VERSION "HNNBNNNYNNNNNNNNNNNNNNNNNNNNNNNNNNNNNNNNNN/4/%%%/4/'%**4NNN///"

NS_ :

BS_:

BU_: AFS Airbag Allrad BAP_Tester BMS_Hybrid Bremse_MK60EC Bremse_MK70MABS Bremse_TRW_EBC450M Bremse_TRW_ESP Daempfer EPB_TRW EPB_TRW_VW411CS FLA Gateway_PQ35 Gateway_Zusatz_EGolf Getriebe_AG6 Getriebe_DQ Getriebe_DQ_Hyb Getriebe_Sele Gurtmikro_PQ35 HCA Ladegeraet_EGolf LEH_Hybrid LH_EPS_APA LH_EPS_ZF_2G LH_EPS_ZF_3G LPG_Interface_Box LWR LWS Magne_Ride Motor_Diesel Motor_EGolf Motor_Hybrid Motor_Otto PDC_PLA Quersperre_VAQ RKA_Plus SAK Waehlhebel Waehlhebel_Sele

BO_ 1652 BAP_ACC: 8 Vector__XXX
 SG_ BAP_Data_ACC : 0|16@1+ (1,0) [0|65535] ""  Gateway_PQ35

BO_ 1654 BAP_Anzeige: 8 Gateway_PQ35
 SG_ BAP_Data_Anzeige : 0|16@1+ (1,0) [0|65535] ""  HCA,Motor_EGolf,Motor_Hybrid,PDC_PLA

BO_ 1658 BAP_Anzeige_02: 8 Gateway_PQ35
 SG_ BAP_Data_Anzeige_02 : 0|16@1+ (1,0) [0|65535] ""  Motor_EGolf,Motor_Hybrid,PDC_PLA

BO_ 1750 BAP_Debug_Cmd: 8 BAP_Tester
 SG_ BAP_Data_Debug_Cmd : 0|16@1+ (1,0) [0|65535] ""  HCA,Motor_EGolf,Motor_Hybrid,PDC_PLA

BO_ 1751 BAP_Debug_Data: 8 HCA
 SG_ BAP_Debug_Data : 0|64@1+ (1,0) [0|1.84467440737096E+019] ""  BAP_Tester

BO_ 1657 BAP_HYB: 8 Motor_EGolf
 SG_ BAP_Data_HYB : 0|16@1+ (1,0) [0|65535] ""  Gateway_PQ35

BO_ 1651 BAP_LDW: 8 HCA
 SG_ BAP_Data_LDW : 0|16@1+ (1,0) [0|65535] ""  Gateway_PQ35

BO_ 1754 BAP_OPS: 8 PDC_PLA
 SG_ BAP_Data_OPS : 0|16@1+ (1,0) [0|65535] ""  Gateway_PQ35

BO_ 946 BEM_03: 8 Gateway_PQ35
 SG_ BEM_HYB_DC_uMinLV : 12|8@1+ (0.1,0) [0|25.3] "Unit_Volt"  LEH_Hybrid
 SG_ BEM_HYB_DC_uSollLV : 20|6@1+ (0.1,10.6) [10.6|16] "Unit_Volt"  LEH_Hybrid

BO_ 901 Charisma_01: 8 Ladegeraet_EGolf
 SG_ CHA_Ziel_FahrPr_MO : 16|3@1+ (1,0) [0|7] ""  Motor_EGolf
 SG_ CHA_Ziel_FahrPr_GE : 20|3@1+ (1,0) [0|7] ""  Motor_EGolf

BO_ 902 Charisma_03: 8 Ladegeraet_EGolf
 SG_ CHA_Ziel_FahrPr_KL : 16|3@1+ (1,0) [0|7] ""  Gateway_Zusatz_EGolf
 SG_ CHA_Kombi_Texte : 24|4@1+ (1,0) [0|15] ""  Gateway_Zusatz_EGolf

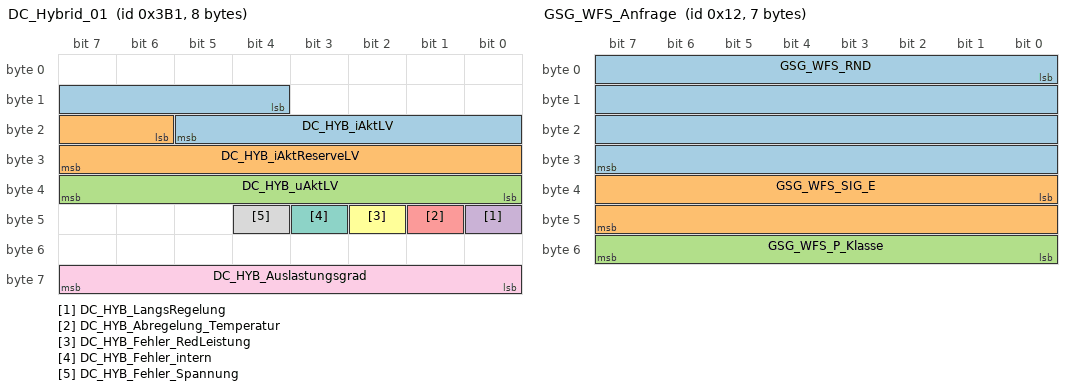
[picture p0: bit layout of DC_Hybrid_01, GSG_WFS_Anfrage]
BO_ 945 DC_Hybrid_01: 8 LEH_Hybrid
 SG_ DC_HYB_iAktLV : 12|10@1+ (1,-511) [-511|510] "Unit_Amper"  Gateway_PQ35
 SG_ DC_HYB_iAktReserveLV : 22|10@1+ (1,-511) [-511|510] "Unit_Amper"  Gateway_PQ35
 SG_ DC_HYB_uAktLV : 32|8@1+ (0.1,0) [0|25.3] "Unit_Volt"  Gateway_PQ35
 SG_ DC_HYB_LangsRegelung : 40|1@1+ (1,0) [0|1] ""  Gateway_PQ35
 SG_ DC_HYB_Abregelung_Temperatur : 41|1@1+ (1,0) [0|1] ""  Gateway_PQ35
 SG_ DC_HYB_Fehler_RedLeistung : 42|1@1+ (1,0) [0|1] ""  Gateway_PQ35
 SG_ DC_HYB_Fehler_intern : 43|1@1+ (1,0) [0|1] ""  Gateway_PQ35
 SG_ DC_HYB_Fehler_Spannung : 44|1@1+ (1,0) [0|1] ""  Gateway_PQ35
 SG_ DC_HYB_Auslastungsgrad : 56|8@1+ (0.4,0) [0|100] "Unit_PerCent"  Gateway_PQ35

BO_ 18 GSG_WFS_Anfrage: 7 Vector__XXX
 SG_ GSG_WFS_RND : 0|32@1+ (1,0) [0|4294967295] ""  Gateway_PQ35
 SG_ GSG_WFS_SIG_E : 32|16@1+ (1,0) [0|65535] ""  Gateway_PQ35
 SG_ GSG_WFS_P_Klasse : 48|8@1+ (1,0) [0|255] ""  Gateway_PQ35

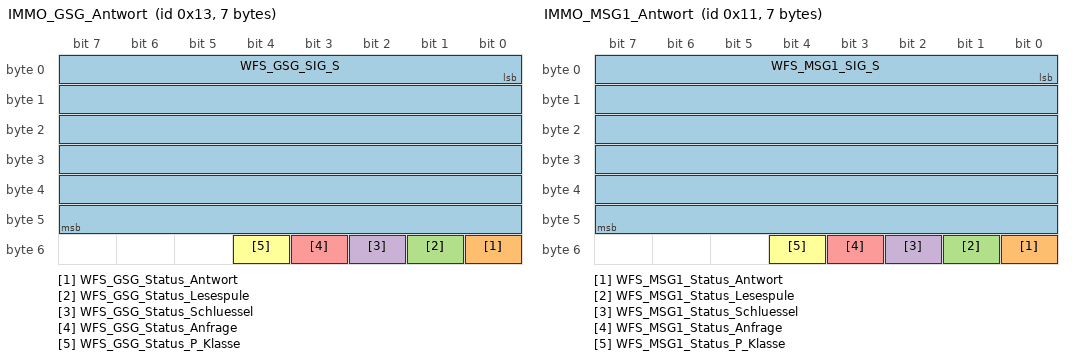
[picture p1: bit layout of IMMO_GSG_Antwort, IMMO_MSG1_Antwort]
BO_ 19 IMMO_GSG_Antwort: 7 Gateway_PQ35
 SG_ WFS_GSG_SIG_S : 0|48@1+ (1,0) [0|281474976710655] "" Vector__XXX
 SG_ WFS_GSG_Status_Antwort : 48|1@1+ (1,0) [0|1] "" Vector__XXX
 SG_ WFS_GSG_Status_Lesespule : 49|1@1+ (1,0) [0|1] "" Vector__XXX
 SG_ WFS_GSG_Status_Schluessel : 50|1@1+ (1,0) [0|1] "" Vector__XXX
 SG_ WFS_GSG_Status_Anfrage : 51|1@1+ (1,0) [0|1] "" Vector__XXX
 SG_ WFS_GSG_Status_P_Klasse : 52|1@1+ (1,0) [0|1] "" Vector__XXX

BO_ 17 IMMO_MSG1_Antwort: 7 Gateway_PQ35
 SG_ WFS_MSG1_SIG_S : 0|48@1+ (1,0) [0|281474976710655] "" Vector__XXX
 SG_ WFS_MSG1_Status_Antwort : 48|1@1+ (1,0) [0|1] "" Vector__XXX
 SG_ WFS_MSG1_Status_Lesespule : 49|1@1+ (1,0) [0|1] "" Vector__XXX
 SG_ WFS_MSG1_Status_Schluessel : 50|1@1+ (1,0) [0|1] "" Vector__XXX
 SG_ WFS_MSG1_Status_Anfrage : 51|1@1+ (1,0) [0|1] "" Vector__XXX
 SG_ WFS_MSG1_Status_P_Klasse : 52|1@1+ (1,0) [0|1] "" Vector__XXX

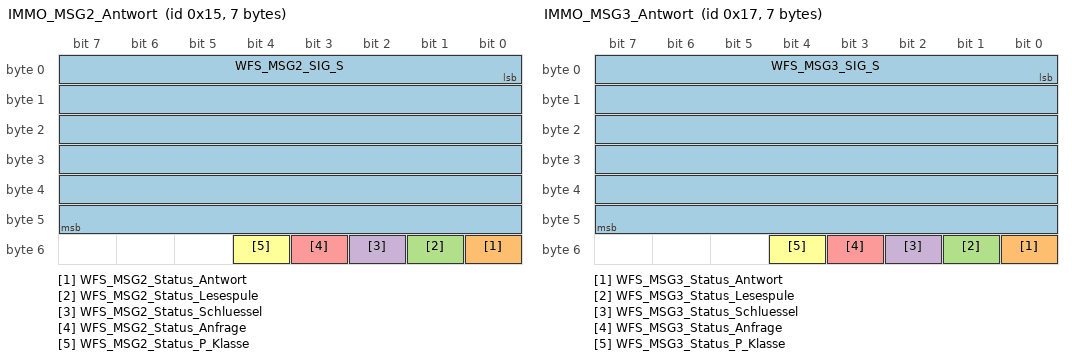
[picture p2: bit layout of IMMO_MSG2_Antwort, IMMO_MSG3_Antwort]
BO_ 21 IMMO_MSG2_Antwort: 7 Gateway_PQ35
 SG_ WFS_MSG2_SIG_S : 0|48@1+ (1,0) [0|281474976710655] "" Vector__XXX
 SG_ WFS_MSG2_Status_Antwort : 48|1@1+ (1,0) [0|1] "" Vector__XXX
 SG_ WFS_MSG2_Status_Lesespule : 49|1@1+ (1,0) [0|1] "" Vector__XXX
 SG_ WFS_MSG2_Status_Schluessel : 50|1@1+ (1,0) [0|1] "" Vector__XXX
 SG_ WFS_MSG2_Status_Anfrage : 51|1@1+ (1,0) [0|1] "" Vector__XXX
 SG_ WFS_MSG2_Status_P_Klasse : 52|1@1+ (1,0) [0|1] "" Vector__XXX

BO_ 23 IMMO_MSG3_Antwort: 7 Gateway_PQ35
 SG_ WFS_MSG3_SIG_S : 0|48@1+ (1,0) [0|281474976710655] "" Vector__XXX
 SG_ WFS_MSG3_Status_Antwort : 48|1@1+ (1,0) [0|1] "" Vector__XXX
 SG_ WFS_MSG3_Status_Lesespule : 49|1@1+ (1,0) [0|1] "" Vector__XXX
 SG_ WFS_MSG3_Status_Schluessel : 50|1@1+ (1,0) [0|1] "" Vector__XXX
 SG_ WFS_MSG3_Status_Anfrage : 51|1@1+ (1,0) [0|1] "" Vector__XXX
 SG_ WFS_MSG3_Status_P_Klasse : 52|1@1+ (1,0) [0|1] "" Vector__XXX

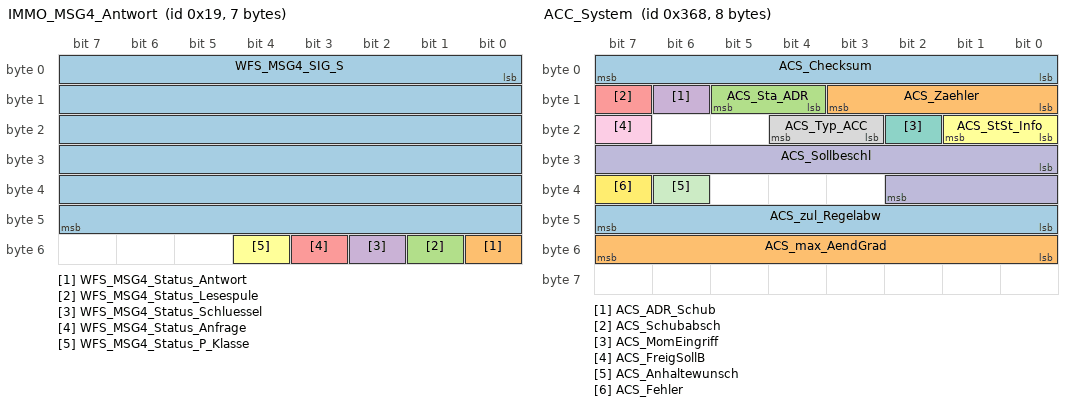
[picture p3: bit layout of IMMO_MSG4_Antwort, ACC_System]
BO_ 25 IMMO_MSG4_Antwort: 7 Gateway_PQ35
 SG_ WFS_MSG4_SIG_S : 0|48@1+ (1,0) [0|281474976710655] "" Vector__XXX
 SG_ WFS_MSG4_Status_Antwort : 48|1@1+ (1,0) [0|1] "" Vector__XXX
 SG_ WFS_MSG4_Status_Lesespule : 49|1@1+ (1,0) [0|1] "" Vector__XXX
 SG_ WFS_MSG4_Status_Schluessel : 50|1@1+ (1,0) [0|1] "" Vector__XXX
 SG_ WFS_MSG4_Status_Anfrage : 51|1@1+ (1,0) [0|1] "" Vector__XXX
 SG_ WFS_MSG4_Status_P_Klasse : 52|1@1+ (1,0) [0|1] "" Vector__XXX

BO_ 1811 ISO_ABS_Req: 8 Gateway_PQ35
 SG_ ISO_ABS_Req_Data : 0|64@1+ (1,0) [0|1.84467440737096E+019] "" Vector__XXX

BO_ 1917 ISO_ABS_Resp: 8 Vector__XXX
 SG_ ISO_ABS_Resp_Data : 0|64@1+ (1,0) [0|1.84467440737096E+019] ""  Gateway_PQ35

BO_ 1879 ISO_ACC_Req: 8 Gateway_PQ35
 SG_ ISO_ACC_Req_Data : 0|64@1+ (1,0) [0|1.84467440737096E+019] "" Vector__XXX

BO_ 1985 ISO_ACC_Resp: 8 Vector__XXX
 SG_ ISO_ACC_Resp_Data : 0|64@1+ (1,0) [0|1.84467440737096E+019] ""  Gateway_PQ35

BO_ 1813 ISO_Airbag_01_Req: 8 Gateway_PQ35
 SG_ ISO_Airbag_01_Req_Data : 0|64@1+ (1,0) [0|1.84467440737096E+019] ""  Airbag

BO_ 1919 ISO_Airbag_01_Resp: 8 Airbag
 SG_ ISO_Airbag_01_Resp_Data : 0|64@1+ (1,0) [0|1.84467440737096E+019] ""  Gateway_PQ35

BO_ 1874 ISO_EPB_Req: 8 Gateway_PQ35
 SG_ ISO_EPB_Req_Data : 0|64@1+ (1,0) [0|1.84467440737096E+019] ""  EPB_TRW_VW411CS,RKA_Plus

BO_ 1980 ISO_EPB_Resp: 8 EPB_TRW_VW411CS
 SG_ ISO_EPB_Resp_Data : 0|64@1+ (1,0) [0|1.84467440737096E+019] ""  Gateway_PQ35

BO_ 1802 ISO_EPH_Req: 8 Gateway_PQ35
 SG_ ISO_EPH_Req_Data : 0|64@1+ (1,0) [0|1.84467440737096E+019] ""  PDC_PLA

BO_ 1908 ISO_EPH_Resp: 8 PDC_PLA
 SG_ ISO_EPH_Resp_Data : 0|64@1+ (1,0) [0|1.84467440737096E+019] ""  Gateway_PQ35

BO_ 1792 ISO_Funktionaler_Req_All: 8 Gateway_PQ35
 SG_ ISO_ALL_01_Req_Data : 0|64@1+ (1,0) [0|1.84467440737096E+019] ""  AFS,Airbag,BMS_Hybrid,EPB_TRW_VW411CS,Getriebe_AG6,Getriebe_DQ,Getriebe_DQ_Hyb,Getriebe_Sele,Gurtmikro_PQ35,Ladegeraet_EGolf,LEH_Hybrid,LH_EPS_ZF_3G,Motor_Diesel,Motor_EGolf,Motor_Hybrid,Motor_Otto,PDC_PLA

BO_ 2015 ISO_Funktionaler_Req_OBD: 8 Gateway_PQ35
 SG_ ISO_OBD_01_Req_Data : 0|64@1+ (1,0) [0|1.84467440737096E+019] ""  BMS_Hybrid,Getriebe_AG6,Getriebe_DQ,Getriebe_DQ_Hyb,Getriebe_Sele,LEH_Hybrid,Motor_Diesel,Motor_EGolf,Motor_Hybrid,Motor_Otto

BO_ 2017 ISO_Getriebe_01_Req: 8 Gateway_PQ35
 SG_ ISO_Getriebe_01_Req_Data : 0|64@1+ (1,0) [0|1.84467440737096E+019] ""  Getriebe_AG6,Getriebe_DQ,Getriebe_DQ_Hyb,Getriebe_Sele

BO_ 2025 ISO_Getriebe_01_Resp: 8 Getriebe_AG6
 SG_ ISO_Getriebe_01_Resp_Data : 0|64@1+ (1,0) [0|1.84467440737096E+019] ""  Gateway_PQ35

BO_ 1891 ISO_Gurtmikro_Req: 8 Gateway_PQ35
 SG_ ISO_Gurtmikro_Req_Data : 0|64@1+ (1,0) [0|1.84467440737096E+019] ""  Gurtmikro_PQ35

BO_ 1997 ISO_Gurtmikro_Resp: 8 Gurtmikro_PQ35
 SG_ ISO_Gurtmikro_Resp_Data : 0|64@1+ (1,0) [0|1.84467440737096E+019] ""  Gateway_PQ35

BO_ 1893 ISO_Ladegeraet_Req: 8 Gateway_Zusatz_EGolf
 SG_ ISO_Ladegeraet_Req_Data : 0|64@1+ (1,0) [0|1.84467440737096E+019] ""  Ladegeraet_EGolf

BO_ 1999 ISO_Ladegeraet_Resp: 8 Ladegeraet_EGolf
 SG_ ISO_Ladegeraet_Resp_Data : 0|64@1+ (1,0) [0|1.84467440737096E+019] ""  Gateway_Zusatz_EGolf

BO_ 1810 ISO_Lenkhilfe_Req: 8 Gateway_PQ35
 SG_ ISO_Lenkhilfe_Req_Data : 0|64@1+ (1,0) [0|1.84467440737096E+019] ""  LH_EPS_ZF_3G

BO_ 1916 ISO_Lenkhilfe_Resp: 8 LH_EPS_ZF_3G
 SG_ ISO_Lenkhilfe_Resp_Data : 0|64@1+ (1,0) [0|1.84467440737096E+019] ""  Gateway_PQ35

BO_ 1876 ISO_LWRAFS_Req: 8 Gateway_PQ35
 SG_ ISO_LWRAFS_Req_Data : 0|64@1+ (1,0) [0|1.84467440737096E+019] ""  AFS

BO_ 1982 ISO_LWRAFS_Resp: 8 AFS
 SG_ ISO_LWRAFS_Resp_Data : 0|64@1+ (1,0) [0|1.84467440737096E+019] ""  Gateway_PQ35

BO_ 2016 ISO_MO_01_Req: 8 Gateway_PQ35
 SG_ ISO_MO_01_Req_Data : 0|64@1+ (1,0) [0|1.84467440737096E+019] ""  Motor_Diesel,Motor_EGolf,Motor_Hybrid,Motor_Otto

BO_ 2024 ISO_MO_01_Resp: 8 Motor_Diesel
 SG_ ISO_MO_01_Resp_Data : 0|64@1+ (1,0) [0|1.84467440737096E+019] ""  Gateway_PQ35

BO_ 2018 ISO_MOS_01_Req: 8 Gateway_PQ35
 SG_ ISO_MOS_01_Req_Data : 0|64@1+ (1,0) [0|1.84467440737096E+019] "" Vector__XXX

BO_ 2026 ISO_MOS_01_Resp: 8 Vector__XXX
 SG_ ISO_MOS_01_Resp_Data : 0|64@1+ (1,0) [0|1.84467440737096E+019] ""  Gateway_PQ35

BO_ 2021 ISO_OBD_BECM_Req: 8 Gateway_PQ35
 SG_ ISO_OBD_BECM_Req_Data : 0|64@1+ (1,0) [0|1.84467440737096E+019] ""  BMS_Hybrid

BO_ 2029 ISO_OBD_BECM_Resp: 8 BMS_Hybrid
 SG_ ISO_OBD_BECM_Resp_Data : 0|64@1+ (1,0) [0|1.84467440737096E+019] ""  Gateway_PQ35

BO_ 2022 ISO_OBD_DMCM_Req: 8 Gateway_PQ35
 SG_ ISO_OBD_DMCM_Req_Data : 0|64@1+ (1,0) [0|1.84467440737096E+019] ""  LEH_Hybrid

BO_ 2030 ISO_OBD_DMCM_Resp: 8 LEH_Hybrid
 SG_ ISO_OBD_DMCM_Resp_Data : 0|64@1+ (1,0) [0|1.84467440737096E+019] ""  Gateway_PQ35

BO_ 2019 ISO_OBD_reserv1_Req: 8 Gateway_PQ35
 SG_ ISO_OBD_reserv1_Req_Data : 0|64@1+ (1,0) [0|1.84467440737096E+019] "" Vector__XXX

BO_ 2027 ISO_OBD_reserv1_Resp: 8 Vector__XXX
 SG_ ISO_OBD_reserv1_Resp_Data : 0|64@1+ (1,0) [0|1.84467440737096E+019] ""  Gateway_PQ35

BO_ 2020 ISO_OBD_reserv2_Req: 8 Gateway_PQ35
 SG_ ISO_OBD_reserv2_Req_Data : 0|64@1+ (1,0) [0|1.84467440737096E+019] "" Vector__XXX

BO_ 2028 ISO_OBD_reserv2_Resp: 8 Vector__XXX
 SG_ ISO_OBD_reserv2_Resp_Data : 0|64@1+ (1,0) [0|1.84467440737096E+019] ""  Gateway_PQ35

BO_ 2023 ISO_OBD_reserv5_Req: 8 Gateway_PQ35
 SG_ ISO_OBD_reserv5_Req_Data : 0|64@1+ (1,0) [0|1.84467440737096E+019] "" Vector__XXX

BO_ 2031 ISO_OBD_reserv5_Resp: 8 Vector__XXX
 SG_ ISO_OBD_reserv5_Resp_Data : 0|64@1+ (1,0) [0|1.84467440737096E+019] ""  Gateway_PQ35

BO_ 1386 ACC_GRA_Anzeige: 8 Gateway_PQ35
 SG_ ACA_Checksum : 0|8@1+ (1,0) [0|255] ""  Gateway_PQ35
 SG_ ACA_StaACC : 8|3@1+ (1,0) [0|7] ""  Gateway_PQ35
 SG_ ACA_ID_StaACC : 11|5@1+ (1,0) [0|31] ""  Gateway_PQ35
 SG_ ACA_Fahrerhinw : 16|1@1+ (1,0) [0|1] ""  Gateway_PQ35
 SG_ ACA_AnzDisplay : 17|1@1+ (1,0) [0|1] ""  Gateway_PQ35
 SG_ ACA_Zeitluecke : 18|4@1+ (1,0) [0|15] ""  Gateway_PQ35
 SG_ ACA_V_Wunsch : 24|8@1+ (1,0) [0|254] "Unit_KiloMeterPerHour"  Gateway_PQ35,Getriebe_AG6,Getriebe_DQ,Getriebe_DQ_Hyb
 SG_ ACA_kmh_mph : 32|1@1+ (1,0) [0|1] ""  Gateway_PQ35
 SG_ ACA_Akustik1 : 33|1@1+ (1,0) [0|1] ""  Gateway_PQ35
 SG_ ACA_Akustik2 : 34|1@1+ (1,0) [0|1] ""  Gateway_PQ35
 SG_ ACA_PrioDisp : 35|2@1+ (1,0) [0|3] ""  Gateway_PQ35
 SG_ ACA_gemZeitl : 40|4@1+ (1,0) [0|15] ""  Gateway_PQ35
 SG_ ACA_ACC_Verz : 44|1@1+ (1,0) [0|1] ""  Gateway_PQ35
 SG_ ACA_StaGRA : 48|3@1+ (1,0) [0|7] ""  Gateway_PQ35
 SG_ ACA_ID_StaGRA : 51|5@1+ (1,0) [0|31] ""  Gateway_PQ35
 SG_ ACA_Codierung : 56|1@1+ (1,0) [0|1] ""  Gateway_PQ35,Getriebe_DQ
 SG_ ACA_Tachokranz : 57|1@1+ (1,0) [0|1] ""  Gateway_PQ35
 SG_ ACA_Aend_Zeitluecke : 58|1@1+ (1,0) [0|1] ""  Gateway_PQ35
 SG_ ACA_Zaehler : 60|4@1+ (1,0) [0|15] ""  Gateway_PQ35

BO_ 872 ACC_System: 8 Gateway_PQ35
 SG_ ACS_Checksum : 0|8@1+ (1,0) [0|255] ""  Daempfer,Getriebe_DQ,Motor_Diesel,Motor_Otto
 SG_ ACS_Zaehler : 8|4@1+ (1,0) [0|15] ""  Daempfer,Getriebe_DQ,Motor_Diesel,Motor_Otto
 SG_ ACS_Sta_ADR : 12|2@1+ (1,0) [0|3] ""  Getriebe_AG6,Getriebe_DQ,Motor_Diesel,Motor_Otto
 SG_ ACS_ADR_Schub : 14|1@1+ (1,0) [0|1] ""  Getriebe_AG6,Getriebe_DQ,Motor_Diesel,Motor_Otto
 SG_ ACS_Schubabsch : 15|1@1+ (1,0) [0|1] ""  Getriebe_AG6,Getriebe_DQ,Motor_Diesel,Motor_Otto
 SG_ ACS_StSt_Info : 16|2@1+ (1,0) [0|3] ""  Motor_Diesel,Motor_Otto
 SG_ ACS_MomEingriff : 18|1@1+ (1,0) [0|1] ""  Getriebe_AG6,Getriebe_DQ,Motor_Diesel,Motor_Otto
 SG_ ACS_Typ_ACC : 19|2@1+ (1,0) [0|3] ""  Getriebe_AG6,Getriebe_DQ,Motor_Diesel,Motor_Otto
 SG_ ACS_FreigSollB : 23|1@1+ (1,0) [0|1] ""  Daempfer,Getriebe_AG6,Getriebe_DQ,Motor_Diesel,Motor_Otto
 SG_ ACS_Sollbeschl : 24|11@1+ (0.005,-7.22) [-7.22|3.005] "Unit_MeterPerSeconSquar"  Daempfer,Getriebe_AG6,Getriebe_DQ,Motor_Diesel,Motor_Otto
 SG_ ACS_Anhaltewunsch : 38|1@1+ (1,0) [0|1] ""  Motor_Diesel,Motor_Otto
 SG_ ACS_Fehler : 39|1@1+ (1,0) [0|1] ""  Gateway_PQ35
 SG_ ACS_zul_Regelabw : 40|8@1+ (0.005,0) [0|1.265] "Unit_MeterPerSeconSquar"  Motor_Diesel,Motor_Otto
 SG_ ACS_max_AendGrad : 48|8@1+ (0.02,0) [0.02|5.06] "Unit_MeterPerSeconSquar"  Motor_Diesel,Motor_Otto

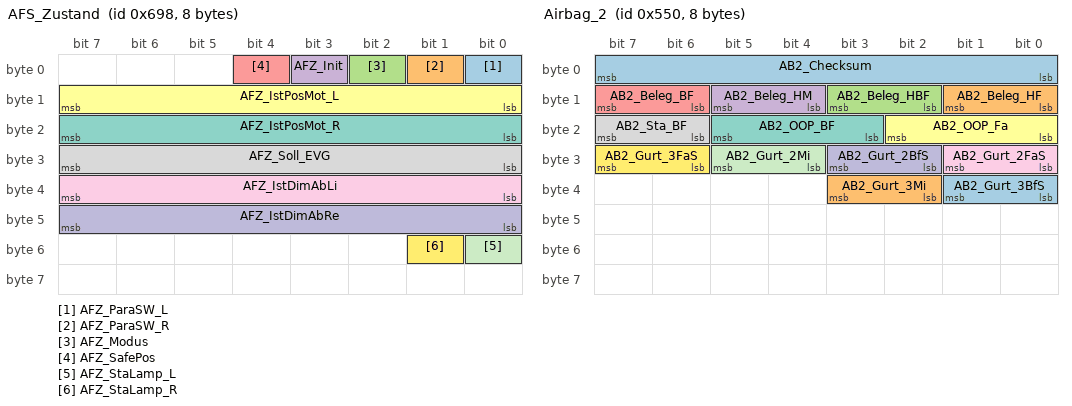
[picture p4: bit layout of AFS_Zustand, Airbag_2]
BO_ 1688 AFS_Zustand: 8 AFS
 SG_ AFZ_ParaSW_L : 0|1@1+ (1,0) [0|1] "" Vector__XXX
 SG_ AFZ_ParaSW_R : 1|1@1+ (1,0) [0|1] "" Vector__XXX
 SG_ AFZ_Modus : 2|1@1+ (1,0) [0|1] "" Vector__XXX
 SG_ AFZ_Init : 3|1@1+ (1,0) [0|1] "" Vector__XXX
 SG_ AFZ_SafePos : 4|1@1+ (1,0) [0|1] "" Vector__XXX
 SG_ AFZ_IstPosMot_L : 8|8@1+ (0.4,0) [0|100] "Unit_PerCent" Vector__XXX
 SG_ AFZ_IstPosMot_R : 16|8@1+ (0.4,0) [0|100] "Unit_PerCent" Vector__XXX
 SG_ AFZ_Soll_EVG : 24|8@1+ (0.4,0) [0|100] "Unit_PerCent" Vector__XXX
 SG_ AFZ_IstDimAbLi : 32|8@1+ (0.4,0) [0|100] "Unit_PerCent" Vector__XXX
 SG_ AFZ_IstDimAbRe : 40|8@1+ (0.4,0) [0|100] "Unit_PerCent" Vector__XXX
 SG_ AFZ_StaLamp_L : 48|1@1+ (1,0) [0|1] "" Vector__XXX
 SG_ AFZ_StaLamp_R : 49|1@1+ (1,0) [0|1] "" Vector__XXX

BO_ 80 Airbag_1: 4 Airbag
 SG_ AB1_Front : 0|1@1+ (1,0) [0|1] ""  BMS_Hybrid,Bremse_TRW_EBC450M,Bremse_TRW_ESP,EPB_TRW,Gateway_PQ35,HCA,LEH_Hybrid
 SG_ AB1_Heck : 1|1@1+ (1,0) [0|1] ""  BMS_Hybrid,Bremse_TRW_EBC450M,Bremse_TRW_ESP,EPB_TRW,Gateway_PQ35,HCA,LEH_Hybrid
 SG_ AB1_Fa_Seite : 2|1@1+ (1,0) [0|1] ""  BMS_Hybrid,Bremse_TRW_EBC450M,Bremse_TRW_ESP,EPB_TRW,Gateway_PQ35,HCA,LEH_Hybrid
 SG_ AB1_Bf_Seite : 3|1@1+ (1,0) [0|1] ""  BMS_Hybrid,Bremse_TRW_EBC450M,Bremse_TRW_ESP,EPB_TRW,Gateway_PQ35,HCA,LEH_Hybrid
 SG_ AB1_Rollover : 4|1@1+ (1,0) [0|1] ""  Bremse_MK60EC,Bremse_MK70MABS,Bremse_TRW_EBC450M,Bremse_TRW_ESP,EPB_TRW,Gateway_PQ35
 SG_ AB1_Intens : 5|3@1+ (1,0) [0|7] ""  Bremse_MK60EC,Bremse_MK70MABS,Gateway_PQ35,Gurtmikro_PQ35,LEH_Hybrid,Motor_Diesel,Motor_EGolf,Motor_Hybrid,Motor_Otto
 SG_ AB1_Lampe : 8|1@1+ (1,0) [0|1] ""  Gateway_PQ35
 SG_ AB1_Status : 9|1@1+ (1,0) [0|1] ""  Gateway_PQ35
 SG_ AB1_Beifahrer : 10|1@1+ (1,0) [0|1] ""  Gateway_PQ35
 SG_ AB1_System : 11|1@1+ (1,0) [0|1] ""  BMS_Hybrid,Gateway_PQ35,HCA,LEH_Hybrid
 SG_ AB1_Gurt_Fa : 12|2@1+ (1,0) [0|3] ""  Bremse_MK60EC,Bremse_TRW_EBC450M,Bremse_TRW_ESP,EPB_TRW,EPB_TRW_VW411CS,Gateway_PQ35,Gurtmikro_PQ35,Motor_Diesel,Motor_EGolf,Motor_Hybrid,Motor_Otto
 SG_ AB1_Gurt_Bf : 14|2@1+ (1,0) [0|3] ""  Gateway_PQ35,Gurtmikro_PQ35
 SG_ AB1_Diagnose : 16|1@1+ (1,0) [0|1] ""  EPB_TRW,Gateway_PQ35
 SG_ AB1_Stellglied : 17|1@1+ (1,0) [0|1] ""  BMS_Hybrid,Gateway_PQ35,LEH_Hybrid,Motor_Diesel,Motor_Otto
 SG_ AB1_BF_Warnung : 18|1@1+ (1,0) [0|1] ""  Gateway_PQ35
 SG_ AB1_Fehlereintr : 19|1@1+ (1,0) [0|1] ""  Gateway_PQ35
 SG_ AB1_Zaehler : 20|4@1+ (1,0) [0|15] ""  BMS_Hybrid,Bremse_MK60EC,Bremse_TRW_EBC450M,Bremse_TRW_ESP,EPB_TRW,EPB_TRW_VW411CS,Gateway_PQ35,HCA,LEH_Hybrid,Motor_Diesel,Motor_EGolf,Motor_Hybrid,Motor_Otto
 SG_ AB1_Checksumme : 24|8@1+ (1,0) [0|255] ""  BMS_Hybrid,Bremse_MK60EC,Bremse_TRW_EBC450M,Bremse_TRW_ESP,EPB_TRW,EPB_TRW_VW411CS,Gateway_PQ35,HCA,LEH_Hybrid,Motor_Diesel,Motor_EGolf,Motor_Hybrid,Motor_Otto

BO_ 1360 Airbag_2: 8 Airbag
 SG_ AB2_Checksum : 0|8@1+ (1,0) [0|255] ""  Gateway_PQ35
 SG_ AB2_Beleg_HF : 8|2@1+ (1,0) [0|3] ""  Gateway_PQ35
 SG_ AB2_Beleg_HBF : 10|2@1+ (1,0) [0|3] ""  Gateway_PQ35
 SG_ AB2_Beleg_HM : 12|2@1+ (1,0) [0|3] ""  Gateway_PQ35
 SG_ AB2_Beleg_BF : 14|2@1+ (1,0) [0|3] ""  Gateway_PQ35,Gurtmikro_PQ35
 SG_ AB2_OOP_Fa : 16|3@1+ (1,0) [0|7] ""  Gateway_PQ35
 SG_ AB2_OOP_BF : 19|3@1+ (1,0) [0|7] ""  Gateway_PQ35
 SG_ AB2_Sta_BF : 22|2@1+ (1,0) [0|3] ""  Gateway_PQ35
 SG_ AB2_Gurt_2FaS : 24|2@1+ (1,0) [0|3] ""  Gateway_PQ35
 SG_ AB2_Gurt_2BfS : 26|2@1+ (1,0) [0|3] ""  Gateway_PQ35
 SG_ AB2_Gurt_2Mi : 28|2@1+ (1,0) [0|3] ""  Gateway_PQ35
 SG_ AB2_Gurt_3FaS : 30|2@1+ (1,0) [0|3] ""  Gateway_PQ35
 SG_ AB2_Gurt_3BfS : 32|2@1+ (1,0) [0|3] ""  Gateway_PQ35
 SG_ AB2_Gurt_3Mi : 34|2@1+ (1,0) [0|3] ""  Gateway_PQ35

BO_ 704 Allrad_1: 8 Allrad
 SG_ AL1_Fehler : 0|1@1+ (1,0) [0|1] ""  Bremse_MK60EC,Bremse_TRW_EBC450M,Bremse_TRW_ESP,Gateway_PQ35,RKA_Plus
 SG_ AL1_Uebertemp : 1|1@1+ (1,0) [0|1] ""  Bremse_TRW_EBC450M,Bremse_TRW_ESP,Gateway_PQ35
 SG_ AL1_Sta_Kup : 2|1@1+ (1,0) [0|1] ""  Bremse_MK60EC,Bremse_TRW_EBC450M,Bremse_TRW_ESP,Gateway_PQ35
 SG_ AL1_Kup_offen : 3|1@1+ (1,0) [0|1] ""  Bremse_TRW_EBC450M,Bremse_TRW_ESP,Gateway_PQ35,RKA_Plus
 SG_ AL1_Notlauf : 4|1@1+ (1,0) [0|1] ""  Bremse_TRW_EBC450M,Bremse_TRW_ESP,Gateway_PQ35
 SG_ AL1_Warnlampe : 5|1@1+ (1,0) [0|1] ""  Bremse_TRW_EBC450M,Bremse_TRW_ESP,Gateway_PQ35
 SG_ AL1_Limiter : 6|1@1+ (1,0) [0|1] ""  Gateway_PQ35
 SG_ AL1_Einheit M : 7|1@1+ (1,0) [0|1] ""  Bremse_MK60EC,Bremse_TRW_EBC450M,Bremse_TRW_ESP,Gateway_PQ35,RKA_Plus
 SG_ AL1_Ist_Nm m0 : 8|8@1+ (7,-896) [-896|882] "Unit_NewtoMeter"  Bremse_MK60EC,Bremse_TRW_EBC450M,Bremse_TRW_ESP,Gateway_PQ35,RKA_Plus
 SG_ AL1_Ist_Proz m1 : 8|8@1+ (0.794,-101.632) [0|100.044] "Unit_PerCent"  Bremse_MK60EC,Bremse_TRW_EBC450M,Bremse_TRW_ESP,Gateway_PQ35,RKA_Plus
 SG_ AL1_Sta_PNG : 16|3@1+ (1,0) [0|7] ""  Bremse_MK60EC,Gateway_PQ35,Getriebe_DQ,Getriebe_DQ_Hyb
 SG_ AL1_Anz_blinken : 19|1@1+ (1,0) [0|1] ""  Gateway_PQ35
 SG_ AL1_Sta_Laengssp : 20|2@1+ (1,0) [0|3] ""  Gateway_PQ35
 SG_ AL1_Sta_Quersp : 22|2@1+ (1,0) [0|3] ""  Gateway_PQ35
 SG_ AL1_Schalten : 24|1@1+ (1,0) [0|1] ""  Gateway_PQ35
 SG_ AL1_Vorwarnung : 25|1@1+ (1,0) [0|1] ""  Gateway_PQ35,Getriebe_DQ,Getriebe_DQ_Hyb
 SG_ AL1_Stellung_Getr : 26|1@1+ (1,0) [0|1] ""  Bremse_MK60EC,Gateway_PQ35
 SG_ AL1_AnfVerteiler : 27|1@1+ (1,0) [0|1] ""  Gateway_PQ35
 SG_ AL1_Sta_VA : 28|2@1+ (1,0) [0|3] ""  Gateway_PQ35
 SG_ AL1_KupSteifig_F : 30|1@1+ (1,0) [0|1] ""  Gateway_PQ35
 SG_ AL1_Fehlereintr : 31|1@1+ (1,0) [0|1] ""  Gateway_PQ35
 SG_ AL1_KupplTemp : 32|8@1+ (1,-60) [-60|193] "Unit_DegreCelsi"  Gateway_PQ35
 SG_ AL1_FaWu_Laengs : 40|2@1+ (1,0) [0|3] ""  Gateway_PQ35
 SG_ AL1_FaWu_HA : 42|2@1+ (1,0) [0|3] ""  Gateway_PQ35
 SG_ AL1_FaWu_VA : 44|2@1+ (1,0) [0|3] ""  Gateway_PQ35
 SG_ AL1_Quersp_Sta : 46|2@1+ (1,0) [0|3] ""  Gateway_PQ35
 SG_ AL1_Limit_maxkmh : 48|8@1+ (1,0) [0|254] ""  Gateway_PQ35
 SG_ AL1_Diff_Verbau : 56|1@1+ (1,0) [0|1] ""  Gateway_PQ35
 SG_ AL1_Diff_Lampe : 57|1@1+ (1,0) [0|1] ""  Gateway_PQ35
 SG_ AL1_Diff_Gong : 58|1@1+ (1,0) [0|1] ""  Gateway_PQ35
 SG_ AL1_Warnton : 59|1@1+ (1,0) [0|1] ""  Gateway_PQ35
 SG_ AL1_Zaehler : 60|4@1+ (1,0) [0|15] ""  Bremse_TRW_EBC450M,Bremse_TRW_ESP,Gateway_PQ35

BO_ 870 AWV: 8 Gateway_PQ35
 SG_ AWV_Checksumme : 0|8@1+ (1,0) [0|255] ""  Bremse_TRW_EBC450M,Bremse_TRW_ESP,Daempfer,Gateway_PQ35,HCA
 SG_ AWV_Zaehler : 8|4@1+ (1,0) [0|15] ""  Bremse_TRW_EBC450M,Bremse_TRW_ESP,Daempfer,Gateway_PQ35,HCA
 SG_ AWV_Text : 12|4@1+ (1,0) [0|15] ""  Gateway_PQ35
 SG_ AWV_1_Freigabe : 16|1@1+ (1,0) [0|1] ""  Bremse_TRW_EBC450M,Bremse_TRW_ESP,Gateway_PQ35
 SG_ AWV_1_Prefill : 17|1@1+ (1,0) [0|1] ""  Bremse_TRW_EBC450M,Bremse_TRW_ESP,Gateway_PQ35
 SG_ AWV_1_Parameter : 18|2@1+ (1,0) [0|3] ""  Bremse_TRW_EBC450M,Bremse_TRW_ESP,Gateway_PQ35
 SG_ AWV_Halten : 22|1@1+ (1,0) [0|1] ""  Bremse_TRW_EBC450M,Gateway_PQ35
 SG_ ANB_Teilbremsung_Freigabe : 23|1@1+ (1,0) [0|1] ""  Bremse_TRW_EBC450M,Daempfer,Gateway_PQ35
 SG_ AWV_2_Status : 24|1@1+ (1,0) [0|1] ""  Gateway_PQ35
 SG_ AWV_2_Fehler : 25|1@1+ (1,0) [0|1] ""  Gateway_PQ35
 SG_ AWV_2_SU_Warnzeit : 26|2@1+ (1,0) [0|3] ""  Gateway_PQ35
 SG_ AWV_2_SU_Bremsruck : 28|1@1+ (1,0) [0|1] ""  Gateway_PQ35
 SG_ AWV_2_SU_Gong : 29|1@1+ (1,0) [0|1] ""  Gateway_PQ35
 SG_ AWV_2_SU_Lampe : 30|1@1+ (1,0) [0|1] ""  Gateway_PQ35
 SG_ AWV_2_Umfeldwarn : 31|1@1+ (1,0) [0|1] ""  Gateway_PQ35
 SG_ AWV_2_Freigabe : 32|1@1+ (1,0) [0|1] ""  Bremse_TRW_EBC450M,Bremse_TRW_ESP,Gateway_PQ35,HCA
 SG_ AWV_2_Ruckprofil : 33|3@1+ (1,0) [0|7] ""  Bremse_TRW_EBC450M,Bremse_TRW_ESP,Gateway_PQ35
 SG_ AWV_2_Warnton : 36|1@1+ (1,0) [0|1] ""  Gateway_PQ35
 SG_ AWV_2_Warnsymbol : 37|1@1+ (1,0) [0|1] ""  Gateway_PQ35
 SG_ AWV_Infoton : 38|1@1+ (1,0) [0|1] ""  Gateway_PQ35
 SG_ AWV_2_Gurtstraffer : 39|1@1+ (1,0) [0|1] ""  Gateway_PQ35
 SG_ ANB_Zielbremsung_Freigabe : 52|1@1+ (1,0) [0|1] ""  Bremse_TRW_EBC450M,Daempfer,Gateway_PQ35
 SG_ ANB_CM_Anforderung : 53|1@1+ (1,0) [0|1] ""  Bremse_TRW_EBC450M,Gateway_PQ35
 SG_ ANB_Ziel_Teilbrems_Verz_Anf : 54|10@1+ (0.024,-20.016) [-20.016|4.536] "Unit_MeterPerSeconSquar"  Bremse_TRW_EBC450M,Daempfer,Gateway_PQ35

BO_ 1404 BMS_Hybrid_1: 1 BMS_Hybrid
 SG_ BY1_KD_Fehler : 0|1@1+ (1,0) [0|1] ""  Gateway_PQ35

BO_ 416 Bremse_1: 8 Bremse_MK60EC
 SG_ BR1_ASR_Anf : 0|1@1+ (1,0) [0|1] ""  Gateway_PQ35,Getriebe_DQ,Getriebe_DQ_Hyb,LH_EPS_APA,Motor_Diesel,Motor_EGolf,Motor_Hybrid,Motor_Otto,PDC_PLA,RKA_Plus
 SG_ BR1_MSR_Anf M : 1|1@1+ (1,0) [0|1] ""  Gateway_PQ35,Getriebe_DQ,Getriebe_DQ_Hyb,LH_EPS_APA,Motor_Diesel,Motor_EGolf,Motor_Hybrid,Motor_Otto,PDC_PLA,RKA_Plus
 SG_ BR1_ABS_Brems : 2|1@1+ (1,0) [0|1] ""  Allrad,Daempfer,EPB_TRW,EPB_TRW_VW411CS,Gateway_PQ35,Getriebe_DQ,Getriebe_DQ_Hyb,HCA,LH_EPS_APA,Magne_Ride,Motor_Diesel,Motor_EGolf,Motor_Hybrid,Motor_Otto,PDC_PLA,RKA_Plus
 SG_ BR1_EDS_Eingr : 3|1@1+ (1,0) [0|1] ""  Daempfer,Gateway_PQ35,Getriebe_DQ,Getriebe_DQ_Hyb,LH_EPS_APA,Motor_Diesel,Motor_EGolf,Motor_Hybrid,Motor_Otto,PDC_PLA,RKA_Plus
 SG_ BR1_ESP_Eingr : 4|1@1+ (1,0) [0|1] ""  AFS,Allrad,Daempfer,Gateway_PQ35,Getriebe_AG6,Getriebe_DQ,Getriebe_DQ_Hyb,Getriebe_Sele,HCA,LH_EPS_APA,LH_EPS_ZF_2G,LH_EPS_ZF_3G,Motor_Diesel,Motor_EGolf,Motor_Hybrid,Motor_Otto,PDC_PLA,RKA_Plus
 SG_ BR1_ASR_Eingr : 5|2@1+ (1,0) [0|3] ""  Gateway_PQ35,Getriebe_AG6,Getriebe_DQ,Getriebe_DQ_Hyb,LH_EPS_APA
 SG_ BR1_EBV_Eingr : 7|1@1+ (1,0) [0|1] ""  Daempfer,Gateway_PQ35,LH_EPS_APA,RKA_Plus
 SG_ BR1_Lampe_ABS : 8|1@1+ (1,0) [0|1] ""  Gateway_PQ35
 SG_ BR1_Lampe_ASR : 9|1@1+ (1,0) [0|1] ""  Gateway_PQ35
 SG_ BR1_Lampe_BK : 10|1@1+ (1,0) [0|1] ""  Gateway_PQ35
 SG_ BR1_Lichtschalt : 11|1@1+ (1,0) [0|1] ""  AFS,Gateway_PQ35,Gateway_Zusatz_EGolf,LH_EPS_APA,LH_EPS_ZF_2G,LH_EPS_ZF_3G,LWR,Motor_Diesel,Motor_EGolf,Motor_Hybrid,Motor_Otto,RKA_Plus
 SG_ BR1_StaDruckschw : 12|1@1+ (1,0) [0|1] ""  Gateway_PQ35,Motor_Diesel,Motor_EGolf,Motor_Hybrid,Motor_Otto
 SG_ BR1_MAD : 13|1@1+ (1,0) [0|1] ""  Gateway_PQ35
 SG_ BR1_Sta_MAD : 14|1@1+ (1,0) [0|1] ""  Gateway_PQ35
 SG_ BR1_Diagnose : 15|1@1+ (1,0) [0|1] ""  Airbag,Gateway_PQ35
 SG_ BR1_BKV_aktiv : 16|1@1+ (1,0) [0|1] ""  Gateway_PQ35,Motor_Diesel,Motor_EGolf,Motor_Hybrid,Motor_Otto
 SG_ BR1_Rad_kmh : 17|15@1+ (0.01,0) [0|326.39] "Unit_KiloMeterPerHour"  Airbag,BMS_Hybrid,Daempfer,FLA,Gateway_PQ35,Getriebe_AG6,Getriebe_DQ,Getriebe_DQ_Hyb,Getriebe_Sele,HCA,LEH_Hybrid,LH_EPS_APA,LH_EPS_ZF_2G,LH_EPS_ZF_3G,Magne_Ride,Motor_Diesel,Motor_EGolf,Motor_Hybrid,Motor_Otto,PDC_PLA,SAK
 SG_ BR1_ASRMo_sl : 32|8@1+ (0.39,0) [0|99.06] "Unit_PerCent"  Gateway_PQ35,Motor_EGolf,Motor_Hybrid,Motor_Otto
 SG_ BR1_ASRMo_fa m0 : 40|8@1+ (0.39,0) [0|99.06] "Unit_PerCent"  Gateway_PQ35,Motor_Diesel,Motor_EGolf,Motor_Hybrid,Motor_Otto
 SG_ BR1_MSR_Mo_inv m1 : 40|8@1+ (-0.39,99.45) [0|99.06] "Unit_PerCent"  Gateway_PQ35,Motor_Diesel,Motor_EGolf,Motor_Hybrid,Motor_Otto
 SG_ BR1_MSR_Mo : 48|8@1+ (0.39,0) [0|99.06] "Unit_PerCent"  Gateway_PQ35,Motor_Diesel,Motor_EGolf,Motor_Hybrid,Motor_Otto
 SG_ BR1_Zaehler : 56|4@1+ (1,0) [0|15] ""  Airbag,Daempfer,EPB_TRW,EPB_TRW_VW411CS,Gateway_PQ35,Getriebe_AG6,HCA,LH_EPS_APA,LH_EPS_ZF_2G,LH_EPS_ZF_3G,Magne_Ride,Motor_Diesel,Motor_EGolf,Motor_Hybrid,Motor_Otto,PDC_PLA
 SG_ BR1_ASR_ESP : 60|1@1+ (1,0) [0|1] ""  Gateway_PQ35
 SG_ BR1_ESPASR_passiv : 61|1@1+ (1,0) [0|1] ""  Gateway_PQ35,Getriebe_DQ,Getriebe_DQ_Hyb,Getriebe_Sele,HCA,Magne_Ride,Motor_Diesel,Motor_Otto,PDC_PLA
 SG_ BR1_Sta_ESP : 62|1@1+ (1,0) [0|1] ""  Gateway_PQ35,Getriebe_AG6,Getriebe_DQ,Getriebe_DQ_Hyb,Magne_Ride,Motor_Diesel,Motor_Otto,PDC_PLA,RKA_Plus
 SG_ BR1_Ersatz_Kmh : 63|1@1+ (1,0) [0|1] ""  Airbag,Gateway_PQ35,HCA,LH_EPS_APA,LH_EPS_ZF_2G,LH_EPS_ZF_3G,PDC_PLA

BO_ 928 Bremse_10: 8 Bremse_MK60EC
 SG_ B10_Checksumme : 0|8@1+ (1,0) [0|255] ""  Gateway_PQ35,Motor_Diesel,Motor_Otto,PDC_PLA
 SG_ B10_Zaehler : 8|4@1+ (1,0) [0|15] ""  Gateway_PQ35,Motor_Diesel,Motor_Otto,PDC_PLA
 SG_ B10_QB_Wegimp_VL : 12|1@1+ (1,0) [0|1] ""  Gateway_PQ35,Motor_Diesel,Motor_Otto,PDC_PLA
 SG_ B10_QB_Wegimp_VR : 13|1@1+ (1,0) [0|1] ""  Gateway_PQ35,Motor_Diesel,Motor_Otto,PDC_PLA
 SG_ B10_QB_Wegimp_HL : 14|1@1+ (1,0) [0|1] ""  Gateway_PQ35,Motor_Diesel,Motor_Otto,PDC_PLA
 SG_ B10_QB_Wegimp_HR : 15|1@1+ (1,0) [0|1] ""  Gateway_PQ35,Motor_Diesel,Motor_Otto,PDC_PLA
 SG_ B10_Wegimp_VL : 16|10@1+ (1,0) [0|1000] ""  Gateway_PQ35,Motor_Diesel,Motor_Otto,PDC_PLA
 SG_ B10_Wegimp_VR : 26|10@1+ (1,0) [0|1000] ""  Gateway_PQ35,Motor_Diesel,Motor_Otto,PDC_PLA
 SG_ B10_Wegimp_HL : 36|10@1+ (1,0) [0|1000] ""  Gateway_PQ35,Motor_Diesel,Motor_Otto,PDC_PLA
 SG_ B10_Wegimp_HR : 46|10@1+ (1,0) [0|1000] ""  Gateway_PQ35,Motor_Diesel,Motor_Otto,PDC_PLA
 SG_ B10_QB_Fahrtr_VL : 56|1@1+ (1,0) [0|1] ""  Gateway_PQ35,PDC_PLA
 SG_ B10_QB_Fahrtr_VR : 57|1@1+ (1,0) [0|1] ""  Gateway_PQ35,PDC_PLA
 SG_ B10_QB_Fahrtr_HL : 58|1@1+ (1,0) [0|1] ""  Gateway_PQ35,PDC_PLA
 SG_ B10_QB_Fahrtr_HR : 59|1@1+ (1,0) [0|1] ""  Gateway_PQ35,PDC_PLA
 SG_ B10_Fahrtr_VL : 60|1@1+ (1,0) [0|1] ""  Gateway_PQ35,PDC_PLA
 SG_ B10_Fahrtr_VR : 61|1@1+ (1,0) [0|1] ""  Gateway_PQ35,PDC_PLA
 SG_ B10_Fahrtr_HL : 62|1@1+ (1,0) [0|1] ""  Gateway_PQ35,PDC_PLA
 SG_ B10_Fahrtr_HR : 63|1@1+ (1,0) [0|1] ""  Gateway_PQ35,PDC_PLA

BO_TX_BU_ 1751 : HCA,Motor_EGolf,Motor_Hybrid,PDC_PLA;
BO_TX_BU_ 1657 : Motor_EGolf,Motor_Hybrid;
BO_TX_BU_ 2025 : Getriebe_AG6,Getriebe_DQ,Getriebe_DQ_Hyb,Getriebe_Sele;
BO_TX_BU_ 2024 : Motor_Diesel,Motor_EGolf,Motor_Hybrid,Motor_Otto;
BO_TX_BU_ 1386 : Gateway_PQ35,Motor_Diesel,Motor_Otto;
BO_TX_BU_ 416 : Bremse_MK60EC,Bremse_MK70MABS,Bremse_TRW_EBC450M,Bremse_TRW_ESP;
BO_TX_BU_ 928 : Bremse_MK60EC,Bremse_MK70MABS,Bremse_TRW_EBC450M,Bremse_TRW_ESP;

CM_ "PQ35_46_CAN_Antrieb_5.7.6 Generated by BUSNETPQ 7.3.2  © 2009 Sulzer GmbH";
CM_ BU_ AFS "PQ35_46 (mit AFS-SubCAN)";
CM_ BU_ Airbag "PQ35_46";
CM_ BU_ Allrad "PQ35_46";
CM_ BU_ BMS_Hybrid "PQ35";
CM_ BU_ Bremse_MK60EC "PQ35_46";
CM_ BU_ Bremse_MK70MABS "PQ35_46";
CM_ BU_ Bremse_TRW_EBC450M "PQ35_46";
CM_ BU_ Bremse_TRW_ESP "PQ35_46";
CM_ BU_ Daempfer "PQ35_46";
CM_ BU_ EPB_TRW "PQ35_46 am ESP-Sub-CAN";
CM_ BU_ EPB_TRW_VW411CS "PQ35_46";
CM_ BU_ FLA "PQ35_46";
CM_ BU_ Gateway_PQ35 "PQ35 und VW47x";
CM_ BU_ Gateway_Zusatz_EGolf "Zusätzliches Routingmodul für EGolf";
CM_ BU_ Getriebe_AG6 "PQ35_46";
CM_ BU_ Getriebe_DQ "PQ35_46";
CM_ BU_ Getriebe_DQ_Hyb "PQ35";
CM_ BU_ Getriebe_Sele "Audi PQ35";
CM_ BU_ HCA "PQ46";
CM_ BU_ LEH_Hybrid "PQ35";
CM_ BU_ LH_EPS_APA "PQ35_46";
CM_ BU_ LH_EPS_ZF_2G "PQ35_46";
CM_ BU_ LH_EPS_ZF_3G "PQ35_46";
CM_ BU_ LWR "PQ35_46";
CM_ BU_ LWS "PQ35_46";
CM_ BU_ Magne_Ride "Audi_PQ35";
CM_ BU_ Motor_Diesel "PQ35_46";
CM_ BU_ Motor_Hybrid "PQ35";
CM_ BU_ Motor_Otto "PQ35_46";
CM_ BU_ PDC_PLA "PQ35_46";
CM_ BU_ Quersperre_VAQ "PQ35_46";
CM_ BU_ RKA_Plus "Audi_PQ35";
CM_ BU_ SAK "Audi_PQ35";
CM_ BU_ Waehlhebel "PQ35_46";
CM_ BU_ Waehlhebel_Sele "Audi_PQ35";
CM_ SG_ 1654 BAP_Data_Anzeige "ASG: KBI => FSG: ACC, VZA, HCA, SWA";
CM_ SG_ 1658 BAP_Data_Anzeige_02 "ASG: RNS, Radio => FSG: OPS, HYB";
CM_ SG_ 1750 BAP_Data_Debug_Cmd "BAP Debug Cmd";
CM_ SG_ 1751 BAP_Debug_Data "BAP Debug Data";
CM_ SG_ 1754 BAP_Data_OPS "FSG: OPS => ASG: RNS, Radio, KBI";
CM_ SG_ 946 BEM_HYB_DC_uMinLV "Abregelgrenze: minimal erlaubte Bordnetzspannung im Hochsetzbetrieb (Hybrid)";
CM_ SG_ 946 BEM_HYB_DC_uSollLV "Sollwert für die Bordnetzspannung im Tiefsetzbetrieb vom Traktionsnetz ins Bordnetz (Hybrid)";
CM_ SG_ 901 CHA_Ziel_FahrPr_MO "Anforderung Ziel-Fahrprogramm Motor";
CM_ SG_ 901 CHA_Ziel_FahrPr_GE "Anforderung Ziel-Fahrprogramm Getriebe";
CM_ SG_ 902 CHA_Ziel_FahrPr_KL "Anforderung Ziel-Fahrprogramm-Klima";
CM_ SG_ 902 CHA_Kombi_Texte "Anzeige des aktuellen Charisma-Fahrprofiles im Kombi.
Die Texte werden HUT-Spezifisch in einem Schnittstellen-LAH definiert.";
CM_ SG_ 945 DC_HYB_iAktLV "Momentanwert: Strom vom DC/DC-Wandler in das Bordnetz";
CM_ SG_ 945 DC_HYB_iAktReserveLV "Momentanwert: Stromreserve vom DC/DC-Wandler in Richtung 12V-Bordnetz";
CM_ SG_ 945 DC_HYB_uAktLV "Momentanwert: NV-Bordnetzspannung am DC/DC-Wandler";
CM_ SG_ 945 DC_HYB_LangsRegelung "aktueller Regelmode des DC/DC-Wandlers.
0: normale Regelung
1: langsame Regelung";
CM_ SG_ 945 DC_HYB_Abregelung_Temperatur "Abregelung aufgrund Übertemperatur im Leistungsteil (Hochtemperatur-Abregelung)";
CM_ SG_ 945 DC_HYB_Fehler_RedLeistung "Fehler: eingeschränkte Leistungsfähigkeit des DC/DC-Wandlers aufgrund eines internen Fehlers";
CM_ SG_ 945 DC_HYB_Fehler_intern "Fehler: DC/DC-Wandler ist aufgrund eines internen Hardware-Fehlers abgeschaltet";
CM_ SG_ 945 DC_HYB_Fehler_Spannung "Abschaltung aufgrund Unter-/Überspannung auf der Ein-/Ausgangsseite";
CM_ SG_ 945 DC_HYB_Auslastungsgrad "Momentanwert: Auslastung DC/DC (DFM Signal), entspricht I_akt / I_max";
CM_ SG_ 18 GSG_WFS_RND "Zufallszahl Anfrage";
CM_ SG_ 18 GSG_WFS_SIG_E "Signatur Anfrage";
CM_ SG_ 18 GSG_WFS_P_Klasse "Leistungsklasse";
CM_ SG_ 19 WFS_GSG_SIG_S "Signatur Antwort";
CM_ SG_ 19 WFS_GSG_Status_Antwort "0 bei Dummy-Antwort, wenn WFS n.i.O. ist";
CM_ SG_ 19 WFS_GSG_Status_Lesespule "nur Info; keine Auswirkung auf Freischaltung";
CM_ SG_ 19 WFS_GSG_Status_Schluessel "nur Info; keine Auswirkung auf Freischaltung";
CM_ SG_ 19 WFS_GSG_Status_Anfrage "Signatur der Anfrage i.O.?";
CM_ SG_ 19 WFS_GSG_Status_P_Klasse "Leistungsklasse i.O.?";
CM_ SG_ 17 WFS_MSG1_SIG_S "Signatur Antwort";
CM_ SG_ 17 WFS_MSG1_Status_Antwort "0 bei Dummy-Antwort, wenn WFS n.i.O. ist";
CM_ SG_ 17 WFS_MSG1_Status_Lesespule "nur Info; keine Auswirkung auf Freischaltung";
CM_ SG_ 17 WFS_MSG1_Status_Schluessel "nur Info; keine Auswirkung auf Freischaltung";
CM_ SG_ 17 WFS_MSG1_Status_Anfrage "Signatur der Anfrage i.O.?";
CM_ SG_ 17 WFS_MSG1_Status_P_Klasse "Leistungsklasse i.O.?";
CM_ SG_ 21 WFS_MSG2_SIG_S "Signatur Antwort";
CM_ SG_ 21 WFS_MSG2_Status_Antwort "0 bei Dummy-Antwort, wenn WFS n.i.O. ist";
CM_ SG_ 21 WFS_MSG2_Status_Lesespule "nur Info; keine Auswirkung auf Freischaltung";
CM_ SG_ 21 WFS_MSG2_Status_Schluessel "nur Info; keine Auswirkung auf Freischaltung";
CM_ SG_ 21 WFS_MSG2_Status_Anfrage "Signatur der Anfrage i.O.?";
CM_ SG_ 21 WFS_MSG2_Status_P_Klasse "Leistungsklasse i.O.?";
CM_ SG_ 23 WFS_MSG3_SIG_S "Signatur Antwort";
CM_ SG_ 23 WFS_MSG3_Status_Antwort "0 bei Dummy-Antwort, wenn WFS n.i.O. ist";
CM_ SG_ 23 WFS_MSG3_Status_Lesespule "nur Info; keine Auswirkung auf Freischaltung";
CM_ SG_ 23 WFS_MSG3_Status_Schluessel "nur Info; keine Auswirkung auf Freischaltung";
CM_ SG_ 23 WFS_MSG3_Status_Anfrage "Signatur der Anfrage i.O.?";
CM_ SG_ 23 WFS_MSG3_Status_P_Klasse "Leistungsklasse i.O.?";
CM_ SG_ 25 WFS_MSG4_SIG_S "Signatur Antwort";
CM_ SG_ 25 WFS_MSG4_Status_Antwort "0 bei Dummy-Antwort, wenn WFS n.i.O. ist";
CM_ SG_ 25 WFS_MSG4_Status_Lesespule "nur Info; keine Auswirkung auf Freischaltung";
CM_ SG_ 25 WFS_MSG4_Status_Schluessel "nur Info; keine Auswirkung auf Freischaltung";
CM_ SG_ 25 WFS_MSG4_Status_Anfrage "Signatur der Anfrage i.O.?";
CM_ SG_ 25 WFS_MSG4_Status_P_Klasse "Leistungsklasse i.O.?";
CM_ SG_ 1811 ISO_ABS_Req_Data "ISO Request Kanal";
CM_ SG_ 1917 ISO_ABS_Resp_Data "ISO Response Kanal";
CM_ SG_ 1879 ISO_ACC_Req_Data "ISO Request Kanal";
CM_ SG_ 1985 ISO_ACC_Resp_Data "ISO Response Kanal";
CM_ SG_ 1813 ISO_Airbag_01_Req_Data "ISO Request Kanal";
CM_ SG_ 1919 ISO_Airbag_01_Resp_Data "ISO Response Kanal";
CM_ BO_ 1874 "ACHTUNG: CAN-Identifier identisch zu mTP_Dyn_RKA_Plus_1
Im VW411CS als Request-ID ISO-TP für die Parkbremse verwendet!
Im Audi TTNF als dynamischer TP2.0-Kanal für RKA-Plus verwendet!";
CM_ SG_ 1874 ISO_EPB_Req_Data "ISO Request Kanal

ACHTUNG: CAN-Identifier identisch zu mTP_Dyn_RKA_Plus_1
Im SVW411 als Request-ID ISO-TP für die Parkbremse verwendet!
Im Audi TTNF als dynamischer TP2.0-Kanal für RKA-Plus verwendet!";
CM_ SG_ 1980 ISO_EPB_Resp_Data "ISO Response Kanal";
CM_ SG_ 1802 ISO_EPH_Req_Data "ISO Request Kanal";
CM_ SG_ 1908 ISO_EPH_Resp_Data "ISO Response Kanal";
CM_ SG_ 1792 ISO_ALL_01_Req_Data "ISO Request Kanal";
CM_ SG_ 2015 ISO_OBD_01_Req_Data "ISO Request Kanal";
CM_ SG_ 2017 ISO_Getriebe_01_Req_Data "ISO Request Kanal";
CM_ SG_ 2025 ISO_Getriebe_01_Resp_Data "ISO Response Kanal";
CM_ SG_ 1891 ISO_Gurtmikro_Req_Data "ISO Request Kanal";
CM_ SG_ 1997 ISO_Gurtmikro_Resp_Data "ISO Response Kanal";
CM_ SG_ 1893 ISO_Ladegeraet_Req_Data "ISO Request Kanal";
CM_ SG_ 1999 ISO_Ladegeraet_Resp_Data "ISO Response Kanal";
CM_ SG_ 1810 ISO_Lenkhilfe_Req_Data "ISO Request Kanal";
CM_ SG_ 1916 ISO_Lenkhilfe_Resp_Data "ISO Response Kanal";
CM_ SG_ 1876 ISO_LWRAFS_Req_Data "ISO Request Kanal";
CM_ SG_ 1982 ISO_LWRAFS_Resp_Data "ISO Response Kanal";
CM_ SG_ 2016 ISO_MO_01_Req_Data "ISO Request Kanal";
CM_ SG_ 2024 ISO_MO_01_Resp_Data "ISO Response Kanal";
CM_ SG_ 2018 ISO_MOS_01_Req_Data "ISO Request Kanal";
CM_ SG_ 2026 ISO_MOS_01_Resp_Data "ISO Response Kanal";
CM_ SG_ 2021 ISO_OBD_BECM_Req_Data "ISO Request Kanal";
CM_ SG_ 2029 ISO_OBD_BECM_Resp_Data "ISO Response Kanal";
CM_ SG_ 2022 ISO_OBD_DMCM_Req_Data "ISO Request Kanal";
CM_ SG_ 2030 ISO_OBD_DMCM_Resp_Data "ISO Response Kanal";
CM_ SG_ 2019 ISO_OBD_reserv1_Req_Data "ISO Request Kanal";
CM_ SG_ 2027 ISO_OBD_reserv1_Resp_Data "ISO Response Kanal";
CM_ SG_ 2020 ISO_OBD_reserv2_Req_Data "ISO Request Kanal";
CM_ SG_ 2028 ISO_OBD_reserv2_Resp_Data "ISO Response Kanal";
CM_ SG_ 2023 ISO_OBD_reserv5_Req_Data "ISO Request Kanal";
CM_ SG_ 2031 ISO_OBD_reserv5_Resp_Data "ISO Response Kanal";
CM_ SG_ 1386 ACA_Checksum "Prüfsumme mit Endwert 0x0, Definition im CAN Lastenheft (HS-CAN V4.2a, LS-CAN V1.42)";
CM_ SG_ 1386 ACA_StaACC "Status nur zur Anzeige im Kombi
Achtung: ACC aktiv nicht im Sinne Status ADR
siehe Schnittstellenbeschreibung ACC/Kombi";
CM_ SG_ 1386 ACA_ID_StaACC "siehe Schnittstellenbeschreibung ACC/Kombi
Index ACC System Status";
CM_ SG_ 1386 ACA_Fahrerhinw "Zur optischen Information des Fahrers, dass Systemgrenze erreicht ist
Ansteuerung optischer Fahrerhinweis";
CM_ SG_ 1386 ACA_AnzDisplay "siehe Schnittstellenbeschreibung ACC/Kombi
Anzeige Display";
CM_ SG_ 1386 ACA_Zeitluecke "Anzeige im Kombi, wenn ADR aktiv oder ADR passiv
Gesetzte Zeitlücke";
CM_ SG_ 1386 ACA_V_Wunsch "Anzeige im Kombi, wenn ADR aktiv oder ADR passiv
Wunschgeschwindigkeit";
CM_ SG_ 1386 ACA_kmh_mph "ADR zeigt damit an, dass es mit der Anzeige im Kombi synchronisiert arbeitet
Info Einheit der Geschwindigkeit";
CM_ SG_ 1386 ACA_Akustik1 "Löst niederprioren Gong ('leise') im Kombi aus und ist im Kombi bei aktuellem Bild mit Anzeigepriorität 2 gekoppelt. Mitteldisplay wird in jedem Fall angezeigt
Ansteuerung Akustik 1";
CM_ SG_ 1386 ACA_Akustik2 "Löst Summer ('laut') im Kombi aus und ist im Kombi bei aktuellem Bild mit Anzeigepriorität 1 gekoppelt. Mitteldisplay wird in jedem Fall angezeigt
Ansteuerung Akustik 2";
CM_ SG_ 1386 ACA_PrioDisp "siehe Schnittstellenbeschreibung ACC/Kombi
Anzeige Display Priorität";
CM_ SG_ 1386 ACA_gemZeitl "Aktuelle Distanz zum vorausfahrenden Fahrzeug, auf das geregelt wird; die Einheit ist Stufen der Zeitlücke (vgl. Gesetzte Zeitlücke)
Zeitlücke gemessen";
CM_ SG_ 1386 ACA_ACC_Verz "Bei gesetztem Bit befindet sich das ACC Fahrzeug in einer Verzögerung
ACC Verzögerung";
CM_ SG_ 1386 ACA_StaGRA "primäre GRA Zustandsanzeige
GRA System Status";
CM_ SG_ 1386 ACA_ID_StaGRA "GRA Zustandsanzeige Ergänzung
Index GRA Status Anzeige";
CM_ SG_ 1386 ACA_Codierung "Sendercodierung";
CM_ SG_ 1386 ACA_Tachokranz "Zusätzliche Status- und Einstellbereichsanzeige im Tachometer (z. Zt. nur Touareg GP)
Tachokranz";
CM_ SG_ 1386 ACA_Aend_Zeitluecke "Anzeige der Zeitlückenänderung im Kombiinstrument (z. Zt. nur Touareg GP)
Anzeige Änderung Zeitlücke";
CM_ SG_ 1386 ACA_Zaehler "Definition im CAN-Lastenheft
Botschaftszähler";
CM_ SG_ 872 ACS_Checksum "Prüfsumme mit Endwert 0x0, Definition im CAN Lastenheft (HS-CAN V4.2a, LS-CAN V1.42)";
CM_ SG_ 872 ACS_Zaehler "Definition im CAN Lastenheft
Botschaftszähler";
CM_ SG_ 872 ACS_Sta_ADR "Aktivierung ADR durchläuft Algorithmus, in den der GRA_Status (Motor 2) eingeht
Status ADR";
CM_ SG_ 872 ACS_ADR_Schub "ADR Schub";
CM_ SG_ 872 ACS_Schubabsch "Verhinderung Schubabschaltung";
CM_ SG_ 872 ACS_StSt_Info "Stopp-Freigabe/Start-Anforderung für den Start-Stopp-Koordinator;0 = Motorlauf langfristig nicht notwendig [Stoppfreigabe] ;1 = Motoranlauf nicht zwingend notwendig [Stoppverbot, keine Startanforderung];2 = Motoranlauf zwingend notwendig [Startanforderung";
CM_ SG_ 872 ACS_MomEingriff "Das Setzen dieses Bits bedeutet, dass kein Momenteneingriff erfolgen soll. Wird für Komfortfunktion verwendet
Verhinderung Momenteneingriff";
CM_ SG_ 872 ACS_Typ_ACC "Motor plausibilisiert seine eigene Kodierung (z. Zt. nur PQ46)
Typ ACC";
CM_ SG_ 872 ACS_FreigSollB "Beschleunigungsanforderung in Byte 4,5 wird mit diesem Bit aktiviert
Freigabe Sollbeschleunigung";
CM_ SG_ 872 ACS_Sollbeschl "Byte 4 LSB, Byte 5 (2...0) MSB Eingriff in Motorsteuergerät (aktiv, wenn Byte 3 Bit 7 gesetzt ist)
Sollbeschleunigung";
CM_ SG_ 872 ACS_Anhaltewunsch "Erweiterung für ACC Follow to Stop (im PQ46)
Anhaltewunsch";
CM_ SG_ 872 ACS_Fehler "Bei gesetztem Bit ist mindestens ein Kundendienstfehler eingetragen
Fehlerspeichereintrag ACC-SG";
CM_ SG_ 872 ACS_zul_Regelabw "Betrag der regulär zulässigen Regelabweichung zwischen angefordeter und umgesetzter Sollbeschleunigung;Wird für Komfortfunktion verwendet
Zulässige Regelabweichung";
CM_ SG_ 872 ACS_max_AendGrad "Betrag des max. zulässigen Gradienten zur Änderung der aktuell umgesetzten Sollbeschleunigung;Wird für Komfortfunktion verwendet
Maximaler Änderungsgradient";
CM_ BO_ 1688 "Entwicklungs-Botschaft";
CM_ SG_ 1688 AFZ_ParaSW_L "Erst wenn AFS Master und die beiden Scheinwerfer parametriesiert/codiert sind ist die Grundeinstellung möglich";
CM_ SG_ 1688 AFZ_ParaSW_R "Erst wenn AFS Master und die beiden Scheinwerfer parametriesiert/codiert sind ist die Grundeinstellung möglich";
CM_ SG_ 1688 AFZ_Modus "Touristenlösung über Anpassung anwählbar (Schwenken deaktiviert)";
CM_ SG_ 1688 AFZ_Init "Initialisierungslauf beider Kurvenlicht Schrittmotoren, erfolgt defaultmäßig beim Motorstart";
CM_ SG_ 1688 AFZ_SafePos "AFS Sicherheitsposition beider Scheinwerfer des dyn. Kurvenlichts";
CM_ SG_ 1688 AFZ_IstPosMot_L "(Gespiegelt vom AFS-Subbus)
Position des Aktuators in Prozent des maximalen Stellweges;
vor dem Initialisierungslauf (z. Zt. Motorstart) wird der Initwert ausgegeben
0% ist die Position (auf Block) des Schrittmotors
100% maximaler Verstellweg des Schr";
CM_ SG_ 1688 AFZ_IstPosMot_R "(Gespiegelt vom AFS-Subbus)
Position des Aktuators in Prozent des maximalen Stellweges;
vor dem Initialisierungslauf (z. Zt. Motorstart) wird der Initwert ausgegeben
0% ist die Position (auf Block) des Schrittmotors
100% maximaler Verstellweg des Schr";
CM_ SG_ 1688 AFZ_Soll_EVG "100% entsprechen 35 Watt
Die Last schaltet nur das ILM";
CM_ SG_ 1688 AFZ_IstDimAbLi "(Gespiegelt vom AFS-Subbus)
0% - 100% bezogen auf die Versorgungsspannung des linken Moduls";
CM_ SG_ 1688 AFZ_IstDimAbRe "(Gespiegelt vom AFS-Subbus)
0% - 100% bezogen auf die Versorgungsspannung des rechten Moduls";
CM_ SG_ 1688 AFZ_StaLamp_L "Statusmeldung des Lampenausfalls für das linke statische Kurvenlicht";
CM_ SG_ 1688 AFZ_StaLamp_R "Statusmeldung des Lampenausfalls für das rechte statische Kurvenlicht";
CM_ BO_ 80 "CAN-Antrieb CAN-Dashboard";
CM_ SG_ 80 AB1_Front "Bit wird bei Überschreitung der Gurtstraffer, US-Schwelle und RDW-Schwelle gesetzt
Front-Crash";
CM_ SG_ 80 AB1_Heck "wird für neu anlaufende Projekte umgesetzt: AB8.4, Audi8/VW8
Heck-Crash";
CM_ SG_ 80 AB1_Fa_Seite "z. Zt. Nur in Verbindung mit Crash-Intensität 100b (Kraftstoffpumpenabsch.) verwendet
Seiten-Crash Fahrer";
CM_ SG_ 80 AB1_Bf_Seite "z. Zt. Nur in Verbindung mit Crash-Intensität 100b (Kraftstoffpumpenabsch.) verwendet
Seiten-Crash Beifahrer";
CM_ SG_ 80 AB1_Rollover "wird im B6 Cabrio und New Beetle Cabrio, Touareg GP und VW465 bedient
Rollover";
CM_ SG_ 80 AB1_Intens "Die folgende Auswertung ist bei VW geplant: ; >= 001: ZV auf, Innenlicht u. Warnblinker ein ; >= 010: Notruf ausgelöst ; >= 100: Kraftstoffabschaltung (mit RDW-Schwelle aktiviert, d.h.Bit 7 = 1); ; Information bleibt bei jeder Schwellwert-überschreitung f";
CM_ SG_ 80 AB1_Lampe "Sicherheitswarnlampe im Kombi wird vom Airbag-SG angesteuert; Zustand der Lampe wird auf dem CAN-Bus ausgegeben (auch Blinkinformation)
Airbag-Lampe";
CM_ SG_ 80 AB1_Status "Airbag oder Gurtstraffer wurden per Anpassung deaktiviert: Aktualisierung erst nach Selbsttest
Airbag deaktiviert";
CM_ SG_ 80 AB1_Beifahrer "Als Option vorgehalten, Beifahrerairbag wurden per Schlüsselschalter oder Insassenerkennung deaktiviert
Beifahrerairbag deaktiviert";
CM_ SG_ 80 AB1_System "Warnlampe (Byte 2, Bit 0) wird dauernd angeschaltet
Airbag-Systemfehler";
CM_ SG_ 80 AB1_Gurt_Fa "über Schalter im Gurtschloss
Gurtschlossabfrage Fahrer";
CM_ SG_ 80 AB1_Gurt_Bf "über Schalter im Gurtschloss
Gurtschlossabfrage Beifahrer";
CM_ SG_ 80 AB1_Diagnose "Bei Diagnose über UDS nicht mehr bedient
Airbag in Diagnose";
CM_ SG_ 80 AB1_Stellglied "zur Unterdrückung einer Notrufauslösung
Airbag im Stellgliedtest";
CM_ SG_ 80 AB1_BF_Warnung "im Kombi wird eine Gurtwarnung für den Beifahrer ausgelöst (z. B. Beifahrersitz belegt, Gurt nicht angelegt)
Gurtwarnung Beifahrer";
CM_ SG_ 80 AB1_Fehlereintr "Bei gesetztem Bit ist mindestens ein Kundendienstfehler eingetragen";
CM_ SG_ 80 AB1_Zaehler "überlaufender Botschaftszähler zur Lebenderkennung";
CM_ SG_ 80 AB1_Checksumme "Prüfsumme mit Endwert 0x0, Definition im CAN Lastenheft (HS-CAN V4.2a, LS-CAN V1.42)";
CM_ SG_ 1360 AB2_Checksum "Prüfsumme mit Endwert 0x0, Definition im CAN Lastenheft (HS-CAN V4.2a, LS-CAN V1.42)";
CM_ SG_ 1360 AB2_Beleg_HF "über Gurt-Wickelband
Belegungserkennung hinten Fahrer";
CM_ SG_ 1360 AB2_Beleg_HBF "über Gurt-Wickelband
Belegungserkennung hinten Beifahrer";
CM_ SG_ 1360 AB2_Beleg_HM "über Gurt-Wickelband
Belegungserkennung hinten Mitte";
CM_ SG_ 1360 AB2_Beleg_BF "Wird in US-Steuergeräten Audi8R/VW8R/AB8.4E++ bedient, optional bei der RdW, falls SBE-EuroNCAP entschieden wird
Belegungserkennung Beifahrersitz";
CM_ SG_ 1360 AB2_OOP_Fa "000
001
01X (z.Zt. Vorhalt)
100 Ausl. mit 100 %
101 Ausl. mit 70 %
110 Ausl. mit 30 %
111 (z.Zt. Vorhalt)
OOP Fahrer (reserviert)";
CM_ SG_ 1360 AB2_OOP_BF "000
001
01X (z.Zt. Vorhalt)
100 Ausl. mit 100 %
101 Ausl. mit 70 %;110 Ausl. mit 30 %;111 (z.Zt. Vorhalt)
OOP Beifahrer (reserviert)";
CM_ SG_ 1360 AB2_Sta_BF "Der Fahrer soll bei einem Statuswechsel des Beifahrerairbags (ausgelöst durch die Beifahrerinsassenerkennung oder den Schlüsselschloßschalter) aufmerksam gemacht werden durch eine Anzeige im Kombi!;Nur Audi, gültig für: AB2 (4-Türer AU352), B7, C6, D3
Au";
CM_ SG_ 1360 AB2_Gurt_2FaS "Gurtwarnung 2. Reihe Fahrerseite für EuroNCAP 6. Stern";
CM_ SG_ 1360 AB2_Gurt_2BfS "Gurtwarnung 2. Reihe Beifahrerseite für EuroNCAP 6. Stern";
CM_ SG_ 1360 AB2_Gurt_2Mi "Gurtwarnung 2. Reihe Mitte für EuroNCAP 6. Stern";
CM_ SG_ 1360 AB2_Gurt_3FaS "Gurtwarnung 3. Reihe Fahrerseite für EuroNCAP 6. Stern";
CM_ SG_ 1360 AB2_Gurt_3BfS "Gurtwarnung 3. Reihe Beifahrerseite für EuroNCAP 6. Stern";
CM_ SG_ 1360 AB2_Gurt_3Mi "Gurtwarnung 3. Reihe Mitte für EuroNCAP 6. Stern";
CM_ SG_ 704 AL1_Fehler "Systemfehler (Sammelmeldung für alle statischen Fehlerzustände)
Fehler Allrad-Kupplung";
CM_ SG_ 704 AL1_Uebertemp "Kupplung wegen Übertemperatur geöffnet (Elektronikschutz)
Übertemperaturschutz (Allrad 1)";
CM_ SG_ 704 AL1_Sta_Kup "Vorgabe des ABS-Steuergerätes ist zur Zeit nicht ausführbar, weil ein Fehler vorliegt oder die aktuelle Vorgabe nicht möglich ist:;wird gesetzt, wenn Kupplung fehlerhaft nicht öffnet (nur dann) oder Bremse 4-Botschaft nicht empfangen wird
Fehlerstatus Ku";
CM_ SG_ 704 AL1_Kup_offen "Ventil ist vollständig geöffnet
Kupplung komplett offen";
CM_ SG_ 704 AL1_Notlauf "Bit wird gesetzt, wenn Irgendein Problem erkannt wurde (auch Time Out-Fehler)
Notlauf";
CM_ SG_ 704 AL1_Warnlampe "Vorhalt für zukünftige Projekte (auch für PNG);RPU: Als Kontroll-Symbol Längssperre genutzt
Allrad-Warnlampe";
CM_ SG_ 704 AL1_Limiter "Begrenzung der Fahrzeuggeschwindigkeit durch das Motor-SG (Wert muß im MSG appliziert sein). ; Grund kann z.B. verringerte Fahrzeugstabilität bei Geländeuntersetzung sein (nicht PQ35/46)
Geschwindigkeitsbegrenzung";
CM_ SG_ 704 AL1_Einheit "Kupplungsmoment in Byte 2 erhält eine andere Einheit
Einheit des Kupplungs-Wertes";
CM_ SG_ 704 AL1_Ist_Nm "Ist-Moment berechnet aus der Drucksensorinformation; 'Kupplung schnell offen` heißt, daß der Befehl vom Bremsen-Steuergerät ausgeführt wird (d.h. Sollzustand, kein Istwert !), ; der Arbeitsbereich geht von 0 (=80H) Nm (Kupplung gesteuert offen) bis 882 (=";
CM_ SG_ 704 AL1_Ist_Proz "nur wenn Einheit der Kupplungssteifigkeit in Prozente
Kupplungssteifigkeit Mitte (Ist-Wert)";
CM_ SG_ 704 AL1_Sta_PNG "Als Info für andere Systeme (ADR, 4CL, ...) ob die Geländeuntersetzung aktiv ist.
PNG-Status";
CM_ SG_ 704 AL1_Anz_blinken "Vorhalt für PNG;RPU: Längssperren-Symbole blinken
PNG-Anzeige blinkend";
CM_ SG_ 704 AL1_Sta_Laengssp "Gibt den Status der Längssperre für andere Systeme an (z.B. ESP, ACC,..)
Längssperren Status";
CM_ SG_ 704 AL1_Sta_Quersp "Gibt den Status der Hinterachs-Quersperre für andere Systeme an (z.B. ESP, ACC,..)
Hinterachs Status";
CM_ SG_ 704 AL1_Schalten "Aktion wird ausgeführt (nicht bei Audi)
Schaltung aktiv (Allrad 1)";
CM_ SG_ 704 AL1_Vorwarnung "Schaltung wird demnächst eingeleitet; Bit bleibt bis zum Ende der Schaltung gesetzt (nicht bei Audi)
Schaltung Vorwarnung";
CM_ SG_ 704 AL1_Stellung_Getr "Neutralinformation wird vom Verteilergetriebe eingelesen
Schaltung Neutralstellung";
CM_ SG_ 704 AL1_AnfVerteiler "Im PQ35/46 mit 0 belegt, wenn in Byte 5 die Kupplungstemperatur gesendet wird.;Wenn dieses Bit gesetzt ist, soll das Motormoment auf den im Byte 5 gesendeten Wert reduziert werden.
Verteiler-Anforderung";
CM_ SG_ 704 AL1_Sta_VA "Gibt den Status der Vorderachs-Quersperre für andere Systeme an (z.B. ESP, ACC,..);(zur Zeit nur Vorhalt)
Vorderachs Status";
CM_ SG_ 704 AL1_KupSteifig_F "Zusatzinfo, falls im Byte 2 der Fehlerwert FFhex gesendet wird (nur bei Colorado)
Kupplungssteifigkeit im Fehlerzustand";
CM_ SG_ 704 AL1_Fehlereintr "Bei gesetztem Bit ist mindestens ein Kundendienstfehler eingetragen";
CM_ SG_ 704 AL1_KupplTemp "Sensorwert Kupplungsöltemperatur (AL1_KupplTemp): Der Wert ist gültig, wenn das Bit 'Verteiler-Anforderung' (Byte 4, Bit 3) mit 0 belegt ist. (Haldex)

Doppelte Signalbelegung in Altprojekten (VW756):
Verteiler Begrenzungsmoment (AL1_Begrenzungsmo): De";
CM_ SG_ 704 AL1_FaWu_Laengs "Während im ¿Längssperren Status¿ (Byte 3) der tatsächliche Sperrenzustand angegeben wird, werden diese Bits gesetzt, sobald der Fahrwerksschalter entsprechend bedient wird.
Fahrerwunsch Längssperre";
CM_ SG_ 704 AL1_FaWu_HA "Während im ¿Hinterachs Status¿ (Byte 3) der tatsächliche Sperrenzustand angegeben wird, werden diese Bits gesetzt, sobald der Fahrwerksschalter entsprechend bedient wird.
Fahrerwunsch Hinterachssperre";
CM_ SG_ 704 AL1_FaWu_VA "Während im ¿Vorderachs Status¿ (Byte 4) der tatsächliche Sperrenzustand angegeben wird, werden diese Bits gesetzt, sobald der Fahrwerksschalter entsprechend bedient wird.
Fahrerwunsch Vorderachssperre";
CM_ SG_ 704 AL1_Quersp_Sta "Quersperre nur im Haldex T5 an Allrad angeschlossen (Init im T5/PQ35/PQ46: 3)
Quersperren-Status";
CM_ SG_ 704 AL1_Limit_maxkmh "Höchstgeschwindigkeitsbegrenzung im Motorsteuergerät, aktiviert durch Bit 6 in Byte 1;(Signalbeschreibung muß nachgereicht werden)
Zulässige Geschwindigkeit bei Begrenzung";
CM_ SG_ 704 AL1_Diff_Verbau "Nur im T5: Differentialsperre ist an Allrad-SG angeschlossen (Init im T5/PQ35/PQ46: 1)
Differentialsperre verbaut";
CM_ SG_ 704 AL1_Diff_Lampe "Nur im T5 (Init im T5/PQ35/PQ46: 1)
Differentialsperren-Lampe";
CM_ SG_ 704 AL1_Diff_Gong "Bei v > 45 km/h wird Gong angesteuert, wenn Differentialsperre eingelegt ist
Differentialsperren-Gong";
CM_ SG_ 704 AL1_Warnton "Warnton Längssperre im RPU
0 = kein Warnton
1 = Warnton (Summer 2 bzw. Gong1000 als Dauerton)";
CM_ SG_ 704 AL1_Zaehler "Botschaftszähler, Definition im CAN-Lastenheft";
CM_ BO_ 870 "DLC 4 (PQ46 bis MP)
DLC 5 (Touareg GP, D1GP, VW461/2 ab MP 45/08, VW469 09/08)
DLC 8 (VW47x, T5GP)
DLC 8, BAF mit reduzierter Zykluszeit 20ms (VW120)";
CM_ SG_ 870 AWV_Checksumme "Prüfsumme mit Endwert 0x0, Definition im CAN Lastenheft (HS-CAN V4.2a, LS-CAN V1.42)";
CM_ SG_ 870 AWV_Zaehler "Freilaufender Botschaftszähler";
CM_ SG_ 870 AWV_Text "Anforderung an das Kombiinstrument, den ausgewählten Text anzuzeigen
0000 kein Text
0001 'Front Assist aus'
0010 'Front Assist startet'
0011 'Front Assist nicht verfügbar' bis 22/11 ->  ab 22/11 'Front Assist Warnung'
0100 'Front Assist Sensor reinig";
CM_ SG_ 870 AWV_1_Freigabe "Das Freigabebit muss gesetzt sein, um die Anforderungen 'Prefill' oder 'adaptiver HBA' freizugeben. (HBA = hydraulischer Bremsassistent)";
CM_ SG_ 870 AWV_1_Prefill "Anforderung an ESP, dass Prefill-Funktion aktiviert werden soll.
(PQ46 mit mAWV ID 0x366: Umsetzung der Prefill-Anforderung im ESP nur in Verbindung mit gesetztem Bit 'AWV1_Freigabe')";
CM_ SG_ 870 AWV_1_Parameter "Anforderung an ESP, welcher HBA-Parametersatz verwendet werden soll. (Die Festlegung der Empfindlichkeitsschwellen der verschiedenen Parametersätze erfolgt mit der Applikation des Gesamtsystems ESP/ACC bzw. des HBA.)
(PQ46 mit mAWV ID 0x366: Umsetzung de";
CM_ SG_ 870 AWV_Halten "Anforderung an das ESP, das Fahrzeug nach erfolgter automatischer Bremsung bis in den Stillstand im Stillstand zu halten und eine Fahrer-Überwachung zu aktivieren.";
CM_ SG_ 870 ANB_Teilbremsung_Freigabe "Freigabe-Bit der Teilbremsung an das ESP";
CM_ SG_ 870 AWV_2_Status "Ansteuerung der Statusanzeige (grüne Lampe) im Kombiinstrument";
CM_ SG_ 870 AWV_2_Fehler "Ansteuerung der Fehleranzeige (gelbe Lampe) im Kombiinstrument";
CM_ SG_ 870 AWV_2_SU_Warnzeit "Eingestellter Warnzeitpunkt
(Empfang nur, wenn kein BAP umgesetzt)
AWV2 Setup Warnzeitpunkt";
CM_ SG_ 870 AWV_2_SU_Bremsruck "Einstellung, ob der Fahrer einen Bremsruck erlaubt
(Empfang nur, wenn kein BAP umgesetzt)
AWV2 Setup Bremsruck";
CM_ SG_ 870 AWV_2_SU_Gong "Einstellung, ob der Fahrer eine akustische Warnung erlaubt
(Empfang nur, wenn kein BAP umgesetzt)
AWV2 Setup Gong";
CM_ SG_ 870 AWV_2_SU_Lampe "Einstellung, ob der Fahrer eine optische Warnung erlaubt
(Empfang nur, wenn kein BAP umgesetzt)
AWV2 Setup Lampe";
CM_ SG_ 870 AWV_2_Umfeldwarn "Anforderung für eine Warnung des Umfeldes / anderer Verkehrsteilnehmer (z. B. Warnblinken) bei extremen Fahrmanövern";
CM_ SG_ 870 AWV_2_Freigabe "Freigabe eines Ruckes - Auswertung des 'AWV2 Ruckprofil' bzw. Abbruch eines aktiven Bremsrucks";
CM_ SG_ 870 AWV_2_Ruckprofil "Anforderung an ESP / Boostersteuergerät, welcher Ruck verwendet werden soll. Die Festlegung der Parameter der verschiedenen Ruckprofile erfolgt mit der Applikation des Gesamtsystems ESP/Boostersteuergerät/ACC. Die Umsetzung der Anforderung im ESP/Boosters";
CM_ SG_ 870 AWV_2_Warnton "Anforderung an das Kombiinstrument eine akustische Fahrerwarnung (Summer) durchzuführen";
CM_ SG_ 870 AWV_2_Warnsymbol "Anforderung an das Kombiinstrument eine optische Fahrerwarnung mit hoher Priorität (rote Lampe/Pictogramm) im Mitteldisplay durchzuführen
Empfänger: Kombi";
CM_ SG_ 870 AWV_Infoton "Anforderung an das Kombiinstrument, die Anzeige des ausgwählten Textes (AWV Textindex) mit einer Akustik zu koppeln";
CM_ SG_ 870 AWV_2_Gurtstraffer "Anforderung an den reversiblen Gurtstraffer, den Gurt zu straffen (z.B. Warnaktuator, Precrash)
Geplante Empfänger: rev. Gurtstraffer";
CM_ SG_ 870 ANB_Zielbremsung_Freigabe "Freigabe-Bit der Zielbremsung an das ESP";
CM_ SG_ 870 ANB_CM_Anforderung "ANB_CM-Anforderungsbit an das ESP
Geplanter Empfänger: ESP";
CM_ SG_ 870 ANB_Ziel_Teilbrems_Verz_Anf "Verzögerungsanforderung der Funktionen Zielbremsung und Teibremsung an das ESP";
CM_ SG_ 1404 BY1_KD_Fehler "Info für Diagnose
bei gesetztem Bit befindet sich mindestens ein Kundendienstfehler im Fehlerspeicher";
CM_ SG_ 416 BR1_ASR_Anf "Anforderungen in Byte 5 und 6 sind auszuführen";
CM_ SG_ 416 BR1_MSR_Anf "Anforderung in Byte 7 ist auszuführen; Byte 6 ändert seine Bedeutung, wenn dieses Bit gesetzt ist
MSR Anforderung";
CM_ SG_ 416 BR1_ABS_Brems "Antiblockiersystem, Bit zeigt auch Druckabbau an (z.B. ESP hat zuviel Druck aufgebaut oder ungebremste Regelung auf Bahnübergang)";
CM_ SG_ 416 BR1_EDS_Eingr "Elektronische Differentialsperre
EDS Eingriff";
CM_ SG_ 416 BR1_ESP_Eingr "Fahrdynamikregelung
ESP Eingriff";
CM_ SG_ 416 BR1_ASR_Eingr "Wunsch an das Getriebe während einer ASR Regelung, bei Audi nur 00 und 01 genutzt
ASR-Schaltbeeinflussung";
CM_ SG_ 416 BR1_EBV_Eingr "Elektronische Bremskraftverteilung, aktueller Eingriff (Druckhalten, Druckabbau), kein ABS / ESP-Eingriff
EBV Eingriff";
CM_ SG_ 416 BR1_Lampe_ABS "Sicherheitswarnlampe
Lampe ABS";
CM_ SG_ 416 BR1_Lampe_ASR "Zustand der Lampe wird auf dem CAN-Bus ausgegeben (auch Blinkinformation)
Fahrzeuge mit ASR/ESP/MABS-Funktionalität bedienen die Sicherheitswarnlampe
Init: 0/1(SILA)
Lampe ASR / ESP";
CM_ SG_ 416 BR1_Lampe_BK "rote Lampe wird angesteuert, z. B. bei EBV-Ausfall;(Sicherheitswarnlampe im Audi C6/D3, AU716 mit Initwert 1)
Bremskontroll-Lampe";
CM_ SG_ 416 BR1_Lichtschalt "ohne aktiven BKV wird hier der Bremslichtschalter (0 kein Bremsen, 1 Bremse betätigt) übertragen (ESP5.7, ESP 8, Mk60, T5GP/RPU(MK25A XT))
ab PQ46 (mit Einsatz des einkanaligen Hall-BLS): Fahrer hat durch Pedalbetätigung die Bremsdruckschwelle überschrit";
CM_ SG_ 416 BR1_StaDruckschw "beim Bosch-ABS wird der Bremstestschalter (0 kein Bremsen, 1 Bremse betätigt) übertragen (D1GP/BY61x u. T5GP/RPU(MK25A XT)
ab PQ46: Druckschwelleninformation (Byte 2, Bit 3) kann noch nicht oder aufgrund eines Fehlers nicht ausgegeben werden (nicht Color";
CM_ SG_ 416 BR1_MAD "OBD-Funktion (MAD-Signal), wird bei Teves / TRW z.Zt. nicht ausgegeben
Schlechtwegausblendung";
CM_ SG_ 416 BR1_Sta_MAD "ESP 5.7: Im ESP-Fehlerfall ist Bit 'ungültig'
ESP 8: Im ESP-Fehler ist Bit weiterhin 'gültig'
Initwert 1 wird gesendet, wenn Funktion nicht umgesetzt
Fehlerstatus Schlechtwegausblendung";
CM_ SG_ 416 BR1_Diagnose "Kombi unterdrückt z.B. den Gong
ABS-Diagnose";
CM_ SG_ 416 BR1_BKV_aktiv "neues Status-Bit zur Vermeidung von Problemen während der Übergangszeit auf die neue Definition (BKV) und zur Darstellung des Fehlerzustandes: nur noch in T5 und im Colorado
Aktiver Bremskraftverstärker";
CM_ SG_ 416 BR1_Rad_kmh "Low Byte 3, High Byte 4 (Auflösung 1,28 km/h)
Bremse holt sich den Radumfang aus der Botschaft 'Kombi_3'
generell wird Mittelwert (alle außer B6/D3) der permanent angetriebenen Räder ausgegeben (d.h. bei Frontantrieb und gesteuertem Allrad (Haldex) Mitt";
CM_ SG_ 416 BR1_ASRMo_sl "wird in TRW Projekten nicht bedient (es wird 0 gesendet)

Hybrid:
Interpretiert als Reduktion Summenmoment VM+EM
ASR Eingriffsmoment langsam";
CM_ SG_ 416 BR1_ASRMo_fa "falls Byte 1, Bit 1 gleich 0;Achtung: Fehlerwert FFH wird nur benutzt, wenn es ein ASR-Eingriffsmoment ist - nicht beim bitinvertierten MSR-Moment;Hinweis T5GP/RPU: Bei zweikanaliger Anforderung muss Bremsensteuergerät die Zündwinkelreserve aus mMotor_2 B";
CM_ SG_ 416 BR1_MSR_Mo_inv "falls Byte 1, Bit 1 gleich 1
inverses MSR Eingriffsmoment";
CM_ SG_ 416 BR1_MSR_Mo "Hybrid: Interpretiert als Summenmoment VM+EM
MSR Eingriffsmoment";
CM_ SG_ 416 BR1_Zaehler "überlaufender Botschaftszähler, um Eingriffsmoment als aktualisiert zu kennzeichnen
Zähler (Bremse 1)";
CM_ SG_ 416 BR1_ASR_ESP "Kombi kann ggfs. die Lampe ansteuern
ASR/ESP-Steuergerät";
CM_ SG_ 416 BR1_ESPASR_passiv "ESP oder ASR (oder beides, oder Teilfunktionen, solange Fahrer nicht bremst) vom Fahrer passiv getastet oder ASR/ESP Funktionsumschaltung oder über Rollenmodus deaktiviert";
CM_ SG_ 416 BR1_Sta_ESP "Fehler steht für Stillegung ESP mit Fehlereintrag
ESP-Systemstatus";
CM_ SG_ 416 BR1_Ersatz_Kmh "Geschwindigkeit wird als Ersatzwert ausgegeben (z.B. ein Sensor defekt, kein Radumfang gelernt, kein oder fehlerhafter Radumfang vom Kombi empfangen oder bei Contiteves und passiven Sensoren wird Hinterrad eingespiegelt)
Geschwindigkeits-Ersatzwert";
CM_ SG_ 928 B10_Checksumme "Prüfsumme mit Endwert 0x0, Definition im CAN Lastenheft (HS-CAN V4.2a, LS-CAN V1.42)";
CM_ SG_ 928 B10_Zaehler "Überlaufender Botschaftszähler, zur Lebenderkennung";
CM_ SG_ 928 B10_QB_Wegimp_VL "Definition nach CAN-Lastenheft
Qualifizierungsbit Wegimpulse VL";
CM_ SG_ 928 B10_QB_Wegimp_VR "Definition nach CAN-Lastenheft
Qualifizierungsbit Wegimpulse VR";
CM_ SG_ 928 B10_QB_Wegimp_HL "Definition nach CAN-Lastenheft
Qualifizierungsbit Wegimpulse HL";
CM_ SG_ 928 B10_QB_Wegimp_HR "Definition nach CAN-Lastenheft
Qualifizierungsbit Wegimpulse HR";
CM_ SG_ 928 B10_Wegimp_VL "Anzahl der Wegimpulse Vorderrad links (steigende und fallende Flanke)
Zähler läuft grundsätzlich vorwärts, auch bei Rückwärtsfahrt";
CM_ SG_ 928 B10_Wegimp_VR "Anzahl der Wegimpulse Vorderrad rechts (steigende und fallende Flanke)
Zähler läuft grundsätzlich vorwärts, auch bei Rückwärtsfahrt";
CM_ SG_ 928 B10_Wegimp_HL "Anzahl der Wegimpulse Vorderrad links (steigende und fallende Flanke)
Zähler läuft grundsätzlich vorwärts, auch bei Rückwärtsfahrt";
CM_ SG_ 928 B10_Wegimp_HR "Anzahl der Wegimpulse Vorderrad links (steigende und fallende Flanke)
Zähler läuft grundsätzlich vorwärts, auch bei Rückwärtsfahrt";
CM_ SG_ 928 B10_QB_Fahrtr_VL "Definition nach CAN-Lastenheft
Qualifizierungsbit Fahrtrichtung VL";
CM_ SG_ 928 B10_QB_Fahrtr_VR "Definition nach CAN-Lastenheft
Qualifizierungsbit Fahrtrichtung VR";
CM_ SG_ 928 B10_QB_Fahrtr_HL "Definition nach CAN-Lastenheft
Qualifizierungsbit Fahrtrichtung HL";
CM_ SG_ 928 B10_QB_Fahrtr_HR "Definition nach CAN-Lastenheft
Qualifizierungsbit Fahrtrichtung HR";
CM_ SG_ 928 B10_Fahrtr_VL "Fahrtrichtungserkennung Vorderrad links";
CM_ SG_ 928 B10_Fahrtr_VR "Fahrtrichtungserkennung Vorderrad rechts";
CM_ SG_ 928 B10_Fahrtr_HL "Fahrtrichtungserkennung Hinterrad links";
CM_ SG_ 928 B10_Fahrtr_HR "Fahrtrichtungserkennung Hinterrad rechts";
BA_DEF_  "GenNWMApBusSleep" STRING ;
BA_DEF_  "GenNWMApCanNormal" STRING ;
BA_DEF_  "GenNWMApCanOff" STRING ;
BA_DEF_  "GenNWMApCanOn" STRING ;
BA_DEF_  "GenNWMApCanSleep" STRING ;
BA_DEF_  "GenNWMApCanWakeUp" STRING ;
BA_DEF_  "GenNWMGotoMode_Awake" STRING ;
BA_DEF_  "GenNWMGotoMode_BusSleep" STRING ;
BA_DEF_  "GenNWMSleepTime" INT 0 1000000;
BA_DEF_  "GenNWMTalkNM" STRING ;
BA_DEF_  "Manufacturer" STRING ;
BA_DEF_  "NmhBaseAddress" HEX 0 536870911;
BA_DEF_  "NmhMessageCount" INT 0 255;
BA_DEF_  "NmType" STRING ;
BA_DEF_  "VAGTP20_SetupMessageCount" INT 0 255;
BA_DEF_  "VAGTP20_SetupStartAddress" HEX 0 2047;
BA_DEF_  "VersionDay" INT 1 31;
BA_DEF_  "VersionMonth" INT 1 12;
BA_DEF_  "VersionWeek" INT 1 52;
BA_DEF_  "VersionYear" INT 0 99;
BA_DEF_  "VersionNumber" INT 0 65535;
BA_DEF_  "Baudrate" INT 0 1000000;
BA_DEF_  "SamplePointMin" INT 1 100;
BA_DEF_  "SamplePointMax" INT 1 100;
BA_DEF_  "SyncJumpWidthMin" INT 1 4;
BA_DEF_  "SyncJumpWidthMax" INT 1 4;
BA_DEF_  "NmhTimeoutTimer" INT 0 65535;
BA_DEF_  "NmhWaitBusSleepTimer" INT 0 65535;
BA_DEF_  "NmhPrepareBusSleepTimer" INT 0 65535;
BA_DEF_  "NmhLongTimer" INT 0 65535;
BA_DEF_  "NmhNStart" INT 0 255;
BA_DEF_ BU_  "GenNodAutoGenDsp" ENUM  "No","Yes";
BA_DEF_ BU_  "GenNodAutoGenSnd" ENUM  "No","Yes";
BA_DEF_ BU_  "GenNodSleepTime" INT 0 1000000;
BA_DEF_ BU_  "ILUsed" ENUM  "No","Yes";
BA_DEF_ BU_  "ECUVariantDefault" ENUM  "No","Yes";
BA_DEF_ BU_  "VAGTP20_TargetAddress" HEX 0 127;
BA_DEF_ BU_  "NodeLayerModules" STRING ;
BA_DEF_ BU_  "NmhNode" ENUM  "No","Yes";
BA_DEF_ BU_  "NmNode" ENUM  "No","Yes";
BA_DEF_ BO_  "GenMsgAutoGenDsp" ENUM  "No","Yes";
BA_DEF_ BO_  "GenMsgAutoGenSnd" ENUM  "No","Yes";
BA_DEF_ BO_  "GenMsgCycleTime" INT 0 65535;
BA_DEF_ BO_  "GenMsgCycleTimeFast" INT 0 65535;
BA_DEF_ BO_  "GenMsgDelayTime" INT 0 100000;
BA_DEF_ BO_  "GenMsgILSupport" ENUM  "No","Yes";
BA_DEF_ BO_  "GenMsgSendType" ENUM  "Cyclic","not_used","not_used","not_used","not_used","not_used","not_used","IfActive","NoMsgSendType";
BA_DEF_ BO_  "GenMsgStartDelayTime" INT 0 100000;
BA_DEF_ BO_  "NmMessage" ENUM  "No","Yes";
BA_DEF_ BO_  "NmhMessage" ENUM  "No","Yes";
BA_DEF_ BO_  "VAGTP20_API" HEX 0 255;
BA_DEF_ BO_  "VAGTP20_DynConnection" ENUM  "No","Yes";
BA_DEF_ BO_  "VAGTP20_DynSetup" ENUM  "No","Yes";
BA_DEF_ BO_  "VAGTP20_StatConnection" ENUM  "No","Yes";
BA_DEF_ BO_  "Timeoutzeit" INT 0 1000000;
BA_DEF_ BO_  "DiagRequest" ENUM  "No","Yes";
BA_DEF_ BO_  "DiagResponse" ENUM  "No","Yes";
BA_DEF_ BO_  "DiagState" ENUM  "No","Yes";
BA_DEF_ BO_  "GenMsgChkConstant" HEX 0 4095;
BA_DEF_ SG_  "GenSigAutoGenDsp" ENUM  "No","Yes";
BA_DEF_ SG_  "GenSigAutoGenSnd" ENUM  "No","Yes";
BA_DEF_ SG_  "GenSigEnvVarType" ENUM  "int","float","undef";
BA_DEF_ SG_  "GenSigInactiveValue" INT -2147483648 2147483647;
BA_DEF_ SG_  "GenSigSendType" ENUM  "Cyclic","OnWrite","OnWriteWithRepetition","OnChange","OnChangeWithRepetition","IfActive","IfActiveWithRepetition","NoSigSendType","OnChangeAndIfActive","OnChangeAndIfActiveWithRepetition";
BA_DEF_ SG_  "GenSigStartValue" INT -2147483648 2147483647;
BA_DEF_ SG_  "NWM-WakeupAllowed" ENUM  "No","Yes";
BA_DEF_ SG_  "GenSigFuncType" ENUM  "NoFunction","MsgCounter","CRC-8","XOR","XOR-2","DatedBit","SW-Kl15","CHK","Constant","Protocol";
BA_DEF_ SG_  "GenSigSwitchedByIgnition" ENUM  "No","Yes";
BA_DEF_ SG_  "Fehlerwert" HEX 0 2147483647;
BA_DEF_ SG_  "GenSigMissingSourceValue" HEX 0 2147483647;
BA_DEF_REL_ BU_SG_REL_  "GenSigTimeoutTime" INT 0 65535;
BA_DEF_DEF_  "GenNWMApBusSleep" "";
BA_DEF_DEF_  "GenNWMApCanNormal" "";
BA_DEF_DEF_  "GenNWMApCanOff" "";
BA_DEF_DEF_  "GenNWMApCanOn" "";
BA_DEF_DEF_  "GenNWMApCanSleep" "";
BA_DEF_DEF_  "GenNWMApCanWakeUp" "";
BA_DEF_DEF_  "GenNWMGotoMode_Awake" "";
BA_DEF_DEF_  "GenNWMGotoMode_BusSleep" "";
BA_DEF_DEF_  "GenNWMSleepTime" 0;
BA_DEF_DEF_  "GenNWMTalkNM" "";
BA_DEF_DEF_  "Manufacturer" "";
BA_DEF_DEF_  "NmhBaseAddress" 0;
BA_DEF_DEF_  "NmhMessageCount" 1;
BA_DEF_DEF_  "NmType" "None";
BA_DEF_DEF_  "VAGTP20_SetupMessageCount" 0;
BA_DEF_DEF_  "VAGTP20_SetupStartAddress" 0;
BA_DEF_DEF_  "VersionDay" 18;
BA_DEF_DEF_  "VersionMonth" 3;
BA_DEF_DEF_  "VersionWeek" 11;
BA_DEF_DEF_  "VersionYear" 10;
BA_DEF_DEF_  "VersionNumber" 0;
BA_DEF_DEF_  "Baudrate" 0;
BA_DEF_DEF_  "SamplePointMin" 1;
BA_DEF_DEF_  "SamplePointMax" 1;
BA_DEF_DEF_  "SyncJumpWidthMin" 1;
BA_DEF_DEF_  "SyncJumpWidthMax" 1;
BA_DEF_DEF_  "NmhTimeoutTimer" 0;
BA_DEF_DEF_  "NmhWaitBusSleepTimer" 0;
BA_DEF_DEF_  "NmhPrepareBusSleepTimer" 0;
BA_DEF_DEF_  "NmhLongTimer" 0;
BA_DEF_DEF_  "NmhNStart" 0;
BA_DEF_DEF_  "GenNodAutoGenDsp" "Yes";
BA_DEF_DEF_  "GenNodAutoGenSnd" "Yes";
BA_DEF_DEF_  "GenNodSleepTime" 0;
BA_DEF_DEF_  "ILUsed" "Yes";
BA_DEF_DEF_  "ECUVariantDefault" "Yes";
BA_DEF_DEF_  "VAGTP20_TargetAddress" 0;
BA_DEF_DEF_  "NodeLayerModules" "";
BA_DEF_DEF_  "NmhNode" "Yes";
BA_DEF_DEF_  "NmNode" "No";
BA_DEF_DEF_REL_ "GenSigTimeoutTime" 0;
BA_DEF_DEF_  "GenMsgAutoGenDsp" "Yes";
BA_DEF_DEF_  "GenMsgAutoGenSnd" "Yes";
BA_DEF_DEF_  "GenMsgCycleTime" 0;
BA_DEF_DEF_  "GenMsgCycleTimeFast" 0;
BA_DEF_DEF_  "GenMsgDelayTime" 0;
BA_DEF_DEF_  "GenMsgILSupport" "No";
BA_DEF_DEF_  "GenMsgSendType" "NoMsgSendType";
BA_DEF_DEF_  "GenMsgStartDelayTime" 0;
BA_DEF_DEF_  "NmMessage" "No";
BA_DEF_DEF_  "NmhMessage" "No";
BA_DEF_DEF_  "VAGTP20_API" 0;
BA_DEF_DEF_  "VAGTP20_DynConnection" "No";
BA_DEF_DEF_  "VAGTP20_DynSetup" "No";
BA_DEF_DEF_  "VAGTP20_StatConnection" "No";
BA_DEF_DEF_  "Timeoutzeit" 0;
BA_DEF_DEF_  "DiagRequest" "No";
BA_DEF_DEF_  "DiagResponse" "No";
BA_DEF_DEF_  "DiagState" "No";
BA_DEF_DEF_  "GenMsgChkConstant" 0;
BA_DEF_DEF_  "GenSigAutoGenDsp" "No";
BA_DEF_DEF_  "GenSigAutoGenSnd" "No";
BA_DEF_DEF_  "GenSigEnvVarType" "undef";
BA_DEF_DEF_  "GenSigInactiveValue" 0;
BA_DEF_DEF_  "GenSigSendType" "NoSigSendType";
BA_DEF_DEF_  "GenSigStartValue" 0;
BA_DEF_DEF_  "NWM-WakeupAllowed" "No";
BA_DEF_DEF_  "GenSigFuncType" "NoFunction";
BA_DEF_DEF_  "GenSigSwitchedByIgnition" "Yes";
BA_DEF_DEF_  "Fehlerwert" 0;
BA_DEF_DEF_  "GenSigMissingSourceValue" 0;
BA_ "NmhNStart" 5;
BA_ "NmhLongTimer" 200;
BA_ "NmhPrepareBusSleepTimer" 500;
BA_ "NmhWaitBusSleepTimer" 750;
BA_ "NmhTimeoutTimer" 1000;
BA_ "SyncJumpWidthMax" 4;
BA_ "SyncJumpWidthMin" 3;
BA_ "SamplePointMax" 84;
BA_ "SamplePointMin" 80;
BA_ "Baudrate" 500000;
BA_ "VersionNumber" 76;
BA_ "VAGTP20_SetupStartAddress" 512;
BA_ "VAGTP20_SetupMessageCount" 128;
BA_ "NmType" "NM-High";
BA_ "NmhMessageCount" 32;
BA_ "NmhBaseAddress" 1824;
BA_ "Manufacturer" "VAG";
BA_ "GenNWMTalkNM" "Nmh_ReqNetOn()";
BA_ "GenNWMSleepTime" 4000;
BA_ "GenNWMGotoMode_BusSleep" "Nmh_ReqNetOff()";
BA_ "GenNWMGotoMode_Awake" "Nmh_ReqNetOn()";
BA_ "GenNWMApCanWakeUp" "apCanWakeUp()";
BA_ "GenNWMApCanSleep" "apCanSleep()";
BA_ "GenNWMApCanOn" "NMIndnetOn()";
BA_ "GenNWMApCanOff" "NMIndnetOff()";
BA_ "GenNWMApCanNormal" "apCanNormal()";
BA_ "GenNWMApBusSleep" "NMIndNetSDN()";
BA_ "NmhNode" BU_ AFS 0;
BA_ "VAGTP20_TargetAddress" BU_ AFS 6;
BA_ "NmhNode" BU_ Airbag 0;
BA_ "VAGTP20_TargetAddress" BU_ Airbag 5;
BA_ "NmhNode" BU_ Allrad 0;
BA_ "VAGTP20_TargetAddress" BU_ Allrad 10;
BA_ "NmhNode" BU_ BAP_Tester 0;
BA_ "NodeLayerModules" BU_ BMS_Hybrid "NMHigh.DLL";
BA_ "GenNodSleepTime" BU_ BMS_Hybrid 4000;
BA_ "NodeLayerModules" BU_ Bremse_MK60EC "NMHigh.DLL";
BA_ "VAGTP20_TargetAddress" BU_ Bremse_MK60EC 3;
BA_ "GenNodSleepTime" BU_ Bremse_MK60EC 4000;
BA_ "NodeLayerModules" BU_ Bremse_MK70MABS "NMHigh.DLL";
BA_ "VAGTP20_TargetAddress" BU_ Bremse_MK70MABS 3;
BA_ "GenNodSleepTime" BU_ Bremse_MK70MABS 4000;
BA_ "NodeLayerModules" BU_ Bremse_TRW_EBC450M "NMHigh.DLL";
BA_ "VAGTP20_TargetAddress" BU_ Bremse_TRW_EBC450M 3;
BA_ "GenNodSleepTime" BU_ Bremse_TRW_EBC450M 4000;
BA_ "NodeLayerModules" BU_ Bremse_TRW_ESP "NMHigh.DLL";
BA_ "VAGTP20_TargetAddress" BU_ Bremse_TRW_ESP 3;
BA_ "GenNodSleepTime" BU_ Bremse_TRW_ESP 4000;
BA_ "NmhNode" BU_ Daempfer 0;
BA_ "VAGTP20_TargetAddress" BU_ Daempfer 12;
BA_ "NmhNode" BU_ EPB_TRW 0;
BA_ "VAGTP20_TargetAddress" BU_ EPB_TRW 25;
BA_ "NodeLayerModules" BU_ EPB_TRW_VW411CS "NMHigh.DLL";
BA_ "NmhNode" BU_ FLA 0;
BA_ "VAGTP20_TargetAddress" BU_ FLA 22;
BA_ "NodeLayerModules" BU_ Gateway_PQ35 "NMHigh.DLL";
BA_ "GenNodSleepTime" BU_ Gateway_PQ35 4000;
BA_ "NmhNode" BU_ Gateway_Zusatz_EGolf 0;
BA_ "GenNodSleepTime" BU_ Gateway_Zusatz_EGolf 4000;
BA_ "NmhNode" BU_ Getriebe_AG6 0;
BA_ "VAGTP20_TargetAddress" BU_ Getriebe_AG6 2;
BA_ "NmhNode" BU_ Getriebe_DQ 0;
BA_ "VAGTP20_TargetAddress" BU_ Getriebe_DQ 2;
BA_ "NmhNode" BU_ Getriebe_DQ_Hyb 0;
BA_ "VAGTP20_TargetAddress" BU_ Getriebe_DQ_Hyb 2;
BA_ "NmhNode" BU_ Getriebe_Sele 0;
BA_ "VAGTP20_TargetAddress" BU_ Getriebe_Sele 2;
BA_ "NmhNode" BU_ Gurtmikro_PQ35 0;
BA_ "ILUsed" BU_ Gurtmikro_PQ35 0;
BA_ "GenNodSleepTime" BU_ Gurtmikro_PQ35 30000;
BA_ "NmhNode" BU_ HCA 0;
BA_ "VAGTP20_TargetAddress" BU_ HCA 26;
BA_ "NodeLayerModules" BU_ Ladegeraet_EGolf "NMHigh.DLL";
BA_ "GenNodSleepTime" BU_ Ladegeraet_EGolf 4000;
BA_ "NodeLayerModules" BU_ LEH_Hybrid "NMHigh.DLL";
BA_ "GenNodSleepTime" BU_ LEH_Hybrid 4000;
BA_ "NmhNode" BU_ LH_EPS_APA 0;
BA_ "VAGTP20_TargetAddress" BU_ LH_EPS_APA 9;
BA_ "NmhNode" BU_ LH_EPS_ZF_2G 0;
BA_ "VAGTP20_TargetAddress" BU_ LH_EPS_ZF_2G 9;
BA_ "NmhNode" BU_ LH_EPS_ZF_3G 0;
BA_ "NmhNode" BU_ LPG_Interface_Box 0;
BA_ "GenNodSleepTime" BU_ LPG_Interface_Box 4000;
BA_ "NmhNode" BU_ LWR 0;
BA_ "VAGTP20_TargetAddress" BU_ LWR 6;
BA_ "NmhNode" BU_ LWS 0;
BA_ "VAGTP20_TargetAddress" BU_ LWS 19;
BA_ "NmhNode" BU_ Magne_Ride 0;
BA_ "VAGTP20_TargetAddress" BU_ Magne_Ride 12;
BA_ "NodeLayerModules" BU_ Motor_Diesel "NMHigh.DLL";
BA_ "VAGTP20_TargetAddress" BU_ Motor_Diesel 1;
BA_ "GenNodSleepTime" BU_ Motor_Diesel 4000;
BA_ "NodeLayerModules" BU_ Motor_EGolf "NMHigh.DLL";
BA_ "GenNodSleepTime" BU_ Motor_EGolf 30000;
BA_ "NodeLayerModules" BU_ Motor_Hybrid "NMHigh.DLL";
BA_ "VAGTP20_TargetAddress" BU_ Motor_Hybrid 1;
BA_ "GenNodSleepTime" BU_ Motor_Hybrid 4000;
BA_ "NodeLayerModules" BU_ Motor_Otto "NMHigh.DLL";
BA_ "VAGTP20_TargetAddress" BU_ Motor_Otto 1;
BA_ "GenNodSleepTime" BU_ Motor_Otto 4000;
BA_ "NmhNode" BU_ PDC_PLA 0;
BA_ "VAGTP20_TargetAddress" BU_ PDC_PLA 29;
BA_ "NmhNode" BU_ Quersperre_VAQ 0;
BA_ "VAGTP20_TargetAddress" BU_ Quersperre_VAQ 24;
BA_ "NmhNode" BU_ RKA_Plus 0;
BA_ "VAGTP20_TargetAddress" BU_ RKA_Plus 8;
BA_ "NmhNode" BU_ SAK 0;
BA_ "ILUsed" BU_ SAK 0;
BA_ "NmhNode" BU_ Waehlhebel 0;
BA_ "NmhNode" BU_ Waehlhebel_Sele 0;
BA_ "Timeoutzeit" BO_ 946 1000;
BA_ "GenMsgSendType" BO_ 946 0;
BA_ "GenMsgILSupport" BO_ 946 1;
BA_ "GenMsgCycleTime" BO_ 946 100;
BA_ "GenMsgSendType" BO_ 901 0;
BA_ "GenMsgILSupport" BO_ 901 1;
BA_ "GenMsgDelayTime" BO_ 901 20;
BA_ "GenMsgCycleTime" BO_ 901 1000;
BA_ "GenMsgSendType" BO_ 902 0;
BA_ "GenMsgILSupport" BO_ 902 1;
BA_ "GenMsgDelayTime" BO_ 902 20;
BA_ "GenMsgCycleTime" BO_ 902 1000;
BA_ "Timeoutzeit" BO_ 945 1000;
BA_ "GenMsgSendType" BO_ 945 0;
BA_ "GenMsgILSupport" BO_ 945 1;
BA_ "GenMsgCycleTime" BO_ 945 100;
BA_ "GenMsgSendType" BO_ 18 7;
BA_ "GenMsgSendType" BO_ 17 7;
BA_ "GenMsgSendType" BO_ 21 7;
BA_ "GenMsgSendType" BO_ 23 7;
BA_ "GenMsgSendType" BO_ 25 7;
BA_ "DiagRequest" BO_ 1811 1;
BA_ "GenMsgAutoGenSnd" BO_ 1811 0;
BA_ "GenMsgAutoGenDsp" BO_ 1811 0;
BA_ "DiagResponse" BO_ 1917 1;
BA_ "GenMsgAutoGenSnd" BO_ 1917 0;
BA_ "GenMsgAutoGenDsp" BO_ 1917 0;
BA_ "DiagRequest" BO_ 1879 1;
BA_ "GenMsgAutoGenSnd" BO_ 1879 0;
BA_ "GenMsgAutoGenDsp" BO_ 1879 0;
BA_ "DiagResponse" BO_ 1985 1;
BA_ "GenMsgAutoGenSnd" BO_ 1985 0;
BA_ "GenMsgAutoGenDsp" BO_ 1985 0;
BA_ "DiagRequest" BO_ 1813 1;
BA_ "GenMsgAutoGenSnd" BO_ 1813 0;
BA_ "GenMsgAutoGenDsp" BO_ 1813 0;
BA_ "DiagResponse" BO_ 1919 1;
BA_ "GenMsgAutoGenSnd" BO_ 1919 0;
BA_ "GenMsgAutoGenDsp" BO_ 1919 0;
BA_ "DiagRequest" BO_ 1874 1;
BA_ "GenMsgAutoGenSnd" BO_ 1874 0;
BA_ "GenMsgAutoGenDsp" BO_ 1874 0;
BA_ "DiagResponse" BO_ 1980 1;
BA_ "GenMsgAutoGenSnd" BO_ 1980 0;
BA_ "GenMsgAutoGenDsp" BO_ 1980 0;
BA_ "DiagRequest" BO_ 1802 1;
BA_ "GenMsgAutoGenSnd" BO_ 1802 0;
BA_ "GenMsgAutoGenDsp" BO_ 1802 0;
BA_ "DiagResponse" BO_ 1908 1;
BA_ "GenMsgAutoGenSnd" BO_ 1908 0;
BA_ "GenMsgAutoGenDsp" BO_ 1908 0;
BA_ "DiagState" BO_ 1792 1;
BA_ "GenMsgAutoGenSnd" BO_ 1792 0;
BA_ "GenMsgAutoGenDsp" BO_ 1792 0;
BA_ "DiagState" BO_ 2015 1;
BA_ "GenMsgAutoGenSnd" BO_ 2015 0;
BA_ "GenMsgAutoGenDsp" BO_ 2015 0;
BA_ "DiagRequest" BO_ 2017 1;
BA_ "GenMsgAutoGenSnd" BO_ 2017 0;
BA_ "GenMsgAutoGenDsp" BO_ 2017 0;
BA_ "DiagResponse" BO_ 2025 1;
BA_ "GenMsgAutoGenSnd" BO_ 2025 0;
BA_ "GenMsgAutoGenDsp" BO_ 2025 0;
BA_ "DiagRequest" BO_ 1891 1;
BA_ "GenMsgAutoGenSnd" BO_ 1891 0;
BA_ "GenMsgAutoGenDsp" BO_ 1891 0;
BA_ "DiagResponse" BO_ 1997 1;
BA_ "GenMsgAutoGenSnd" BO_ 1997 0;
BA_ "GenMsgAutoGenDsp" BO_ 1997 0;
BA_ "DiagRequest" BO_ 1893 1;
BA_ "GenMsgAutoGenSnd" BO_ 1893 0;
BA_ "GenMsgAutoGenDsp" BO_ 1893 0;
BA_ "DiagResponse" BO_ 1999 1;
BA_ "GenMsgAutoGenSnd" BO_ 1999 0;
BA_ "GenMsgAutoGenDsp" BO_ 1999 0;
BA_ "DiagRequest" BO_ 1810 1;
BA_ "GenMsgAutoGenSnd" BO_ 1810 0;
BA_ "GenMsgAutoGenDsp" BO_ 1810 0;
BA_ "DiagResponse" BO_ 1916 1;
BA_ "GenMsgAutoGenSnd" BO_ 1916 0;
BA_ "GenMsgAutoGenDsp" BO_ 1916 0;
BA_ "DiagRequest" BO_ 1876 1;
BA_ "GenMsgAutoGenSnd" BO_ 1876 0;
BA_ "GenMsgAutoGenDsp" BO_ 1876 0;
BA_ "DiagResponse" BO_ 1982 1;
BA_ "GenMsgAutoGenSnd" BO_ 1982 0;
BA_ "GenMsgAutoGenDsp" BO_ 1982 0;
BA_ "DiagRequest" BO_ 2016 1;
BA_ "GenMsgAutoGenSnd" BO_ 2016 0;
BA_ "GenMsgAutoGenDsp" BO_ 2016 0;
BA_ "DiagResponse" BO_ 2024 1;
BA_ "GenMsgAutoGenSnd" BO_ 2024 0;
BA_ "GenMsgAutoGenDsp" BO_ 2024 0;
BA_ "DiagRequest" BO_ 2018 1;
BA_ "GenMsgAutoGenSnd" BO_ 2018 0;
BA_ "GenMsgAutoGenDsp" BO_ 2018 0;
BA_ "DiagResponse" BO_ 2026 1;
BA_ "GenMsgAutoGenSnd" BO_ 2026 0;
BA_ "GenMsgAutoGenDsp" BO_ 2026 0;
BA_ "DiagRequest" BO_ 2021 1;
BA_ "GenMsgAutoGenSnd" BO_ 2021 0;
BA_ "GenMsgAutoGenDsp" BO_ 2021 0;
BA_ "DiagResponse" BO_ 2029 1;
BA_ "GenMsgAutoGenSnd" BO_ 2029 0;
BA_ "GenMsgAutoGenDsp" BO_ 2029 0;
BA_ "DiagRequest" BO_ 2022 1;
BA_ "GenMsgAutoGenSnd" BO_ 2022 0;
BA_ "GenMsgAutoGenDsp" BO_ 2022 0;
BA_ "DiagResponse" BO_ 2030 1;
BA_ "GenMsgAutoGenSnd" BO_ 2030 0;
BA_ "GenMsgAutoGenDsp" BO_ 2030 0;
BA_ "DiagRequest" BO_ 2019 1;
BA_ "GenMsgAutoGenSnd" BO_ 2019 0;
BA_ "GenMsgAutoGenDsp" BO_ 2019 0;
BA_ "DiagResponse" BO_ 2027 1;
BA_ "GenMsgAutoGenSnd" BO_ 2027 0;
BA_ "GenMsgAutoGenDsp" BO_ 2027 0;
BA_ "DiagRequest" BO_ 2020 1;
BA_ "GenMsgAutoGenSnd" BO_ 2020 0;
BA_ "GenMsgAutoGenDsp" BO_ 2020 0;
BA_ "DiagResponse" BO_ 2028 1;
BA_ "GenMsgAutoGenSnd" BO_ 2028 0;
BA_ "GenMsgAutoGenDsp" BO_ 2028 0;
BA_ "DiagRequest" BO_ 2023 1;
BA_ "GenMsgAutoGenSnd" BO_ 2023 0;
BA_ "GenMsgAutoGenDsp" BO_ 2023 0;
BA_ "DiagResponse" BO_ 2031 1;
BA_ "GenMsgAutoGenSnd" BO_ 2031 0;
BA_ "GenMsgAutoGenDsp" BO_ 2031 0;
BA_ "GenMsgSendType" BO_ 1386 0;
BA_ "GenMsgILSupport" BO_ 1386 1;
BA_ "GenMsgCycleTime" BO_ 1386 40;
BA_ "GenMsgSendType" BO_ 872 0;
BA_ "GenMsgILSupport" BO_ 872 1;
BA_ "GenMsgCycleTime" BO_ 872 20;
BA_ "GenMsgSendType" BO_ 1688 0;
BA_ "GenMsgILSupport" BO_ 1688 1;
BA_ "GenMsgCycleTime" BO_ 1688 100;
BA_ "GenMsgSendType" BO_ 80 0;
BA_ "GenMsgILSupport" BO_ 80 1;
BA_ "GenMsgCycleTime" BO_ 80 20;
BA_ "GenMsgSendType" BO_ 1360 0;
BA_ "GenMsgILSupport" BO_ 1360 1;
BA_ "GenMsgCycleTime" BO_ 1360 200;
BA_ "GenMsgSendType" BO_ 704 0;
BA_ "GenMsgILSupport" BO_ 704 1;
BA_ "GenMsgCycleTime" BO_ 704 10;
BA_ "GenMsgSendType" BO_ 870 0;
BA_ "GenMsgILSupport" BO_ 870 1;
BA_ "GenMsgCycleTimeFast" BO_ 870 20;
BA_ "GenMsgCycleTime" BO_ 870 40;
BA_ "GenMsgSendType" BO_ 1404 0;
BA_ "GenMsgILSupport" BO_ 1404 1;
BA_ "GenMsgCycleTime" BO_ 1404 1000;
BA_ "GenMsgSendType" BO_ 416 0;
BA_ "GenMsgILSupport" BO_ 416 1;
BA_ "GenMsgCycleTime" BO_ 416 10;
BA_ "GenMsgSendType" BO_ 928 0;
BA_ "GenMsgILSupport" BO_ 928 1;
BA_ "GenMsgCycleTime" BO_ 928 20;
BA_ "GenSigSendType" SG_ 1652 BAP_Data_ACC 3;
BA_ "GenSigAutoGenSnd" SG_ 1652 BAP_Data_ACC 1;
BA_ "GenSigAutoGenDsp" SG_ 1652 BAP_Data_ACC 1;
BA_ "GenSigSwitchedByIgnition" SG_ 1654 BAP_Data_Anzeige 0;
BA_ "GenSigSendType" SG_ 1654 BAP_Data_Anzeige 3;
BA_ "GenSigAutoGenSnd" SG_ 1654 BAP_Data_Anzeige 1;
BA_ "GenSigAutoGenDsp" SG_ 1654 BAP_Data_Anzeige 1;
BA_ "GenSigSwitchedByIgnition" SG_ 1658 BAP_Data_Anzeige_02 0;
BA_ "GenSigSendType" SG_ 1658 BAP_Data_Anzeige_02 3;
BA_ "GenSigAutoGenSnd" SG_ 1658 BAP_Data_Anzeige_02 1;
BA_ "GenSigAutoGenDsp" SG_ 1658 BAP_Data_Anzeige_02 1;
BA_ "GenSigSwitchedByIgnition" SG_ 1750 BAP_Data_Debug_Cmd 0;
BA_ "GenSigSendType" SG_ 1750 BAP_Data_Debug_Cmd 3;
BA_ "GenSigAutoGenSnd" SG_ 1750 BAP_Data_Debug_Cmd 1;
BA_ "GenSigAutoGenDsp" SG_ 1750 BAP_Data_Debug_Cmd 1;
BA_ "GenSigSwitchedByIgnition" SG_ 1751 BAP_Debug_Data 0;
BA_ "GenSigSendType" SG_ 1751 BAP_Debug_Data 3;
BA_ "GenSigAutoGenSnd" SG_ 1751 BAP_Debug_Data 1;
BA_ "GenSigAutoGenDsp" SG_ 1751 BAP_Debug_Data 1;
BA_ "GenSigSwitchedByIgnition" SG_ 1657 BAP_Data_HYB 0;
BA_ "GenSigSendType" SG_ 1657 BAP_Data_HYB 3;
BA_ "GenSigAutoGenSnd" SG_ 1657 BAP_Data_HYB 1;
BA_ "GenSigAutoGenDsp" SG_ 1657 BAP_Data_HYB 1;
BA_ "GenSigSendType" SG_ 1651 BAP_Data_LDW 3;
BA_ "GenSigAutoGenSnd" SG_ 1651 BAP_Data_LDW 1;
BA_ "GenSigAutoGenDsp" SG_ 1651 BAP_Data_LDW 1;
BA_ "GenSigSendType" SG_ 1754 BAP_Data_OPS 3;
BA_ "GenSigAutoGenSnd" SG_ 1754 BAP_Data_OPS 1;
BA_ "GenSigAutoGenDsp" SG_ 1754 BAP_Data_OPS 1;
BA_ "Fehlerwert" SG_ 946 BEM_HYB_DC_uMinLV 255;
BA_ "GenSigStartValue" SG_ 946 BEM_HYB_DC_uMinLV 254;
BA_ "GenSigSendType" SG_ 946 BEM_HYB_DC_uMinLV 0;
BA_ "GenSigAutoGenSnd" SG_ 946 BEM_HYB_DC_uMinLV 1;
BA_ "GenSigAutoGenDsp" SG_ 946 BEM_HYB_DC_uMinLV 1;
BA_ "GenSigStartValue" SG_ 946 BEM_HYB_DC_uSollLV 37;
BA_ "GenSigSendType" SG_ 946 BEM_HYB_DC_uSollLV 0;
BA_ "GenSigAutoGenSnd" SG_ 946 BEM_HYB_DC_uSollLV 1;
BA_ "GenSigAutoGenDsp" SG_ 946 BEM_HYB_DC_uSollLV 1;
BA_ "GenSigSwitchedByIgnition" SG_ 901 CHA_Ziel_FahrPr_MO 0;
BA_ "GenSigSendType" SG_ 901 CHA_Ziel_FahrPr_MO 1;
BA_ "GenSigEnvVarType" SG_ 901 CHA_Ziel_FahrPr_MO 0;
BA_ "GenSigAutoGenSnd" SG_ 901 CHA_Ziel_FahrPr_MO 1;
BA_ "GenSigAutoGenDsp" SG_ 901 CHA_Ziel_FahrPr_MO 1;
BA_ "GenSigSwitchedByIgnition" SG_ 901 CHA_Ziel_FahrPr_GE 0;
BA_ "GenSigSendType" SG_ 901 CHA_Ziel_FahrPr_GE 1;
BA_ "GenSigEnvVarType" SG_ 901 CHA_Ziel_FahrPr_GE 0;
BA_ "GenSigAutoGenSnd" SG_ 901 CHA_Ziel_FahrPr_GE 1;
BA_ "GenSigAutoGenDsp" SG_ 901 CHA_Ziel_FahrPr_GE 1;
BA_ "GenSigSwitchedByIgnition" SG_ 902 CHA_Ziel_FahrPr_KL 0;
BA_ "GenSigSendType" SG_ 902 CHA_Ziel_FahrPr_KL 1;
BA_ "GenSigEnvVarType" SG_ 902 CHA_Ziel_FahrPr_KL 0;
BA_ "GenSigAutoGenSnd" SG_ 902 CHA_Ziel_FahrPr_KL 1;
BA_ "GenSigAutoGenDsp" SG_ 902 CHA_Ziel_FahrPr_KL 1;
BA_ "GenSigSwitchedByIgnition" SG_ 902 CHA_Kombi_Texte 0;
BA_ "GenSigSendType" SG_ 902 CHA_Kombi_Texte 1;
BA_ "Fehlerwert" SG_ 945 DC_HYB_iAktLV 1023;
BA_ "GenSigStartValue" SG_ 945 DC_HYB_iAktLV 1022;
BA_ "GenSigSendType" SG_ 945 DC_HYB_iAktLV 0;
BA_ "GenSigAutoGenSnd" SG_ 945 DC_HYB_iAktLV 1;
BA_ "GenSigAutoGenDsp" SG_ 945 DC_HYB_iAktLV 1;
BA_ "Fehlerwert" SG_ 945 DC_HYB_iAktReserveLV 1023;
BA_ "GenSigStartValue" SG_ 945 DC_HYB_iAktReserveLV 1022;
BA_ "GenSigSendType" SG_ 945 DC_HYB_iAktReserveLV 0;
BA_ "GenSigAutoGenSnd" SG_ 945 DC_HYB_iAktReserveLV 1;
BA_ "GenSigAutoGenDsp" SG_ 945 DC_HYB_iAktReserveLV 1;
BA_ "Fehlerwert" SG_ 945 DC_HYB_uAktLV 255;
BA_ "GenSigStartValue" SG_ 945 DC_HYB_uAktLV 254;
BA_ "GenSigSendType" SG_ 945 DC_HYB_uAktLV 0;
BA_ "GenSigAutoGenSnd" SG_ 945 DC_HYB_uAktLV 1;
BA_ "GenSigAutoGenDsp" SG_ 945 DC_HYB_uAktLV 1;
BA_ "GenSigSendType" SG_ 945 DC_HYB_LangsRegelung 0;
BA_ "GenSigAutoGenSnd" SG_ 945 DC_HYB_LangsRegelung 1;
BA_ "GenSigAutoGenDsp" SG_ 945 DC_HYB_LangsRegelung 1;
BA_ "GenSigSendType" SG_ 945 DC_HYB_Abregelung_Temperatur 0;
BA_ "GenSigAutoGenSnd" SG_ 945 DC_HYB_Abregelung_Temperatur 1;
BA_ "GenSigAutoGenDsp" SG_ 945 DC_HYB_Abregelung_Temperatur 1;
BA_ "GenSigSendType" SG_ 945 DC_HYB_Fehler_RedLeistung 0;
BA_ "GenSigAutoGenSnd" SG_ 945 DC_HYB_Fehler_RedLeistung 1;
BA_ "GenSigAutoGenDsp" SG_ 945 DC_HYB_Fehler_RedLeistung 1;
BA_ "GenSigSendType" SG_ 945 DC_HYB_Fehler_intern 0;
BA_ "GenSigAutoGenSnd" SG_ 945 DC_HYB_Fehler_intern 1;
BA_ "GenSigAutoGenDsp" SG_ 945 DC_HYB_Fehler_intern 1;
BA_ "GenSigSendType" SG_ 945 DC_HYB_Fehler_Spannung 0;
BA_ "GenSigAutoGenSnd" SG_ 945 DC_HYB_Fehler_Spannung 1;
BA_ "GenSigAutoGenDsp" SG_ 945 DC_HYB_Fehler_Spannung 1;
BA_ "Fehlerwert" SG_ 945 DC_HYB_Auslastungsgrad 255;
BA_ "GenSigStartValue" SG_ 945 DC_HYB_Auslastungsgrad 254;
BA_ "GenSigSendType" SG_ 945 DC_HYB_Auslastungsgrad 0;
BA_ "GenSigAutoGenSnd" SG_ 945 DC_HYB_Auslastungsgrad 1;
BA_ "GenSigAutoGenDsp" SG_ 945 DC_HYB_Auslastungsgrad 1;
BA_ "GenSigSwitchedByIgnition" SG_ 18 GSG_WFS_RND 0;
BA_ "GenSigSendType" SG_ 18 GSG_WFS_RND 3;
BA_ "GenSigAutoGenSnd" SG_ 18 GSG_WFS_RND 1;
BA_ "GenSigAutoGenDsp" SG_ 18 GSG_WFS_RND 1;
BA_ "GenSigSwitchedByIgnition" SG_ 18 GSG_WFS_SIG_E 0;
BA_ "GenSigSendType" SG_ 18 GSG_WFS_SIG_E 3;
BA_ "GenSigAutoGenSnd" SG_ 18 GSG_WFS_SIG_E 1;
BA_ "GenSigAutoGenDsp" SG_ 18 GSG_WFS_SIG_E 1;
BA_ "GenSigSwitchedByIgnition" SG_ 18 GSG_WFS_P_Klasse 0;
BA_ "GenSigSendType" SG_ 18 GSG_WFS_P_Klasse 3;
BA_ "GenSigSwitchedByIgnition" SG_ 19 WFS_GSG_SIG_S 0;
BA_ "GenSigSendType" SG_ 19 WFS_GSG_SIG_S 3;
BA_ "GenSigAutoGenSnd" SG_ 19 WFS_GSG_SIG_S 1;
BA_ "GenSigAutoGenDsp" SG_ 19 WFS_GSG_SIG_S 1;
BA_ "GenSigSwitchedByIgnition" SG_ 19 WFS_GSG_Status_Antwort 0;
BA_ "GenSigSendType" SG_ 19 WFS_GSG_Status_Antwort 3;
BA_ "GenSigAutoGenSnd" SG_ 19 WFS_GSG_Status_Antwort 1;
BA_ "GenSigAutoGenDsp" SG_ 19 WFS_GSG_Status_Antwort 1;
BA_ "GenSigSwitchedByIgnition" SG_ 19 WFS_GSG_Status_Lesespule 0;
BA_ "GenSigSendType" SG_ 19 WFS_GSG_Status_Lesespule 3;
BA_ "GenSigAutoGenSnd" SG_ 19 WFS_GSG_Status_Lesespule 1;
BA_ "GenSigAutoGenDsp" SG_ 19 WFS_GSG_Status_Lesespule 1;
BA_ "GenSigSwitchedByIgnition" SG_ 19 WFS_GSG_Status_Schluessel 0;
BA_ "GenSigSendType" SG_ 19 WFS_GSG_Status_Schluessel 3;
BA_ "GenSigAutoGenSnd" SG_ 19 WFS_GSG_Status_Schluessel 1;
BA_ "GenSigAutoGenDsp" SG_ 19 WFS_GSG_Status_Schluessel 1;
BA_ "GenSigSwitchedByIgnition" SG_ 19 WFS_GSG_Status_Anfrage 0;
BA_ "GenSigSendType" SG_ 19 WFS_GSG_Status_Anfrage 3;
BA_ "GenSigAutoGenSnd" SG_ 19 WFS_GSG_Status_Anfrage 1;
BA_ "GenSigAutoGenDsp" SG_ 19 WFS_GSG_Status_Anfrage 1;
BA_ "GenSigSwitchedByIgnition" SG_ 19 WFS_GSG_Status_P_Klasse 0;
BA_ "GenSigSendType" SG_ 19 WFS_GSG_Status_P_Klasse 3;
BA_ "GenSigAutoGenSnd" SG_ 19 WFS_GSG_Status_P_Klasse 1;
BA_ "GenSigAutoGenDsp" SG_ 19 WFS_GSG_Status_P_Klasse 1;
BA_ "GenSigSwitchedByIgnition" SG_ 17 WFS_MSG1_SIG_S 0;
BA_ "GenSigSendType" SG_ 17 WFS_MSG1_SIG_S 3;
BA_ "GenSigAutoGenSnd" SG_ 17 WFS_MSG1_SIG_S 1;
BA_ "GenSigAutoGenDsp" SG_ 17 WFS_MSG1_SIG_S 1;
BA_ "GenSigSwitchedByIgnition" SG_ 17 WFS_MSG1_Status_Antwort 0;
BA_ "GenSigSendType" SG_ 17 WFS_MSG1_Status_Antwort 3;
BA_ "GenSigAutoGenSnd" SG_ 17 WFS_MSG1_Status_Antwort 1;
BA_ "GenSigAutoGenDsp" SG_ 17 WFS_MSG1_Status_Antwort 1;
BA_ "GenSigSwitchedByIgnition" SG_ 17 WFS_MSG1_Status_Lesespule 0;
BA_ "GenSigSendType" SG_ 17 WFS_MSG1_Status_Lesespule 3;
BA_ "GenSigAutoGenSnd" SG_ 17 WFS_MSG1_Status_Lesespule 1;
BA_ "GenSigAutoGenDsp" SG_ 17 WFS_MSG1_Status_Lesespule 1;
BA_ "GenSigSwitchedByIgnition" SG_ 17 WFS_MSG1_Status_Schluessel 0;
BA_ "GenSigSendType" SG_ 17 WFS_MSG1_Status_Schluessel 3;
BA_ "GenSigAutoGenSnd" SG_ 17 WFS_MSG1_Status_Schluessel 1;
BA_ "GenSigAutoGenDsp" SG_ 17 WFS_MSG1_Status_Schluessel 1;
BA_ "GenSigSwitchedByIgnition" SG_ 17 WFS_MSG1_Status_Anfrage 0;
BA_ "GenSigSendType" SG_ 17 WFS_MSG1_Status_Anfrage 3;
BA_ "GenSigAutoGenSnd" SG_ 17 WFS_MSG1_Status_Anfrage 1;
BA_ "GenSigAutoGenDsp" SG_ 17 WFS_MSG1_Status_Anfrage 1;
BA_ "GenSigSwitchedByIgnition" SG_ 17 WFS_MSG1_Status_P_Klasse 0;
BA_ "GenSigSendType" SG_ 17 WFS_MSG1_Status_P_Klasse 3;
BA_ "GenSigAutoGenSnd" SG_ 17 WFS_MSG1_Status_P_Klasse 1;
BA_ "GenSigAutoGenDsp" SG_ 17 WFS_MSG1_Status_P_Klasse 1;
BA_ "GenSigSwitchedByIgnition" SG_ 21 WFS_MSG2_SIG_S 0;
BA_ "GenSigSendType" SG_ 21 WFS_MSG2_SIG_S 3;
BA_ "GenSigAutoGenSnd" SG_ 21 WFS_MSG2_SIG_S 1;
BA_ "GenSigAutoGenDsp" SG_ 21 WFS_MSG2_SIG_S 1;
BA_ "GenSigSwitchedByIgnition" SG_ 21 WFS_MSG2_Status_Antwort 0;
BA_ "GenSigSendType" SG_ 21 WFS_MSG2_Status_Antwort 3;
BA_ "GenSigAutoGenSnd" SG_ 21 WFS_MSG2_Status_Antwort 1;
BA_ "GenSigAutoGenDsp" SG_ 21 WFS_MSG2_Status_Antwort 1;
BA_ "GenSigSwitchedByIgnition" SG_ 21 WFS_MSG2_Status_Lesespule 0;
BA_ "GenSigSendType" SG_ 21 WFS_MSG2_Status_Lesespule 3;
BA_ "GenSigAutoGenSnd" SG_ 21 WFS_MSG2_Status_Lesespule 1;
BA_ "GenSigAutoGenDsp" SG_ 21 WFS_MSG2_Status_Lesespule 1;
BA_ "GenSigSwitchedByIgnition" SG_ 21 WFS_MSG2_Status_Schluessel 0;
BA_ "GenSigSendType" SG_ 21 WFS_MSG2_Status_Schluessel 3;
BA_ "GenSigAutoGenSnd" SG_ 21 WFS_MSG2_Status_Schluessel 1;
BA_ "GenSigAutoGenDsp" SG_ 21 WFS_MSG2_Status_Schluessel 1;
BA_ "GenSigSwitchedByIgnition" SG_ 21 WFS_MSG2_Status_Anfrage 0;
BA_ "GenSigSendType" SG_ 21 WFS_MSG2_Status_Anfrage 3;
BA_ "GenSigAutoGenSnd" SG_ 21 WFS_MSG2_Status_Anfrage 1;
BA_ "GenSigAutoGenDsp" SG_ 21 WFS_MSG2_Status_Anfrage 1;
BA_ "GenSigSwitchedByIgnition" SG_ 21 WFS_MSG2_Status_P_Klasse 0;
BA_ "GenSigSendType" SG_ 21 WFS_MSG2_Status_P_Klasse 3;
BA_ "GenSigAutoGenSnd" SG_ 21 WFS_MSG2_Status_P_Klasse 1;
BA_ "GenSigAutoGenDsp" SG_ 21 WFS_MSG2_Status_P_Klasse 1;
BA_ "GenSigSwitchedByIgnition" SG_ 23 WFS_MSG3_SIG_S 0;
BA_ "GenSigSendType" SG_ 23 WFS_MSG3_SIG_S 3;
BA_ "GenSigAutoGenSnd" SG_ 23 WFS_MSG3_SIG_S 1;
BA_ "GenSigAutoGenDsp" SG_ 23 WFS_MSG3_SIG_S 1;
BA_ "GenSigSwitchedByIgnition" SG_ 23 WFS_MSG3_Status_Antwort 0;
BA_ "GenSigSendType" SG_ 23 WFS_MSG3_Status_Antwort 3;
BA_ "GenSigAutoGenSnd" SG_ 23 WFS_MSG3_Status_Antwort 1;
BA_ "GenSigAutoGenDsp" SG_ 23 WFS_MSG3_Status_Antwort 1;
BA_ "GenSigSwitchedByIgnition" SG_ 23 WFS_MSG3_Status_Lesespule 0;
BA_ "GenSigSendType" SG_ 23 WFS_MSG3_Status_Lesespule 3;
BA_ "GenSigAutoGenSnd" SG_ 23 WFS_MSG3_Status_Lesespule 1;
BA_ "GenSigAutoGenDsp" SG_ 23 WFS_MSG3_Status_Lesespule 1;
BA_ "GenSigSwitchedByIgnition" SG_ 23 WFS_MSG3_Status_Schluessel 0;
BA_ "GenSigSendType" SG_ 23 WFS_MSG3_Status_Schluessel 3;
BA_ "GenSigAutoGenSnd" SG_ 23 WFS_MSG3_Status_Schluessel 1;
BA_ "GenSigAutoGenDsp" SG_ 23 WFS_MSG3_Status_Schluessel 1;
BA_ "GenSigSwitchedByIgnition" SG_ 23 WFS_MSG3_Status_Anfrage 0;
BA_ "GenSigSendType" SG_ 23 WFS_MSG3_Status_Anfrage 3;
BA_ "GenSigAutoGenSnd" SG_ 23 WFS_MSG3_Status_Anfrage 1;
BA_ "GenSigAutoGenDsp" SG_ 23 WFS_MSG3_Status_Anfrage 1;
BA_ "GenSigSwitchedByIgnition" SG_ 23 WFS_MSG3_Status_P_Klasse 0;
BA_ "GenSigSendType" SG_ 23 WFS_MSG3_Status_P_Klasse 3;
BA_ "GenSigAutoGenSnd" SG_ 23 WFS_MSG3_Status_P_Klasse 1;
BA_ "GenSigAutoGenDsp" SG_ 23 WFS_MSG3_Status_P_Klasse 1;
BA_ "GenSigSwitchedByIgnition" SG_ 25 WFS_MSG4_SIG_S 0;
BA_ "GenSigSendType" SG_ 25 WFS_MSG4_SIG_S 3;
BA_ "GenSigAutoGenSnd" SG_ 25 WFS_MSG4_SIG_S 1;
BA_ "GenSigAutoGenDsp" SG_ 25 WFS_MSG4_SIG_S 1;
BA_ "GenSigSwitchedByIgnition" SG_ 25 WFS_MSG4_Status_Antwort 0;
BA_ "GenSigSendType" SG_ 25 WFS_MSG4_Status_Antwort 3;
BA_ "GenSigAutoGenSnd" SG_ 25 WFS_MSG4_Status_Antwort 1;
BA_ "GenSigAutoGenDsp" SG_ 25 WFS_MSG4_Status_Antwort 1;
BA_ "GenSigSwitchedByIgnition" SG_ 25 WFS_MSG4_Status_Lesespule 0;
BA_ "GenSigSendType" SG_ 25 WFS_MSG4_Status_Lesespule 3;
BA_ "GenSigAutoGenSnd" SG_ 25 WFS_MSG4_Status_Lesespule 1;
BA_ "GenSigAutoGenDsp" SG_ 25 WFS_MSG4_Status_Lesespule 1;
BA_ "GenSigSwitchedByIgnition" SG_ 25 WFS_MSG4_Status_Schluessel 0;
BA_ "GenSigSendType" SG_ 25 WFS_MSG4_Status_Schluessel 3;
BA_ "GenSigAutoGenSnd" SG_ 25 WFS_MSG4_Status_Schluessel 1;
BA_ "GenSigAutoGenDsp" SG_ 25 WFS_MSG4_Status_Schluessel 1;
BA_ "GenSigSwitchedByIgnition" SG_ 25 WFS_MSG4_Status_Anfrage 0;
BA_ "GenSigSendType" SG_ 25 WFS_MSG4_Status_Anfrage 3;
BA_ "GenSigAutoGenSnd" SG_ 25 WFS_MSG4_Status_Anfrage 1;
BA_ "GenSigAutoGenDsp" SG_ 25 WFS_MSG4_Status_Anfrage 1;
BA_ "GenSigSwitchedByIgnition" SG_ 25 WFS_MSG4_Status_P_Klasse 0;
BA_ "GenSigSendType" SG_ 25 WFS_MSG4_Status_P_Klasse 3;
BA_ "GenSigAutoGenSnd" SG_ 25 WFS_MSG4_Status_P_Klasse 1;
BA_ "GenSigAutoGenDsp" SG_ 25 WFS_MSG4_Status_P_Klasse 1;
BA_ "GenSigSwitchedByIgnition" SG_ 1811 ISO_ABS_Req_Data 0;
BA_ "GenSigSendType" SG_ 1811 ISO_ABS_Req_Data 3;
BA_ "GenSigAutoGenSnd" SG_ 1811 ISO_ABS_Req_Data 1;
BA_ "GenSigAutoGenDsp" SG_ 1811 ISO_ABS_Req_Data 1;
BA_ "GenSigSwitchedByIgnition" SG_ 1917 ISO_ABS_Resp_Data 0;
BA_ "GenSigSendType" SG_ 1917 ISO_ABS_Resp_Data 3;
BA_ "GenSigAutoGenSnd" SG_ 1917 ISO_ABS_Resp_Data 1;
BA_ "GenSigAutoGenDsp" SG_ 1917 ISO_ABS_Resp_Data 1;
BA_ "GenSigSwitchedByIgnition" SG_ 1879 ISO_ACC_Req_Data 0;
BA_ "GenSigSendType" SG_ 1879 ISO_ACC_Req_Data 3;
BA_ "GenSigAutoGenSnd" SG_ 1879 ISO_ACC_Req_Data 1;
BA_ "GenSigAutoGenDsp" SG_ 1879 ISO_ACC_Req_Data 1;
BA_ "GenSigSwitchedByIgnition" SG_ 1985 ISO_ACC_Resp_Data 0;
BA_ "GenSigSendType" SG_ 1985 ISO_ACC_Resp_Data 3;
BA_ "GenSigAutoGenSnd" SG_ 1985 ISO_ACC_Resp_Data 1;
BA_ "GenSigAutoGenDsp" SG_ 1985 ISO_ACC_Resp_Data 1;
BA_ "GenSigSwitchedByIgnition" SG_ 1813 ISO_Airbag_01_Req_Data 0;
BA_ "GenSigSendType" SG_ 1813 ISO_Airbag_01_Req_Data 3;
BA_ "GenSigAutoGenSnd" SG_ 1813 ISO_Airbag_01_Req_Data 1;
BA_ "GenSigAutoGenDsp" SG_ 1813 ISO_Airbag_01_Req_Data 1;
BA_ "GenSigSwitchedByIgnition" SG_ 1919 ISO_Airbag_01_Resp_Data 0;
BA_ "GenSigSendType" SG_ 1919 ISO_Airbag_01_Resp_Data 3;
BA_ "GenSigAutoGenSnd" SG_ 1919 ISO_Airbag_01_Resp_Data 1;
BA_ "GenSigAutoGenDsp" SG_ 1919 ISO_Airbag_01_Resp_Data 1;
BA_ "GenSigSwitchedByIgnition" SG_ 1874 ISO_EPB_Req_Data 0;
BA_ "GenSigSendType" SG_ 1874 ISO_EPB_Req_Data 3;
BA_ "GenSigAutoGenSnd" SG_ 1874 ISO_EPB_Req_Data 1;
BA_ "GenSigAutoGenDsp" SG_ 1874 ISO_EPB_Req_Data 1;
BA_ "GenSigSwitchedByIgnition" SG_ 1980 ISO_EPB_Resp_Data 0;
BA_ "GenSigSendType" SG_ 1980 ISO_EPB_Resp_Data 3;
BA_ "GenSigAutoGenSnd" SG_ 1980 ISO_EPB_Resp_Data 1;
BA_ "GenSigAutoGenDsp" SG_ 1980 ISO_EPB_Resp_Data 1;
BA_ "GenSigSwitchedByIgnition" SG_ 1802 ISO_EPH_Req_Data 0;
BA_ "GenSigSendType" SG_ 1802 ISO_EPH_Req_Data 3;
BA_ "GenSigAutoGenSnd" SG_ 1802 ISO_EPH_Req_Data 1;
BA_ "GenSigAutoGenDsp" SG_ 1802 ISO_EPH_Req_Data 1;
BA_ "GenSigSwitchedByIgnition" SG_ 1908 ISO_EPH_Resp_Data 0;
BA_ "GenSigSendType" SG_ 1908 ISO_EPH_Resp_Data 3;
BA_ "GenSigAutoGenSnd" SG_ 1908 ISO_EPH_Resp_Data 1;
BA_ "GenSigAutoGenDsp" SG_ 1908 ISO_EPH_Resp_Data 1;
BA_ "GenSigSwitchedByIgnition" SG_ 1792 ISO_ALL_01_Req_Data 0;
BA_ "GenSigSendType" SG_ 1792 ISO_ALL_01_Req_Data 3;
BA_ "GenSigAutoGenSnd" SG_ 1792 ISO_ALL_01_Req_Data 1;
BA_ "GenSigAutoGenDsp" SG_ 1792 ISO_ALL_01_Req_Data 1;
BA_ "GenSigSwitchedByIgnition" SG_ 2015 ISO_OBD_01_Req_Data 0;
BA_ "GenSigSendType" SG_ 2015 ISO_OBD_01_Req_Data 3;
BA_ "GenSigAutoGenSnd" SG_ 2015 ISO_OBD_01_Req_Data 1;
BA_ "GenSigAutoGenDsp" SG_ 2015 ISO_OBD_01_Req_Data 1;
BA_ "GenSigSwitchedByIgnition" SG_ 2017 ISO_Getriebe_01_Req_Data 0;
BA_ "GenSigSendType" SG_ 2017 ISO_Getriebe_01_Req_Data 3;
BA_ "GenSigAutoGenSnd" SG_ 2017 ISO_Getriebe_01_Req_Data 1;
BA_ "GenSigAutoGenDsp" SG_ 2017 ISO_Getriebe_01_Req_Data 1;
BA_ "GenSigSwitchedByIgnition" SG_ 2025 ISO_Getriebe_01_Resp_Data 0;
BA_ "GenSigSendType" SG_ 2025 ISO_Getriebe_01_Resp_Data 3;
BA_ "GenSigAutoGenSnd" SG_ 2025 ISO_Getriebe_01_Resp_Data 1;
BA_ "GenSigAutoGenDsp" SG_ 2025 ISO_Getriebe_01_Resp_Data 1;
BA_ "GenSigSwitchedByIgnition" SG_ 1891 ISO_Gurtmikro_Req_Data 0;
BA_ "GenSigSendType" SG_ 1891 ISO_Gurtmikro_Req_Data 3;
BA_ "GenSigAutoGenSnd" SG_ 1891 ISO_Gurtmikro_Req_Data 1;
BA_ "GenSigAutoGenDsp" SG_ 1891 ISO_Gurtmikro_Req_Data 1;
BA_ "GenSigSwitchedByIgnition" SG_ 1997 ISO_Gurtmikro_Resp_Data 0;
BA_ "GenSigSendType" SG_ 1997 ISO_Gurtmikro_Resp_Data 3;
BA_ "GenSigAutoGenSnd" SG_ 1997 ISO_Gurtmikro_Resp_Data 1;
BA_ "GenSigAutoGenDsp" SG_ 1997 ISO_Gurtmikro_Resp_Data 1;
BA_ "GenSigSwitchedByIgnition" SG_ 1893 ISO_Ladegeraet_Req_Data 0;
BA_ "GenSigSendType" SG_ 1893 ISO_Ladegeraet_Req_Data 3;
BA_ "GenSigAutoGenSnd" SG_ 1893 ISO_Ladegeraet_Req_Data 1;
BA_ "GenSigAutoGenDsp" SG_ 1893 ISO_Ladegeraet_Req_Data 1;
BA_ "GenSigSwitchedByIgnition" SG_ 1999 ISO_Ladegeraet_Resp_Data 0;
BA_ "GenSigSendType" SG_ 1999 ISO_Ladegeraet_Resp_Data 3;
BA_ "GenSigAutoGenSnd" SG_ 1999 ISO_Ladegeraet_Resp_Data 1;
BA_ "GenSigAutoGenDsp" SG_ 1999 ISO_Ladegeraet_Resp_Data 1;
BA_ "GenSigSwitchedByIgnition" SG_ 1810 ISO_Lenkhilfe_Req_Data 0;
BA_ "GenSigSendType" SG_ 1810 ISO_Lenkhilfe_Req_Data 3;
BA_ "GenSigAutoGenSnd" SG_ 1810 ISO_Lenkhilfe_Req_Data 1;
BA_ "GenSigAutoGenDsp" SG_ 1810 ISO_Lenkhilfe_Req_Data 1;
BA_ "GenSigSwitchedByIgnition" SG_ 1916 ISO_Lenkhilfe_Resp_Data 0;
BA_ "GenSigSendType" SG_ 1916 ISO_Lenkhilfe_Resp_Data 3;
BA_ "GenSigAutoGenSnd" SG_ 1916 ISO_Lenkhilfe_Resp_Data 1;
BA_ "GenSigAutoGenDsp" SG_ 1916 ISO_Lenkhilfe_Resp_Data 1;
BA_ "GenSigSwitchedByIgnition" SG_ 1876 ISO_LWRAFS_Req_Data 0;
BA_ "GenSigSendType" SG_ 1876 ISO_LWRAFS_Req_Data 3;
BA_ "GenSigAutoGenSnd" SG_ 1876 ISO_LWRAFS_Req_Data 1;
BA_ "GenSigAutoGenDsp" SG_ 1876 ISO_LWRAFS_Req_Data 1;
BA_ "GenSigSwitchedByIgnition" SG_ 1982 ISO_LWRAFS_Resp_Data 0;
BA_ "GenSigSendType" SG_ 1982 ISO_LWRAFS_Resp_Data 3;
BA_ "GenSigAutoGenSnd" SG_ 1982 ISO_LWRAFS_Resp_Data 1;
BA_ "GenSigAutoGenDsp" SG_ 1982 ISO_LWRAFS_Resp_Data 1;
BA_ "GenSigSwitchedByIgnition" SG_ 2016 ISO_MO_01_Req_Data 0;
BA_ "GenSigSendType" SG_ 2016 ISO_MO_01_Req_Data 3;
BA_ "GenSigAutoGenSnd" SG_ 2016 ISO_MO_01_Req_Data 1;
BA_ "GenSigAutoGenDsp" SG_ 2016 ISO_MO_01_Req_Data 1;
BA_ "GenSigSwitchedByIgnition" SG_ 2024 ISO_MO_01_Resp_Data 0;
BA_ "GenSigSendType" SG_ 2024 ISO_MO_01_Resp_Data 3;
BA_ "GenSigAutoGenSnd" SG_ 2024 ISO_MO_01_Resp_Data 1;
BA_ "GenSigAutoGenDsp" SG_ 2024 ISO_MO_01_Resp_Data 1;
BA_ "GenSigSwitchedByIgnition" SG_ 2018 ISO_MOS_01_Req_Data 0;
BA_ "GenSigSendType" SG_ 2018 ISO_MOS_01_Req_Data 3;
BA_ "GenSigAutoGenSnd" SG_ 2018 ISO_MOS_01_Req_Data 1;
BA_ "GenSigAutoGenDsp" SG_ 2018 ISO_MOS_01_Req_Data 1;
BA_ "GenSigSwitchedByIgnition" SG_ 2026 ISO_MOS_01_Resp_Data 0;
BA_ "GenSigSendType" SG_ 2026 ISO_MOS_01_Resp_Data 3;
BA_ "GenSigAutoGenSnd" SG_ 2026 ISO_MOS_01_Resp_Data 1;
BA_ "GenSigAutoGenDsp" SG_ 2026 ISO_MOS_01_Resp_Data 1;
BA_ "GenSigSwitchedByIgnition" SG_ 2021 ISO_OBD_BECM_Req_Data 0;
BA_ "GenSigSendType" SG_ 2021 ISO_OBD_BECM_Req_Data 3;
BA_ "GenSigAutoGenSnd" SG_ 2021 ISO_OBD_BECM_Req_Data 1;
BA_ "GenSigAutoGenDsp" SG_ 2021 ISO_OBD_BECM_Req_Data 1;
BA_ "GenSigSwitchedByIgnition" SG_ 2029 ISO_OBD_BECM_Resp_Data 0;
BA_ "GenSigSendType" SG_ 2029 ISO_OBD_BECM_Resp_Data 3;
BA_ "GenSigAutoGenSnd" SG_ 2029 ISO_OBD_BECM_Resp_Data 1;
BA_ "GenSigAutoGenDsp" SG_ 2029 ISO_OBD_BECM_Resp_Data 1;
BA_ "GenSigSwitchedByIgnition" SG_ 2022 ISO_OBD_DMCM_Req_Data 0;
BA_ "GenSigSendType" SG_ 2022 ISO_OBD_DMCM_Req_Data 3;
BA_ "GenSigAutoGenSnd" SG_ 2022 ISO_OBD_DMCM_Req_Data 1;
BA_ "GenSigAutoGenDsp" SG_ 2022 ISO_OBD_DMCM_Req_Data 1;
BA_ "GenSigSwitchedByIgnition" SG_ 2030 ISO_OBD_DMCM_Resp_Data 0;
BA_ "GenSigSendType" SG_ 2030 ISO_OBD_DMCM_Resp_Data 3;
BA_ "GenSigAutoGenSnd" SG_ 2030 ISO_OBD_DMCM_Resp_Data 1;
BA_ "GenSigAutoGenDsp" SG_ 2030 ISO_OBD_DMCM_Resp_Data 1;
BA_ "GenSigSwitchedByIgnition" SG_ 2019 ISO_OBD_reserv1_Req_Data 0;
BA_ "GenSigSendType" SG_ 2019 ISO_OBD_reserv1_Req_Data 3;
BA_ "GenSigAutoGenSnd" SG_ 2019 ISO_OBD_reserv1_Req_Data 1;
BA_ "GenSigAutoGenDsp" SG_ 2019 ISO_OBD_reserv1_Req_Data 1;
BA_ "GenSigSwitchedByIgnition" SG_ 2027 ISO_OBD_reserv1_Resp_Data 0;
BA_ "GenSigSendType" SG_ 2027 ISO_OBD_reserv1_Resp_Data 3;
BA_ "GenSigAutoGenSnd" SG_ 2027 ISO_OBD_reserv1_Resp_Data 1;
BA_ "GenSigAutoGenDsp" SG_ 2027 ISO_OBD_reserv1_Resp_Data 1;
BA_ "GenSigSwitchedByIgnition" SG_ 2020 ISO_OBD_reserv2_Req_Data 0;
BA_ "GenSigSendType" SG_ 2020 ISO_OBD_reserv2_Req_Data 3;
BA_ "GenSigAutoGenSnd" SG_ 2020 ISO_OBD_reserv2_Req_Data 1;
BA_ "GenSigAutoGenDsp" SG_ 2020 ISO_OBD_reserv2_Req_Data 1;
BA_ "GenSigSwitchedByIgnition" SG_ 2028 ISO_OBD_reserv2_Resp_Data 0;
BA_ "GenSigSendType" SG_ 2028 ISO_OBD_reserv2_Resp_Data 3;
BA_ "GenSigAutoGenSnd" SG_ 2028 ISO_OBD_reserv2_Resp_Data 1;
BA_ "GenSigAutoGenDsp" SG_ 2028 ISO_OBD_reserv2_Resp_Data 1;
BA_ "GenSigSwitchedByIgnition" SG_ 2023 ISO_OBD_reserv5_Req_Data 0;
BA_ "GenSigSendType" SG_ 2023 ISO_OBD_reserv5_Req_Data 3;
BA_ "GenSigAutoGenSnd" SG_ 2023 ISO_OBD_reserv5_Req_Data 1;
BA_ "GenSigAutoGenDsp" SG_ 2023 ISO_OBD_reserv5_Req_Data 1;
BA_ "GenSigSwitchedByIgnition" SG_ 2031 ISO_OBD_reserv5_Resp_Data 0;
BA_ "GenSigSendType" SG_ 2031 ISO_OBD_reserv5_Resp_Data 3;
BA_ "GenSigAutoGenSnd" SG_ 2031 ISO_OBD_reserv5_Resp_Data 1;
BA_ "GenSigAutoGenDsp" SG_ 2031 ISO_OBD_reserv5_Resp_Data 1;
BA_ "GenSigFuncType" SG_ 1386 ACA_Checksum 4;
BA_ "GenSigSendType" SG_ 1386 ACA_Checksum 0;
BA_ "GenSigAutoGenSnd" SG_ 1386 ACA_Checksum 1;
BA_ "GenSigAutoGenDsp" SG_ 1386 ACA_Checksum 1;
BA_ "GenSigSendType" SG_ 1386 ACA_StaACC 0;
BA_ "GenSigAutoGenSnd" SG_ 1386 ACA_StaACC 1;
BA_ "GenSigAutoGenDsp" SG_ 1386 ACA_StaACC 1;
BA_ "GenSigSendType" SG_ 1386 ACA_ID_StaACC 0;
BA_ "GenSigAutoGenSnd" SG_ 1386 ACA_ID_StaACC 1;
BA_ "GenSigAutoGenDsp" SG_ 1386 ACA_ID_StaACC 1;
BA_ "GenSigSendType" SG_ 1386 ACA_Fahrerhinw 0;
BA_ "GenSigAutoGenSnd" SG_ 1386 ACA_Fahrerhinw 1;
BA_ "GenSigAutoGenDsp" SG_ 1386 ACA_Fahrerhinw 1;
BA_ "GenSigSendType" SG_ 1386 ACA_AnzDisplay 0;
BA_ "GenSigAutoGenSnd" SG_ 1386 ACA_AnzDisplay 1;
BA_ "GenSigAutoGenDsp" SG_ 1386 ACA_AnzDisplay 1;
BA_ "GenSigStartValue" SG_ 1386 ACA_Zeitluecke 2;
BA_ "GenSigSendType" SG_ 1386 ACA_Zeitluecke 0;
BA_ "GenSigAutoGenSnd" SG_ 1386 ACA_Zeitluecke 1;
BA_ "GenSigAutoGenDsp" SG_ 1386 ACA_Zeitluecke 1;
BA_ "GenSigSendType" SG_ 1386 ACA_V_Wunsch 0;
BA_ "GenSigAutoGenSnd" SG_ 1386 ACA_V_Wunsch 1;
BA_ "GenSigAutoGenDsp" SG_ 1386 ACA_V_Wunsch 1;
BA_ "GenSigSendType" SG_ 1386 ACA_kmh_mph 0;
BA_ "GenSigAutoGenSnd" SG_ 1386 ACA_kmh_mph 1;
BA_ "GenSigAutoGenDsp" SG_ 1386 ACA_kmh_mph 1;
BA_ "GenSigSendType" SG_ 1386 ACA_Akustik1 0;
BA_ "GenSigAutoGenSnd" SG_ 1386 ACA_Akustik1 1;
BA_ "GenSigAutoGenDsp" SG_ 1386 ACA_Akustik1 1;
BA_ "GenSigSendType" SG_ 1386 ACA_Akustik2 0;
BA_ "GenSigAutoGenSnd" SG_ 1386 ACA_Akustik2 1;
BA_ "GenSigAutoGenDsp" SG_ 1386 ACA_Akustik2 1;
BA_ "GenSigStartValue" SG_ 1386 ACA_PrioDisp 3;
BA_ "GenSigSendType" SG_ 1386 ACA_PrioDisp 0;
BA_ "GenSigAutoGenSnd" SG_ 1386 ACA_PrioDisp 1;
BA_ "GenSigAutoGenDsp" SG_ 1386 ACA_PrioDisp 1;
BA_ "GenSigSendType" SG_ 1386 ACA_gemZeitl 0;
BA_ "GenSigAutoGenSnd" SG_ 1386 ACA_gemZeitl 1;
BA_ "GenSigAutoGenDsp" SG_ 1386 ACA_gemZeitl 1;
BA_ "GenSigSendType" SG_ 1386 ACA_ACC_Verz 0;
BA_ "GenSigAutoGenSnd" SG_ 1386 ACA_ACC_Verz 1;
BA_ "GenSigAutoGenDsp" SG_ 1386 ACA_ACC_Verz 1;
BA_ "GenSigSendType" SG_ 1386 ACA_StaGRA 0;
BA_ "GenSigAutoGenSnd" SG_ 1386 ACA_StaGRA 1;
BA_ "GenSigAutoGenDsp" SG_ 1386 ACA_StaGRA 1;
BA_ "GenSigSendType" SG_ 1386 ACA_ID_StaGRA 0;
BA_ "GenSigAutoGenSnd" SG_ 1386 ACA_ID_StaGRA 1;
BA_ "GenSigAutoGenDsp" SG_ 1386 ACA_ID_StaGRA 1;
BA_ "GenSigSendType" SG_ 1386 ACA_Codierung 0;
BA_ "GenSigAutoGenSnd" SG_ 1386 ACA_Codierung 1;
BA_ "GenSigAutoGenDsp" SG_ 1386 ACA_Codierung 1;
BA_ "GenSigSendType" SG_ 1386 ACA_Tachokranz 0;
BA_ "GenSigAutoGenSnd" SG_ 1386 ACA_Tachokranz 1;
BA_ "GenSigAutoGenDsp" SG_ 1386 ACA_Tachokranz 1;
BA_ "GenSigSendType" SG_ 1386 ACA_Aend_Zeitluecke 0;
BA_ "GenSigAutoGenSnd" SG_ 1386 ACA_Aend_Zeitluecke 1;
BA_ "GenSigAutoGenDsp" SG_ 1386 ACA_Aend_Zeitluecke 1;
BA_ "GenSigFuncType" SG_ 1386 ACA_Zaehler 1;
BA_ "GenSigSendType" SG_ 1386 ACA_Zaehler 0;
BA_ "GenSigAutoGenSnd" SG_ 1386 ACA_Zaehler 1;
BA_ "GenSigAutoGenDsp" SG_ 1386 ACA_Zaehler 1;
BA_ "GenSigFuncType" SG_ 872 ACS_Checksum 4;
BA_ "GenSigSendType" SG_ 872 ACS_Checksum 0;
BA_ "GenSigAutoGenSnd" SG_ 872 ACS_Checksum 1;
BA_ "GenSigAutoGenDsp" SG_ 872 ACS_Checksum 1;
BA_ "GenSigFuncType" SG_ 872 ACS_Zaehler 1;
BA_ "GenSigSendType" SG_ 872 ACS_Zaehler 0;
BA_ "GenSigAutoGenSnd" SG_ 872 ACS_Zaehler 1;
BA_ "GenSigAutoGenDsp" SG_ 872 ACS_Zaehler 1;
BA_ "GenSigSendType" SG_ 872 ACS_Sta_ADR 0;
BA_ "GenSigAutoGenSnd" SG_ 872 ACS_Sta_ADR 1;
BA_ "GenSigAutoGenDsp" SG_ 872 ACS_Sta_ADR 1;
BA_ "GenSigSendType" SG_ 872 ACS_ADR_Schub 0;
BA_ "GenSigAutoGenSnd" SG_ 872 ACS_ADR_Schub 1;
BA_ "GenSigAutoGenDsp" SG_ 872 ACS_ADR_Schub 1;
BA_ "GenSigSendType" SG_ 872 ACS_Schubabsch 0;
BA_ "GenSigAutoGenSnd" SG_ 872 ACS_Schubabsch 1;
BA_ "GenSigAutoGenDsp" SG_ 872 ACS_Schubabsch 1;
BA_ "GenSigSendType" SG_ 872 ACS_StSt_Info 0;
BA_ "GenSigAutoGenSnd" SG_ 872 ACS_StSt_Info 1;
BA_ "GenSigAutoGenDsp" SG_ 872 ACS_StSt_Info 1;
BA_ "GenSigSendType" SG_ 872 ACS_MomEingriff 0;
BA_ "GenSigAutoGenSnd" SG_ 872 ACS_MomEingriff 1;
BA_ "GenSigAutoGenDsp" SG_ 872 ACS_MomEingriff 1;
BA_ "GenSigSendType" SG_ 872 ACS_Typ_ACC 0;
BA_ "GenSigAutoGenSnd" SG_ 872 ACS_Typ_ACC 1;
BA_ "GenSigAutoGenDsp" SG_ 872 ACS_Typ_ACC 1;
BA_ "GenSigSendType" SG_ 872 ACS_FreigSollB 0;
BA_ "GenSigAutoGenSnd" SG_ 872 ACS_FreigSollB 1;
BA_ "GenSigAutoGenDsp" SG_ 872 ACS_FreigSollB 1;
BA_ "Fehlerwert" SG_ 872 ACS_Sollbeschl 2047;
BA_ "GenSigStartValue" SG_ 872 ACS_Sollbeschl 2046;
BA_ "GenSigSendType" SG_ 872 ACS_Sollbeschl 0;
BA_ "GenSigAutoGenSnd" SG_ 872 ACS_Sollbeschl 1;
BA_ "GenSigAutoGenDsp" SG_ 872 ACS_Sollbeschl 1;
BA_ "GenSigSendType" SG_ 872 ACS_Anhaltewunsch 0;
BA_ "GenSigAutoGenSnd" SG_ 872 ACS_Anhaltewunsch 1;
BA_ "GenSigAutoGenDsp" SG_ 872 ACS_Anhaltewunsch 1;
BA_ "GenSigSendType" SG_ 872 ACS_Fehler 0;
BA_ "GenSigAutoGenSnd" SG_ 872 ACS_Fehler 1;
BA_ "GenSigAutoGenDsp" SG_ 872 ACS_Fehler 1;
BA_ "Fehlerwert" SG_ 872 ACS_zul_Regelabw 255;
BA_ "GenSigStartValue" SG_ 872 ACS_zul_Regelabw 254;
BA_ "GenSigSendType" SG_ 872 ACS_zul_Regelabw 0;
BA_ "GenSigAutoGenSnd" SG_ 872 ACS_zul_Regelabw 1;
BA_ "GenSigAutoGenDsp" SG_ 872 ACS_zul_Regelabw 1;
BA_ "Fehlerwert" SG_ 872 ACS_max_AendGrad 255;
BA_ "GenSigStartValue" SG_ 872 ACS_max_AendGrad 254;
BA_ "GenSigSendType" SG_ 872 ACS_max_AendGrad 0;
BA_ "GenSigAutoGenSnd" SG_ 872 ACS_max_AendGrad 1;
BA_ "GenSigAutoGenDsp" SG_ 872 ACS_max_AendGrad 1;
BA_ "GenSigSendType" SG_ 1688 AFZ_ParaSW_L 0;
BA_ "GenSigAutoGenSnd" SG_ 1688 AFZ_ParaSW_L 1;
BA_ "GenSigAutoGenDsp" SG_ 1688 AFZ_ParaSW_L 1;
BA_ "GenSigSendType" SG_ 1688 AFZ_ParaSW_R 0;
BA_ "GenSigAutoGenSnd" SG_ 1688 AFZ_ParaSW_R 1;
BA_ "GenSigAutoGenDsp" SG_ 1688 AFZ_ParaSW_R 1;
BA_ "GenSigSendType" SG_ 1688 AFZ_Modus 0;
BA_ "GenSigAutoGenSnd" SG_ 1688 AFZ_Modus 1;
BA_ "GenSigAutoGenDsp" SG_ 1688 AFZ_Modus 1;
BA_ "GenSigSendType" SG_ 1688 AFZ_Init 0;
BA_ "GenSigAutoGenSnd" SG_ 1688 AFZ_Init 1;
BA_ "GenSigAutoGenDsp" SG_ 1688 AFZ_Init 1;
BA_ "GenSigSendType" SG_ 1688 AFZ_SafePos 0;
BA_ "GenSigAutoGenSnd" SG_ 1688 AFZ_SafePos 1;
BA_ "GenSigAutoGenDsp" SG_ 1688 AFZ_SafePos 1;
BA_ "Fehlerwert" SG_ 1688 AFZ_IstPosMot_L 255;
BA_ "GenSigStartValue" SG_ 1688 AFZ_IstPosMot_L 254;
BA_ "GenSigSendType" SG_ 1688 AFZ_IstPosMot_L 0;
BA_ "GenSigAutoGenSnd" SG_ 1688 AFZ_IstPosMot_L 1;
BA_ "GenSigAutoGenDsp" SG_ 1688 AFZ_IstPosMot_L 1;
BA_ "Fehlerwert" SG_ 1688 AFZ_IstPosMot_R 255;
BA_ "GenSigStartValue" SG_ 1688 AFZ_IstPosMot_R 254;
BA_ "GenSigSendType" SG_ 1688 AFZ_IstPosMot_R 0;
BA_ "GenSigAutoGenSnd" SG_ 1688 AFZ_IstPosMot_R 1;
BA_ "GenSigAutoGenDsp" SG_ 1688 AFZ_IstPosMot_R 1;
BA_ "Fehlerwert" SG_ 1688 AFZ_Soll_EVG 255;
BA_ "GenSigStartValue" SG_ 1688 AFZ_Soll_EVG 254;
BA_ "GenSigSendType" SG_ 1688 AFZ_Soll_EVG 0;
BA_ "GenSigAutoGenSnd" SG_ 1688 AFZ_Soll_EVG 1;
BA_ "GenSigAutoGenDsp" SG_ 1688 AFZ_Soll_EVG 1;
BA_ "Fehlerwert" SG_ 1688 AFZ_IstDimAbLi 255;
BA_ "GenSigStartValue" SG_ 1688 AFZ_IstDimAbLi 254;
BA_ "GenSigSendType" SG_ 1688 AFZ_IstDimAbLi 0;
BA_ "GenSigAutoGenSnd" SG_ 1688 AFZ_IstDimAbLi 1;
BA_ "GenSigAutoGenDsp" SG_ 1688 AFZ_IstDimAbLi 1;
BA_ "Fehlerwert" SG_ 1688 AFZ_IstDimAbRe 255;
BA_ "GenSigStartValue" SG_ 1688 AFZ_IstDimAbRe 254;
BA_ "GenSigSendType" SG_ 1688 AFZ_IstDimAbRe 0;
BA_ "GenSigAutoGenSnd" SG_ 1688 AFZ_IstDimAbRe 1;
BA_ "GenSigAutoGenDsp" SG_ 1688 AFZ_IstDimAbRe 1;
BA_ "Fehlerwert" SG_ 1688 AFZ_StaLamp_L 1;
BA_ "GenSigSendType" SG_ 1688 AFZ_StaLamp_L 0;
BA_ "GenSigAutoGenSnd" SG_ 1688 AFZ_StaLamp_L 1;
BA_ "GenSigAutoGenDsp" SG_ 1688 AFZ_StaLamp_L 1;
BA_ "Fehlerwert" SG_ 1688 AFZ_StaLamp_R 1;
BA_ "GenSigSendType" SG_ 1688 AFZ_StaLamp_R 0;
BA_ "GenSigAutoGenSnd" SG_ 1688 AFZ_StaLamp_R 1;
BA_ "GenSigAutoGenDsp" SG_ 1688 AFZ_StaLamp_R 1;
BA_ "GenSigSendType" SG_ 80 AB1_Front 3;
BA_ "GenSigAutoGenSnd" SG_ 80 AB1_Front 1;
BA_ "GenSigAutoGenDsp" SG_ 80 AB1_Front 1;
BA_ "GenSigSendType" SG_ 80 AB1_Heck 3;
BA_ "GenSigAutoGenSnd" SG_ 80 AB1_Heck 1;
BA_ "GenSigAutoGenDsp" SG_ 80 AB1_Heck 1;
BA_ "GenSigSendType" SG_ 80 AB1_Fa_Seite 3;
BA_ "GenSigAutoGenSnd" SG_ 80 AB1_Fa_Seite 1;
BA_ "GenSigAutoGenDsp" SG_ 80 AB1_Fa_Seite 1;
BA_ "GenSigSendType" SG_ 80 AB1_Bf_Seite 3;
BA_ "GenSigAutoGenSnd" SG_ 80 AB1_Bf_Seite 1;
BA_ "GenSigAutoGenDsp" SG_ 80 AB1_Bf_Seite 1;
BA_ "GenSigSendType" SG_ 80 AB1_Rollover 3;
BA_ "GenSigAutoGenSnd" SG_ 80 AB1_Rollover 1;
BA_ "GenSigAutoGenDsp" SG_ 80 AB1_Rollover 1;
BA_ "GenSigSendType" SG_ 80 AB1_Intens 8;
BA_ "GenSigAutoGenSnd" SG_ 80 AB1_Intens 1;
BA_ "GenSigAutoGenDsp" SG_ 80 AB1_Intens 1;
BA_ "GenSigStartValue" SG_ 80 AB1_Lampe 1;
BA_ "GenSigSendType" SG_ 80 AB1_Lampe 0;
BA_ "GenSigAutoGenSnd" SG_ 80 AB1_Lampe 1;
BA_ "GenSigAutoGenDsp" SG_ 80 AB1_Lampe 1;
BA_ "GenSigSendType" SG_ 80 AB1_Status 0;
BA_ "GenSigAutoGenSnd" SG_ 80 AB1_Status 1;
BA_ "GenSigAutoGenDsp" SG_ 80 AB1_Status 1;
BA_ "GenSigStartValue" SG_ 80 AB1_Beifahrer 1;
BA_ "GenSigSendType" SG_ 80 AB1_Beifahrer 0;
BA_ "GenSigAutoGenSnd" SG_ 80 AB1_Beifahrer 1;
BA_ "GenSigAutoGenDsp" SG_ 80 AB1_Beifahrer 1;
BA_ "GenSigSendType" SG_ 80 AB1_System 0;
BA_ "GenSigAutoGenSnd" SG_ 80 AB1_System 1;
BA_ "GenSigAutoGenDsp" SG_ 80 AB1_System 1;
BA_ "Fehlerwert" SG_ 80 AB1_Gurt_Fa 1;
BA_ "GenSigSendType" SG_ 80 AB1_Gurt_Fa 0;
BA_ "GenSigAutoGenSnd" SG_ 80 AB1_Gurt_Fa 1;
BA_ "GenSigAutoGenDsp" SG_ 80 AB1_Gurt_Fa 1;
BA_ "Fehlerwert" SG_ 80 AB1_Gurt_Bf 1;
BA_ "GenSigSendType" SG_ 80 AB1_Gurt_Bf 0;
BA_ "GenSigAutoGenSnd" SG_ 80 AB1_Gurt_Bf 1;
BA_ "GenSigAutoGenDsp" SG_ 80 AB1_Gurt_Bf 1;
BA_ "GenSigSendType" SG_ 80 AB1_Diagnose 0;
BA_ "GenSigAutoGenSnd" SG_ 80 AB1_Diagnose 1;
BA_ "GenSigAutoGenDsp" SG_ 80 AB1_Diagnose 1;
BA_ "GenSigSendType" SG_ 80 AB1_Stellglied 0;
BA_ "GenSigAutoGenSnd" SG_ 80 AB1_Stellglied 1;
BA_ "GenSigAutoGenDsp" SG_ 80 AB1_Stellglied 1;
BA_ "GenSigSendType" SG_ 80 AB1_BF_Warnung 0;
BA_ "GenSigAutoGenSnd" SG_ 80 AB1_BF_Warnung 1;
BA_ "GenSigAutoGenDsp" SG_ 80 AB1_BF_Warnung 1;
BA_ "GenSigSendType" SG_ 80 AB1_Fehlereintr 0;
BA_ "GenSigAutoGenSnd" SG_ 80 AB1_Fehlereintr 1;
BA_ "GenSigAutoGenDsp" SG_ 80 AB1_Fehlereintr 1;
BA_ "GenSigFuncType" SG_ 80 AB1_Zaehler 1;
BA_ "GenSigSendType" SG_ 80 AB1_Zaehler 0;
BA_ "GenSigAutoGenSnd" SG_ 80 AB1_Zaehler 1;
BA_ "GenSigAutoGenDsp" SG_ 80 AB1_Zaehler 1;
BA_ "GenSigFuncType" SG_ 80 AB1_Checksumme 4;
BA_ "GenSigSendType" SG_ 80 AB1_Checksumme 0;
BA_ "GenSigAutoGenSnd" SG_ 80 AB1_Checksumme 1;
BA_ "GenSigAutoGenDsp" SG_ 80 AB1_Checksumme 1;
BA_ "GenSigFuncType" SG_ 1360 AB2_Checksum 4;
BA_ "GenSigSendType" SG_ 1360 AB2_Checksum 0;
BA_ "GenSigAutoGenSnd" SG_ 1360 AB2_Checksum 1;
BA_ "GenSigAutoGenDsp" SG_ 1360 AB2_Checksum 1;
BA_ "GenSigSendType" SG_ 1360 AB2_Beleg_HF 0;
BA_ "GenSigAutoGenSnd" SG_ 1360 AB2_Beleg_HF 1;
BA_ "GenSigAutoGenDsp" SG_ 1360 AB2_Beleg_HF 1;
BA_ "GenSigSendType" SG_ 1360 AB2_Beleg_HBF 0;
BA_ "GenSigAutoGenSnd" SG_ 1360 AB2_Beleg_HBF 1;
BA_ "GenSigAutoGenDsp" SG_ 1360 AB2_Beleg_HBF 1;
BA_ "GenSigSendType" SG_ 1360 AB2_Beleg_HM 0;
BA_ "GenSigAutoGenSnd" SG_ 1360 AB2_Beleg_HM 1;
BA_ "GenSigAutoGenDsp" SG_ 1360 AB2_Beleg_HM 1;
BA_ "Fehlerwert" SG_ 1360 AB2_Beleg_BF 1;
BA_ "GenSigSendType" SG_ 1360 AB2_Beleg_BF 0;
BA_ "GenSigAutoGenSnd" SG_ 1360 AB2_Beleg_BF 1;
BA_ "GenSigAutoGenDsp" SG_ 1360 AB2_Beleg_BF 1;
BA_ "Fehlerwert" SG_ 1360 AB2_OOP_Fa 1;
BA_ "GenSigSendType" SG_ 1360 AB2_OOP_Fa 0;
BA_ "GenSigAutoGenSnd" SG_ 1360 AB2_OOP_Fa 1;
BA_ "GenSigAutoGenDsp" SG_ 1360 AB2_OOP_Fa 1;
BA_ "Fehlerwert" SG_ 1360 AB2_OOP_BF 1;
BA_ "GenSigSendType" SG_ 1360 AB2_OOP_BF 0;
BA_ "GenSigAutoGenSnd" SG_ 1360 AB2_OOP_BF 1;
BA_ "GenSigAutoGenDsp" SG_ 1360 AB2_OOP_BF 1;
BA_ "GenSigSendType" SG_ 1360 AB2_Sta_BF 0;
BA_ "GenSigAutoGenSnd" SG_ 1360 AB2_Sta_BF 1;
BA_ "GenSigAutoGenDsp" SG_ 1360 AB2_Sta_BF 1;
BA_ "Fehlerwert" SG_ 1360 AB2_Gurt_2FaS 1;
BA_ "GenSigSendType" SG_ 1360 AB2_Gurt_2FaS 0;
BA_ "GenSigAutoGenSnd" SG_ 1360 AB2_Gurt_2FaS 1;
BA_ "GenSigAutoGenDsp" SG_ 1360 AB2_Gurt_2FaS 1;
BA_ "Fehlerwert" SG_ 1360 AB2_Gurt_2BfS 1;
BA_ "GenSigSendType" SG_ 1360 AB2_Gurt_2BfS 0;
BA_ "GenSigAutoGenSnd" SG_ 1360 AB2_Gurt_2BfS 1;
BA_ "GenSigAutoGenDsp" SG_ 1360 AB2_Gurt_2BfS 1;
BA_ "Fehlerwert" SG_ 1360 AB2_Gurt_2Mi 1;
BA_ "GenSigSendType" SG_ 1360 AB2_Gurt_2Mi 0;
BA_ "GenSigAutoGenSnd" SG_ 1360 AB2_Gurt_2Mi 1;
BA_ "GenSigAutoGenDsp" SG_ 1360 AB2_Gurt_2Mi 1;
BA_ "Fehlerwert" SG_ 1360 AB2_Gurt_3FaS 1;
BA_ "GenSigSendType" SG_ 1360 AB2_Gurt_3FaS 0;
BA_ "GenSigAutoGenSnd" SG_ 1360 AB2_Gurt_3FaS 1;
BA_ "GenSigAutoGenDsp" SG_ 1360 AB2_Gurt_3FaS 1;
BA_ "Fehlerwert" SG_ 1360 AB2_Gurt_3BfS 1;
BA_ "GenSigSendType" SG_ 1360 AB2_Gurt_3BfS 0;
BA_ "GenSigAutoGenSnd" SG_ 1360 AB2_Gurt_3BfS 1;
BA_ "GenSigAutoGenDsp" SG_ 1360 AB2_Gurt_3BfS 1;
BA_ "Fehlerwert" SG_ 1360 AB2_Gurt_3Mi 1;
BA_ "GenSigSendType" SG_ 1360 AB2_Gurt_3Mi 0;
BA_ "GenSigAutoGenSnd" SG_ 1360 AB2_Gurt_3Mi 1;
BA_ "GenSigAutoGenDsp" SG_ 1360 AB2_Gurt_3Mi 1;
BA_ "Fehlerwert" SG_ 704 AL1_Fehler 1;
BA_ "GenSigSendType" SG_ 704 AL1_Fehler 0;
BA_ "GenSigAutoGenSnd" SG_ 704 AL1_Fehler 1;
BA_ "GenSigAutoGenDsp" SG_ 704 AL1_Fehler 1;
BA_ "GenSigSendType" SG_ 704 AL1_Uebertemp 0;
BA_ "GenSigAutoGenSnd" SG_ 704 AL1_Uebertemp 1;
BA_ "GenSigAutoGenDsp" SG_ 704 AL1_Uebertemp 1;
BA_ "GenSigSendType" SG_ 704 AL1_Sta_Kup 0;
BA_ "GenSigAutoGenSnd" SG_ 704 AL1_Sta_Kup 1;
BA_ "GenSigAutoGenDsp" SG_ 704 AL1_Sta_Kup 1;
BA_ "GenSigSendType" SG_ 704 AL1_Kup_offen 0;
BA_ "GenSigAutoGenSnd" SG_ 704 AL1_Kup_offen 1;
BA_ "GenSigAutoGenDsp" SG_ 704 AL1_Kup_offen 1;
BA_ "GenSigSendType" SG_ 704 AL1_Notlauf 0;
BA_ "GenSigAutoGenSnd" SG_ 704 AL1_Notlauf 1;
BA_ "GenSigAutoGenDsp" SG_ 704 AL1_Notlauf 1;
BA_ "GenSigSendType" SG_ 704 AL1_Warnlampe 0;
BA_ "GenSigAutoGenSnd" SG_ 704 AL1_Warnlampe 1;
BA_ "GenSigAutoGenDsp" SG_ 704 AL1_Warnlampe 1;
BA_ "GenSigSendType" SG_ 704 AL1_Limiter 0;
BA_ "GenSigAutoGenSnd" SG_ 704 AL1_Limiter 1;
BA_ "GenSigAutoGenDsp" SG_ 704 AL1_Limiter 1;
BA_ "GenSigSendType" SG_ 704 AL1_Einheit 0;
BA_ "GenSigAutoGenSnd" SG_ 704 AL1_Einheit 1;
BA_ "GenSigAutoGenDsp" SG_ 704 AL1_Einheit 1;
BA_ "Fehlerwert" SG_ 704 AL1_Ist_Nm 255;
BA_ "GenSigStartValue" SG_ 704 AL1_Ist_Nm 127;
BA_ "GenSigAutoGenSnd" SG_ 704 AL1_Ist_Nm 1;
BA_ "GenSigAutoGenDsp" SG_ 704 AL1_Ist_Nm 1;
BA_ "Fehlerwert" SG_ 704 AL1_Ist_Proz 255;
BA_ "GenSigStartValue" SG_ 704 AL1_Ist_Proz 127;
BA_ "GenSigAutoGenSnd" SG_ 704 AL1_Ist_Proz 1;
BA_ "GenSigAutoGenDsp" SG_ 704 AL1_Ist_Proz 1;
BA_ "GenSigSendType" SG_ 704 AL1_Sta_PNG 0;
BA_ "GenSigAutoGenSnd" SG_ 704 AL1_Sta_PNG 1;
BA_ "GenSigAutoGenDsp" SG_ 704 AL1_Sta_PNG 1;
BA_ "GenSigSendType" SG_ 704 AL1_Anz_blinken 0;
BA_ "GenSigAutoGenSnd" SG_ 704 AL1_Anz_blinken 1;
BA_ "GenSigAutoGenDsp" SG_ 704 AL1_Anz_blinken 1;
BA_ "GenSigSendType" SG_ 704 AL1_Sta_Laengssp 0;
BA_ "GenSigAutoGenSnd" SG_ 704 AL1_Sta_Laengssp 1;
BA_ "GenSigAutoGenDsp" SG_ 704 AL1_Sta_Laengssp 1;
BA_ "GenSigSendType" SG_ 704 AL1_Sta_Quersp 0;
BA_ "GenSigAutoGenSnd" SG_ 704 AL1_Sta_Quersp 1;
BA_ "GenSigAutoGenDsp" SG_ 704 AL1_Sta_Quersp 1;
BA_ "GenSigSendType" SG_ 704 AL1_Schalten 0;
BA_ "GenSigAutoGenSnd" SG_ 704 AL1_Schalten 1;
BA_ "GenSigAutoGenDsp" SG_ 704 AL1_Schalten 1;
BA_ "GenSigSendType" SG_ 704 AL1_Vorwarnung 0;
BA_ "GenSigAutoGenSnd" SG_ 704 AL1_Vorwarnung 1;
BA_ "GenSigAutoGenDsp" SG_ 704 AL1_Vorwarnung 1;
BA_ "GenSigSendType" SG_ 704 AL1_Stellung_Getr 0;
BA_ "GenSigAutoGenSnd" SG_ 704 AL1_Stellung_Getr 1;
BA_ "GenSigAutoGenDsp" SG_ 704 AL1_Stellung_Getr 1;
BA_ "GenSigSendType" SG_ 704 AL1_AnfVerteiler 0;
BA_ "GenSigAutoGenSnd" SG_ 704 AL1_AnfVerteiler 1;
BA_ "GenSigAutoGenDsp" SG_ 704 AL1_AnfVerteiler 1;
BA_ "GenSigSendType" SG_ 704 AL1_Sta_VA 0;
BA_ "GenSigAutoGenSnd" SG_ 704 AL1_Sta_VA 1;
BA_ "GenSigAutoGenDsp" SG_ 704 AL1_Sta_VA 1;
BA_ "GenSigSendType" SG_ 704 AL1_KupSteifig_F 0;
BA_ "GenSigAutoGenSnd" SG_ 704 AL1_KupSteifig_F 1;
BA_ "GenSigAutoGenDsp" SG_ 704 AL1_KupSteifig_F 1;
BA_ "GenSigSendType" SG_ 704 AL1_Fehlereintr 0;
BA_ "GenSigAutoGenSnd" SG_ 704 AL1_Fehlereintr 1;
BA_ "GenSigAutoGenDsp" SG_ 704 AL1_Fehlereintr 1;
BA_ "Fehlerwert" SG_ 704 AL1_KupplTemp 255;
BA_ "GenSigStartValue" SG_ 704 AL1_KupplTemp 254;
BA_ "GenSigSendType" SG_ 704 AL1_KupplTemp 0;
BA_ "GenSigAutoGenSnd" SG_ 704 AL1_KupplTemp 1;
BA_ "GenSigAutoGenDsp" SG_ 704 AL1_KupplTemp 1;
BA_ "GenSigSendType" SG_ 704 AL1_FaWu_Laengs 0;
BA_ "GenSigAutoGenSnd" SG_ 704 AL1_FaWu_Laengs 1;
BA_ "GenSigAutoGenDsp" SG_ 704 AL1_FaWu_Laengs 1;
BA_ "GenSigSendType" SG_ 704 AL1_FaWu_HA 0;
BA_ "GenSigAutoGenSnd" SG_ 704 AL1_FaWu_HA 1;
BA_ "GenSigAutoGenDsp" SG_ 704 AL1_FaWu_HA 1;
BA_ "GenSigSendType" SG_ 704 AL1_FaWu_VA 0;
BA_ "GenSigAutoGenSnd" SG_ 704 AL1_FaWu_VA 1;
BA_ "GenSigAutoGenDsp" SG_ 704 AL1_FaWu_VA 1;
BA_ "GenSigStartValue" SG_ 704 AL1_Quersp_Sta 3;
BA_ "GenSigSendType" SG_ 704 AL1_Quersp_Sta 0;
BA_ "GenSigAutoGenSnd" SG_ 704 AL1_Quersp_Sta 1;
BA_ "GenSigAutoGenDsp" SG_ 704 AL1_Quersp_Sta 1;
BA_ "Fehlerwert" SG_ 704 AL1_Limit_maxkmh 255;
BA_ "GenSigStartValue" SG_ 704 AL1_Limit_maxkmh 254;
BA_ "GenSigSendType" SG_ 704 AL1_Limit_maxkmh 0;
BA_ "GenSigAutoGenSnd" SG_ 704 AL1_Limit_maxkmh 1;
BA_ "GenSigAutoGenDsp" SG_ 704 AL1_Limit_maxkmh 1;
BA_ "GenSigStartValue" SG_ 704 AL1_Diff_Verbau 1;
BA_ "GenSigSendType" SG_ 704 AL1_Diff_Verbau 0;
BA_ "GenSigAutoGenSnd" SG_ 704 AL1_Diff_Verbau 1;
BA_ "GenSigAutoGenDsp" SG_ 704 AL1_Diff_Verbau 1;
BA_ "GenSigStartValue" SG_ 704 AL1_Diff_Lampe 1;
BA_ "GenSigSendType" SG_ 704 AL1_Diff_Lampe 0;
BA_ "GenSigAutoGenSnd" SG_ 704 AL1_Diff_Lampe 1;
BA_ "GenSigAutoGenDsp" SG_ 704 AL1_Diff_Lampe 1;
BA_ "GenSigSendType" SG_ 704 AL1_Diff_Gong 0;
BA_ "GenSigAutoGenSnd" SG_ 704 AL1_Diff_Gong 1;
BA_ "GenSigAutoGenDsp" SG_ 704 AL1_Diff_Gong 1;
BA_ "GenSigSendType" SG_ 704 AL1_Warnton 0;
BA_ "GenSigAutoGenSnd" SG_ 704 AL1_Warnton 1;
BA_ "GenSigAutoGenDsp" SG_ 704 AL1_Warnton 1;
BA_ "GenSigFuncType" SG_ 704 AL1_Zaehler 1;
BA_ "GenSigSendType" SG_ 704 AL1_Zaehler 0;
BA_ "GenSigAutoGenSnd" SG_ 704 AL1_Zaehler 1;
BA_ "GenSigAutoGenDsp" SG_ 704 AL1_Zaehler 1;
BA_ "GenSigFuncType" SG_ 870 AWV_Checksumme 4;
BA_ "GenSigSendType" SG_ 870 AWV_Checksumme 0;
BA_ "GenSigAutoGenSnd" SG_ 870 AWV_Checksumme 1;
BA_ "GenSigAutoGenDsp" SG_ 870 AWV_Checksumme 1;
BA_ "GenSigFuncType" SG_ 870 AWV_Zaehler 1;
BA_ "GenSigSendType" SG_ 870 AWV_Zaehler 0;
BA_ "GenSigAutoGenSnd" SG_ 870 AWV_Zaehler 1;
BA_ "GenSigAutoGenDsp" SG_ 870 AWV_Zaehler 1;
BA_ "GenSigSendType" SG_ 870 AWV_Text 0;
BA_ "GenSigAutoGenSnd" SG_ 870 AWV_Text 1;
BA_ "GenSigAutoGenDsp" SG_ 870 AWV_Text 1;
BA_ "GenSigSendType" SG_ 870 AWV_1_Freigabe 0;
BA_ "GenSigAutoGenSnd" SG_ 870 AWV_1_Freigabe 1;
BA_ "GenSigAutoGenDsp" SG_ 870 AWV_1_Freigabe 1;
BA_ "GenSigSendType" SG_ 870 AWV_1_Prefill 0;
BA_ "GenSigAutoGenSnd" SG_ 870 AWV_1_Prefill 1;
BA_ "GenSigAutoGenDsp" SG_ 870 AWV_1_Prefill 1;
BA_ "GenSigSendType" SG_ 870 AWV_1_Parameter 0;
BA_ "GenSigAutoGenSnd" SG_ 870 AWV_1_Parameter 1;
BA_ "GenSigAutoGenDsp" SG_ 870 AWV_1_Parameter 1;
BA_ "GenSigSendType" SG_ 870 AWV_Halten 0;
BA_ "GenSigSendType" SG_ 870 ANB_Teilbremsung_Freigabe 5;
BA_ "GenSigAutoGenSnd" SG_ 870 ANB_Teilbremsung_Freigabe 1;
BA_ "GenSigAutoGenDsp" SG_ 870 ANB_Teilbremsung_Freigabe 1;
BA_ "GenSigSendType" SG_ 870 AWV_2_Status 0;
BA_ "GenSigAutoGenSnd" SG_ 870 AWV_2_Status 1;
BA_ "GenSigAutoGenDsp" SG_ 870 AWV_2_Status 1;
BA_ "GenSigSendType" SG_ 870 AWV_2_Fehler 0;
BA_ "GenSigAutoGenSnd" SG_ 870 AWV_2_Fehler 1;
BA_ "GenSigAutoGenDsp" SG_ 870 AWV_2_Fehler 1;
BA_ "GenSigSendType" SG_ 870 AWV_2_SU_Warnzeit 0;
BA_ "GenSigAutoGenSnd" SG_ 870 AWV_2_SU_Warnzeit 1;
BA_ "GenSigAutoGenDsp" SG_ 870 AWV_2_SU_Warnzeit 1;
BA_ "GenSigStartValue" SG_ 870 AWV_2_SU_Bremsruck 1;
BA_ "GenSigSendType" SG_ 870 AWV_2_SU_Bremsruck 0;
BA_ "GenSigAutoGenSnd" SG_ 870 AWV_2_SU_Bremsruck 1;
BA_ "GenSigAutoGenDsp" SG_ 870 AWV_2_SU_Bremsruck 1;
BA_ "GenSigStartValue" SG_ 870 AWV_2_SU_Gong 1;
BA_ "GenSigSendType" SG_ 870 AWV_2_SU_Gong 0;
BA_ "GenSigAutoGenSnd" SG_ 870 AWV_2_SU_Gong 1;
BA_ "GenSigAutoGenDsp" SG_ 870 AWV_2_SU_Gong 1;
BA_ "GenSigStartValue" SG_ 870 AWV_2_SU_Lampe 1;
BA_ "GenSigSendType" SG_ 870 AWV_2_SU_Lampe 0;
BA_ "GenSigAutoGenSnd" SG_ 870 AWV_2_SU_Lampe 1;
BA_ "GenSigAutoGenDsp" SG_ 870 AWV_2_SU_Lampe 1;
BA_ "GenSigSendType" SG_ 870 AWV_2_Umfeldwarn 0;
BA_ "GenSigAutoGenSnd" SG_ 870 AWV_2_Umfeldwarn 1;
BA_ "GenSigAutoGenDsp" SG_ 870 AWV_2_Umfeldwarn 1;
BA_ "GenSigSendType" SG_ 870 AWV_2_Freigabe 0;
BA_ "GenSigAutoGenSnd" SG_ 870 AWV_2_Freigabe 1;
BA_ "GenSigAutoGenDsp" SG_ 870 AWV_2_Freigabe 1;
BA_ "GenSigSendType" SG_ 870 AWV_2_Ruckprofil 0;
BA_ "GenSigAutoGenSnd" SG_ 870 AWV_2_Ruckprofil 1;
BA_ "GenSigAutoGenDsp" SG_ 870 AWV_2_Ruckprofil 1;
BA_ "GenSigSendType" SG_ 870 AWV_2_Warnton 0;
BA_ "GenSigAutoGenSnd" SG_ 870 AWV_2_Warnton 1;
BA_ "GenSigAutoGenDsp" SG_ 870 AWV_2_Warnton 1;
BA_ "GenSigSendType" SG_ 870 AWV_2_Warnsymbol 0;
BA_ "GenSigAutoGenSnd" SG_ 870 AWV_2_Warnsymbol 1;
BA_ "GenSigAutoGenDsp" SG_ 870 AWV_2_Warnsymbol 1;
BA_ "GenSigSendType" SG_ 870 AWV_Infoton 0;
BA_ "GenSigAutoGenSnd" SG_ 870 AWV_Infoton 1;
BA_ "GenSigAutoGenDsp" SG_ 870 AWV_Infoton 1;
BA_ "GenSigSendType" SG_ 870 AWV_2_Gurtstraffer 0;
BA_ "GenSigAutoGenSnd" SG_ 870 AWV_2_Gurtstraffer 1;
BA_ "GenSigAutoGenDsp" SG_ 870 AWV_2_Gurtstraffer 1;
BA_ "GenSigSendType" SG_ 870 ANB_Zielbremsung_Freigabe 0;
BA_ "GenSigAutoGenSnd" SG_ 870 ANB_Zielbremsung_Freigabe 1;
BA_ "GenSigAutoGenDsp" SG_ 870 ANB_Zielbremsung_Freigabe 1;
BA_ "GenSigSendType" SG_ 870 ANB_CM_Anforderung 0;
BA_ "GenSigAutoGenSnd" SG_ 870 ANB_CM_Anforderung 1;
BA_ "GenSigAutoGenDsp" SG_ 870 ANB_CM_Anforderung 1;
BA_ "GenSigStartValue" SG_ 870 ANB_Ziel_Teilbrems_Verz_Anf 834;
BA_ "GenSigSendType" SG_ 870 ANB_Ziel_Teilbrems_Verz_Anf 0;
BA_ "GenSigAutoGenSnd" SG_ 870 ANB_Ziel_Teilbrems_Verz_Anf 1;
BA_ "GenSigAutoGenDsp" SG_ 870 ANB_Ziel_Teilbrems_Verz_Anf 1;
BA_ "Fehlerwert" SG_ 1404 BY1_KD_Fehler 1;
BA_ "GenSigSendType" SG_ 1404 BY1_KD_Fehler 0;
BA_ "GenSigAutoGenSnd" SG_ 1404 BY1_KD_Fehler 1;
BA_ "GenSigAutoGenDsp" SG_ 1404 BY1_KD_Fehler 1;
BA_ "GenSigSendType" SG_ 416 BR1_ASR_Anf 0;
BA_ "GenSigAutoGenSnd" SG_ 416 BR1_ASR_Anf 1;
BA_ "GenSigAutoGenDsp" SG_ 416 BR1_ASR_Anf 1;
BA_ "GenSigSendType" SG_ 416 BR1_MSR_Anf 0;
BA_ "GenSigAutoGenSnd" SG_ 416 BR1_MSR_Anf 1;
BA_ "GenSigAutoGenDsp" SG_ 416 BR1_MSR_Anf 1;
BA_ "GenSigSendType" SG_ 416 BR1_ABS_Brems 0;
BA_ "GenSigAutoGenSnd" SG_ 416 BR1_ABS_Brems 1;
BA_ "GenSigAutoGenDsp" SG_ 416 BR1_ABS_Brems 1;
BA_ "GenSigSendType" SG_ 416 BR1_EDS_Eingr 0;
BA_ "GenSigAutoGenSnd" SG_ 416 BR1_EDS_Eingr 1;
BA_ "GenSigAutoGenDsp" SG_ 416 BR1_EDS_Eingr 1;
BA_ "GenSigSendType" SG_ 416 BR1_ESP_Eingr 0;
BA_ "GenSigAutoGenSnd" SG_ 416 BR1_ESP_Eingr 1;
BA_ "GenSigAutoGenDsp" SG_ 416 BR1_ESP_Eingr 1;
BA_ "GenSigSendType" SG_ 416 BR1_ASR_Eingr 0;
BA_ "GenSigAutoGenSnd" SG_ 416 BR1_ASR_Eingr 1;
BA_ "GenSigAutoGenDsp" SG_ 416 BR1_ASR_Eingr 1;
BA_ "GenSigSendType" SG_ 416 BR1_EBV_Eingr 0;
BA_ "GenSigAutoGenSnd" SG_ 416 BR1_EBV_Eingr 1;
BA_ "GenSigAutoGenDsp" SG_ 416 BR1_EBV_Eingr 1;
BA_ "GenSigStartValue" SG_ 416 BR1_Lampe_ABS 1;
BA_ "GenSigSendType" SG_ 416 BR1_Lampe_ABS 0;
BA_ "GenSigAutoGenSnd" SG_ 416 BR1_Lampe_ABS 1;
BA_ "GenSigAutoGenDsp" SG_ 416 BR1_Lampe_ABS 1;
BA_ "GenSigSendType" SG_ 416 BR1_Lampe_ASR 0;
BA_ "GenSigAutoGenSnd" SG_ 416 BR1_Lampe_ASR 1;
BA_ "GenSigAutoGenDsp" SG_ 416 BR1_Lampe_ASR 1;
BA_ "GenSigSendType" SG_ 416 BR1_Lampe_BK 0;
BA_ "GenSigAutoGenSnd" SG_ 416 BR1_Lampe_BK 1;
BA_ "GenSigAutoGenDsp" SG_ 416 BR1_Lampe_BK 1;
BA_ "GenSigSendType" SG_ 416 BR1_Lichtschalt 0;
BA_ "GenSigAutoGenSnd" SG_ 416 BR1_Lichtschalt 1;
BA_ "GenSigAutoGenDsp" SG_ 416 BR1_Lichtschalt 1;
BA_ "GenSigSendType" SG_ 416 BR1_StaDruckschw 0;
BA_ "GenSigAutoGenSnd" SG_ 416 BR1_StaDruckschw 1;
BA_ "GenSigAutoGenDsp" SG_ 416 BR1_StaDruckschw 1;
BA_ "GenSigSendType" SG_ 416 BR1_MAD 0;
BA_ "GenSigAutoGenSnd" SG_ 416 BR1_MAD 1;
BA_ "GenSigAutoGenDsp" SG_ 416 BR1_MAD 1;
BA_ "GenSigSendType" SG_ 416 BR1_Sta_MAD 0;
BA_ "GenSigAutoGenSnd" SG_ 416 BR1_Sta_MAD 1;
BA_ "GenSigAutoGenDsp" SG_ 416 BR1_Sta_MAD 1;
BA_ "GenSigSendType" SG_ 416 BR1_Diagnose 0;
BA_ "GenSigAutoGenSnd" SG_ 416 BR1_Diagnose 1;
BA_ "GenSigAutoGenDsp" SG_ 416 BR1_Diagnose 1;
BA_ "GenSigSendType" SG_ 416 BR1_BKV_aktiv 0;
BA_ "GenSigAutoGenSnd" SG_ 416 BR1_BKV_aktiv 1;
BA_ "GenSigAutoGenDsp" SG_ 416 BR1_BKV_aktiv 1;
BA_ "GenSigSwitchedByIgnition" SG_ 416 BR1_Rad_kmh 0;
BA_ "GenSigStartValue" SG_ 416 BR1_Rad_kmh 32708;
BA_ "GenSigSendType" SG_ 416 BR1_Rad_kmh 0;
BA_ "GenSigAutoGenSnd" SG_ 416 BR1_Rad_kmh 1;
BA_ "GenSigAutoGenDsp" SG_ 416 BR1_Rad_kmh 1;
BA_ "Fehlerwert" SG_ 416 BR1_ASRMo_sl 255;
BA_ "GenSigStartValue" SG_ 416 BR1_ASRMo_sl 254;
BA_ "GenSigSendType" SG_ 416 BR1_ASRMo_sl 0;
BA_ "GenSigAutoGenSnd" SG_ 416 BR1_ASRMo_sl 1;
BA_ "GenSigAutoGenDsp" SG_ 416 BR1_ASRMo_sl 1;
BA_ "Fehlerwert" SG_ 416 BR1_ASRMo_fa 255;
BA_ "GenSigStartValue" SG_ 416 BR1_ASRMo_fa 254;
BA_ "GenSigAutoGenSnd" SG_ 416 BR1_ASRMo_fa 1;
BA_ "GenSigAutoGenDsp" SG_ 416 BR1_ASRMo_fa 1;
BA_ "GenSigStartValue" SG_ 416 BR1_MSR_Mo_inv 255;
BA_ "GenSigAutoGenSnd" SG_ 416 BR1_MSR_Mo_inv 1;
BA_ "GenSigAutoGenDsp" SG_ 416 BR1_MSR_Mo_inv 1;
BA_ "Fehlerwert" SG_ 416 BR1_MSR_Mo 255;
BA_ "GenSigSendType" SG_ 416 BR1_MSR_Mo 0;
BA_ "GenSigAutoGenSnd" SG_ 416 BR1_MSR_Mo 1;
BA_ "GenSigAutoGenDsp" SG_ 416 BR1_MSR_Mo 1;
BA_ "GenSigSwitchedByIgnition" SG_ 416 BR1_Zaehler 0;
BA_ "GenSigFuncType" SG_ 416 BR1_Zaehler 1;
BA_ "GenSigSendType" SG_ 416 BR1_Zaehler 0;
BA_ "GenSigAutoGenSnd" SG_ 416 BR1_Zaehler 1;
BA_ "GenSigAutoGenDsp" SG_ 416 BR1_Zaehler 1;
BA_ "GenSigSendType" SG_ 416 BR1_ASR_ESP 0;
BA_ "GenSigAutoGenSnd" SG_ 416 BR1_ASR_ESP 1;
BA_ "GenSigAutoGenDsp" SG_ 416 BR1_ASR_ESP 1;
BA_ "GenSigSendType" SG_ 416 BR1_ESPASR_passiv 0;
BA_ "GenSigAutoGenSnd" SG_ 416 BR1_ESPASR_passiv 1;
BA_ "GenSigAutoGenDsp" SG_ 416 BR1_ESPASR_passiv 1;
BA_ "Fehlerwert" SG_ 416 BR1_Sta_ESP 1;
BA_ "GenSigSendType" SG_ 416 BR1_Sta_ESP 0;
BA_ "GenSigAutoGenSnd" SG_ 416 BR1_Sta_ESP 1;
BA_ "GenSigAutoGenDsp" SG_ 416 BR1_Sta_ESP 1;
BA_ "GenSigStartValue" SG_ 416 BR1_Ersatz_Kmh 1;
BA_ "GenSigSendType" SG_ 416 BR1_Ersatz_Kmh 0;
BA_ "GenSigAutoGenSnd" SG_ 416 BR1_Ersatz_Kmh 1;
BA_ "GenSigAutoGenDsp" SG_ 416 BR1_Ersatz_Kmh 1;
BA_ "GenSigSwitchedByIgnition" SG_ 928 B10_Checksumme 0;
BA_ "GenSigFuncType" SG_ 928 B10_Checksumme 4;
BA_ "GenSigSendType" SG_ 928 B10_Checksumme 0;
BA_ "GenSigAutoGenSnd" SG_ 928 B10_Checksumme 1;
BA_ "GenSigAutoGenDsp" SG_ 928 B10_Checksumme 1;
BA_ "GenSigSwitchedByIgnition" SG_ 928 B10_Zaehler 0;
BA_ "GenSigFuncType" SG_ 928 B10_Zaehler 1;
BA_ "GenSigSendType" SG_ 928 B10_Zaehler 0;
BA_ "GenSigAutoGenSnd" SG_ 928 B10_Zaehler 1;
BA_ "GenSigAutoGenDsp" SG_ 928 B10_Zaehler 1;
BA_ "GenSigSwitchedByIgnition" SG_ 928 B10_QB_Wegimp_VL 0;
BA_ "GenSigStartValue" SG_ 928 B10_QB_Wegimp_VL 1;
BA_ "GenSigSendType" SG_ 928 B10_QB_Wegimp_VL 0;
BA_ "GenSigAutoGenSnd" SG_ 928 B10_QB_Wegimp_VL 1;
BA_ "GenSigAutoGenDsp" SG_ 928 B10_QB_Wegimp_VL 1;
BA_ "GenSigSwitchedByIgnition" SG_ 928 B10_QB_Wegimp_VR 0;
BA_ "GenSigStartValue" SG_ 928 B10_QB_Wegimp_VR 1;
BA_ "GenSigSendType" SG_ 928 B10_QB_Wegimp_VR 0;
BA_ "GenSigAutoGenSnd" SG_ 928 B10_QB_Wegimp_VR 1;
BA_ "GenSigAutoGenDsp" SG_ 928 B10_QB_Wegimp_VR 1;
BA_ "GenSigSwitchedByIgnition" SG_ 928 B10_QB_Wegimp_HL 0;
BA_ "GenSigStartValue" SG_ 928 B10_QB_Wegimp_HL 1;
BA_ "GenSigSendType" SG_ 928 B10_QB_Wegimp_HL 0;
BA_ "GenSigAutoGenSnd" SG_ 928 B10_QB_Wegimp_HL 1;
BA_ "GenSigAutoGenDsp" SG_ 928 B10_QB_Wegimp_HL 1;
BA_ "GenSigSwitchedByIgnition" SG_ 928 B10_QB_Wegimp_HR 0;
BA_ "GenSigStartValue" SG_ 928 B10_QB_Wegimp_HR 1;
BA_ "GenSigSendType" SG_ 928 B10_QB_Wegimp_HR 0;
BA_ "GenSigAutoGenSnd" SG_ 928 B10_QB_Wegimp_HR 1;
BA_ "GenSigAutoGenDsp" SG_ 928 B10_QB_Wegimp_HR 1;
BA_ "GenSigSwitchedByIgnition" SG_ 928 B10_Wegimp_VL 0;
BA_ "GenSigStartValue" SG_ 928 B10_Wegimp_VL 1021;
BA_ "GenSigSendType" SG_ 928 B10_Wegimp_VL 0;
BA_ "GenSigAutoGenSnd" SG_ 928 B10_Wegimp_VL 1;
BA_ "GenSigAutoGenDsp" SG_ 928 B10_Wegimp_VL 1;
BA_ "GenSigSwitchedByIgnition" SG_ 928 B10_Wegimp_VR 0;
BA_ "GenSigStartValue" SG_ 928 B10_Wegimp_VR 1021;
BA_ "GenSigSendType" SG_ 928 B10_Wegimp_VR 0;
BA_ "GenSigAutoGenSnd" SG_ 928 B10_Wegimp_VR 1;
BA_ "GenSigAutoGenDsp" SG_ 928 B10_Wegimp_VR 1;
BA_ "GenSigSwitchedByIgnition" SG_ 928 B10_Wegimp_HL 0;
BA_ "GenSigStartValue" SG_ 928 B10_Wegimp_HL 1021;
BA_ "GenSigSendType" SG_ 928 B10_Wegimp_HL 0;
BA_ "GenSigAutoGenSnd" SG_ 928 B10_Wegimp_HL 1;
BA_ "GenSigAutoGenDsp" SG_ 928 B10_Wegimp_HL 1;
BA_ "GenSigSwitchedByIgnition" SG_ 928 B10_Wegimp_HR 0;
BA_ "GenSigStartValue" SG_ 928 B10_Wegimp_HR 1021;
BA_ "GenSigSendType" SG_ 928 B10_Wegimp_HR 0;
BA_ "GenSigAutoGenSnd" SG_ 928 B10_Wegimp_HR 1;
BA_ "GenSigAutoGenDsp" SG_ 928 B10_Wegimp_HR 1;
BA_ "GenSigSwitchedByIgnition" SG_ 928 B10_QB_Fahrtr_VL 0;
BA_ "GenSigStartValue" SG_ 928 B10_QB_Fahrtr_VL 1;
BA_ "GenSigSendType" SG_ 928 B10_QB_Fahrtr_VL 0;
BA_ "GenSigAutoGenSnd" SG_ 928 B10_QB_Fahrtr_VL 1;
BA_ "GenSigAutoGenDsp" SG_ 928 B10_QB_Fahrtr_VL 1;
BA_ "GenSigSwitchedByIgnition" SG_ 928 B10_QB_Fahrtr_VR 0;
BA_ "GenSigStartValue" SG_ 928 B10_QB_Fahrtr_VR 1;
BA_ "GenSigSendType" SG_ 928 B10_QB_Fahrtr_VR 0;
BA_ "GenSigAutoGenSnd" SG_ 928 B10_QB_Fahrtr_VR 1;
BA_ "GenSigAutoGenDsp" SG_ 928 B10_QB_Fahrtr_VR 1;
BA_ "GenSigSwitchedByIgnition" SG_ 928 B10_QB_Fahrtr_HL 0;
BA_ "GenSigStartValue" SG_ 928 B10_QB_Fahrtr_HL 1;
BA_ "GenSigSendType" SG_ 928 B10_QB_Fahrtr_HL 0;
BA_ "GenSigAutoGenSnd" SG_ 928 B10_QB_Fahrtr_HL 1;
BA_ "GenSigAutoGenDsp" SG_ 928 B10_QB_Fahrtr_HL 1;
BA_ "GenSigSwitchedByIgnition" SG_ 928 B10_QB_Fahrtr_HR 0;
BA_ "GenSigStartValue" SG_ 928 B10_QB_Fahrtr_HR 1;
BA_ "GenSigSendType" SG_ 928 B10_QB_Fahrtr_HR 0;
BA_ "GenSigAutoGenSnd" SG_ 928 B10_QB_Fahrtr_HR 1;
BA_ "GenSigAutoGenDsp" SG_ 928 B10_QB_Fahrtr_HR 1;
BA_ "GenSigSwitchedByIgnition" SG_ 928 B10_Fahrtr_VL 0;
BA_ "GenSigSendType" SG_ 928 B10_Fahrtr_VL 0;
BA_ "GenSigAutoGenSnd" SG_ 928 B10_Fahrtr_VL 1;
BA_ "GenSigAutoGenDsp" SG_ 928 B10_Fahrtr_VL 1;
BA_ "GenSigSwitchedByIgnition" SG_ 928 B10_Fahrtr_VR 0;
BA_ "GenSigSendType" SG_ 928 B10_Fahrtr_VR 0;
BA_ "GenSigAutoGenSnd" SG_ 928 B10_Fahrtr_VR 1;
BA_ "GenSigAutoGenDsp" SG_ 928 B10_Fahrtr_VR 1;
BA_ "GenSigSwitchedByIgnition" SG_ 928 B10_Fahrtr_HL 0;
BA_ "GenSigSendType" SG_ 928 B10_Fahrtr_HL 0;
BA_ "GenSigAutoGenSnd" SG_ 928 B10_Fahrtr_HL 1;
BA_ "GenSigAutoGenDsp" SG_ 928 B10_Fahrtr_HL 1;
BA_ "GenSigSwitchedByIgnition" SG_ 928 B10_Fahrtr_HR 0;
BA_ "GenSigSendType" SG_ 928 B10_Fahrtr_HR 0;
BA_ "GenSigAutoGenSnd" SG_ 928 B10_Fahrtr_HR 1;
BA_ "GenSigAutoGenDsp" SG_ 928 B10_Fahrtr_HR 1;
BA_REL_ "GenSigTimeoutTime" BU_SG_REL_ LEH_Hybrid SG_ 946 BEM_HYB_DC_uMinLV 1000;
BA_REL_ "GenSigTimeoutTime" BU_SG_REL_ LEH_Hybrid SG_ 946 BEM_HYB_DC_uSollLV 1000;
BA_REL_ "GenSigTimeoutTime" BU_SG_REL_ Gateway_PQ35 SG_ 945 DC_HYB_iAktLV 1000;
BA_REL_ "GenSigTimeoutTime" BU_SG_REL_ Gateway_PQ35 SG_ 945 DC_HYB_iAktReserveLV 1000;
BA_REL_ "GenSigTimeoutTime" BU_SG_REL_ Gateway_PQ35 SG_ 945 DC_HYB_uAktLV 1000;
BA_REL_ "GenSigTimeoutTime" BU_SG_REL_ Gateway_PQ35 SG_ 945 DC_HYB_LangsRegelung 1000;
BA_REL_ "GenSigTimeoutTime" BU_SG_REL_ Gateway_PQ35 SG_ 945 DC_HYB_Abregelung_Temperatur 1000;
BA_REL_ "GenSigTimeoutTime" BU_SG_REL_ Gateway_PQ35 SG_ 945 DC_HYB_Fehler_RedLeistung 1000;
BA_REL_ "GenSigTimeoutTime" BU_SG_REL_ Gateway_PQ35 SG_ 945 DC_HYB_Fehler_intern 1000;
BA_REL_ "GenSigTimeoutTime" BU_SG_REL_ Gateway_PQ35 SG_ 945 DC_HYB_Fehler_Spannung 1000;
BA_REL_ "GenSigTimeoutTime" BU_SG_REL_ Gateway_PQ35 SG_ 945 DC_HYB_Auslastungsgrad 1000;
BA_REL_ "GenSigTimeoutTime" BU_SG_REL_ Gateway_PQ35 SG_ 1386 ACA_StaACC 500;
BA_REL_ "GenSigTimeoutTime" BU_SG_REL_ Gateway_PQ35 SG_ 1386 ACA_Zeitluecke 500;
BA_REL_ "GenSigTimeoutTime" BU_SG_REL_ Gateway_PQ35 SG_ 1386 ACA_V_Wunsch 500;
BA_REL_ "GenSigTimeoutTime" BU_SG_REL_ Getriebe_AG6 SG_ 1386 ACA_V_Wunsch 500;
BA_REL_ "GenSigTimeoutTime" BU_SG_REL_ Getriebe_DQ SG_ 1386 ACA_V_Wunsch 500;
BA_REL_ "GenSigTimeoutTime" BU_SG_REL_ Getriebe_DQ SG_ 1386 ACA_V_Wunsch 500;
BA_REL_ "GenSigTimeoutTime" BU_SG_REL_ Getriebe_DQ_Hyb SG_ 1386 ACA_V_Wunsch 500;
BA_REL_ "GenSigTimeoutTime" BU_SG_REL_ Gateway_PQ35 SG_ 1386 ACA_ACC_Verz 500;
BA_REL_ "GenSigTimeoutTime" BU_SG_REL_ Gateway_PQ35 SG_ 1386 ACA_StaGRA 500;
BA_REL_ "GenSigTimeoutTime" BU_SG_REL_ Gateway_PQ35 SG_ 1386 ACA_Codierung 500;
BA_REL_ "GenSigTimeoutTime" BU_SG_REL_ Getriebe_DQ SG_ 1386 ACA_Codierung 500;
BA_REL_ "GenSigTimeoutTime" BU_SG_REL_ Daempfer SG_ 872 ACS_Checksum 500;
BA_REL_ "GenSigTimeoutTime" BU_SG_REL_ Getriebe_DQ SG_ 872 ACS_Checksum 500;
BA_REL_ "GenSigTimeoutTime" BU_SG_REL_ Motor_Diesel SG_ 872 ACS_Checksum 500;
BA_REL_ "GenSigTimeoutTime" BU_SG_REL_ Motor_Otto SG_ 872 ACS_Checksum 500;
BA_REL_ "GenSigTimeoutTime" BU_SG_REL_ Daempfer SG_ 872 ACS_Zaehler 500;
BA_REL_ "GenSigTimeoutTime" BU_SG_REL_ Getriebe_DQ SG_ 872 ACS_Zaehler 500;
BA_REL_ "GenSigTimeoutTime" BU_SG_REL_ Motor_Diesel SG_ 872 ACS_Zaehler 500;
BA_REL_ "GenSigTimeoutTime" BU_SG_REL_ Motor_Otto SG_ 872 ACS_Zaehler 500;
BA_REL_ "GenSigTimeoutTime" BU_SG_REL_ Getriebe_AG6 SG_ 872 ACS_Sta_ADR 500;
BA_REL_ "GenSigTimeoutTime" BU_SG_REL_ Getriebe_DQ SG_ 872 ACS_Sta_ADR 500;
BA_REL_ "GenSigTimeoutTime" BU_SG_REL_ Motor_Diesel SG_ 872 ACS_Sta_ADR 500;
BA_REL_ "GenSigTimeoutTime" BU_SG_REL_ Motor_Otto SG_ 872 ACS_Sta_ADR 500;
BA_REL_ "GenSigTimeoutTime" BU_SG_REL_ Getriebe_AG6 SG_ 872 ACS_ADR_Schub 500;
BA_REL_ "GenSigTimeoutTime" BU_SG_REL_ Getriebe_DQ SG_ 872 ACS_ADR_Schub 500;
BA_REL_ "GenSigTimeoutTime" BU_SG_REL_ Motor_Diesel SG_ 872 ACS_ADR_Schub 500;
BA_REL_ "GenSigTimeoutTime" BU_SG_REL_ Motor_Otto SG_ 872 ACS_ADR_Schub 500;
BA_REL_ "GenSigTimeoutTime" BU_SG_REL_ Getriebe_AG6 SG_ 872 ACS_Schubabsch 500;
BA_REL_ "GenSigTimeoutTime" BU_SG_REL_ Getriebe_DQ SG_ 872 ACS_Schubabsch 500;
BA_REL_ "GenSigTimeoutTime" BU_SG_REL_ Motor_Diesel SG_ 872 ACS_Schubabsch 500;
BA_REL_ "GenSigTimeoutTime" BU_SG_REL_ Motor_Otto SG_ 872 ACS_Schubabsch 500;
BA_REL_ "GenSigTimeoutTime" BU_SG_REL_ Motor_Diesel SG_ 872 ACS_StSt_Info 500;
BA_REL_ "GenSigTimeoutTime" BU_SG_REL_ Motor_Otto SG_ 872 ACS_StSt_Info 500;
BA_REL_ "GenSigTimeoutTime" BU_SG_REL_ Getriebe_AG6 SG_ 872 ACS_MomEingriff 500;
BA_REL_ "GenSigTimeoutTime" BU_SG_REL_ Getriebe_DQ SG_ 872 ACS_MomEingriff 500;
BA_REL_ "GenSigTimeoutTime" BU_SG_REL_ Motor_Diesel SG_ 872 ACS_MomEingriff 500;
BA_REL_ "GenSigTimeoutTime" BU_SG_REL_ Motor_Otto SG_ 872 ACS_MomEingriff 500;
BA_REL_ "GenSigTimeoutTime" BU_SG_REL_ Getriebe_AG6 SG_ 872 ACS_Typ_ACC 500;
BA_REL_ "GenSigTimeoutTime" BU_SG_REL_ Getriebe_DQ SG_ 872 ACS_Typ_ACC 500;
BA_REL_ "GenSigTimeoutTime" BU_SG_REL_ Motor_Diesel SG_ 872 ACS_Typ_ACC 500;
BA_REL_ "GenSigTimeoutTime" BU_SG_REL_ Motor_Otto SG_ 872 ACS_Typ_ACC 500;
BA_REL_ "GenSigTimeoutTime" BU_SG_REL_ Daempfer SG_ 872 ACS_FreigSollB 500;
BA_REL_ "GenSigTimeoutTime" BU_SG_REL_ Getriebe_AG6 SG_ 872 ACS_FreigSollB 500;
BA_REL_ "GenSigTimeoutTime" BU_SG_REL_ Getriebe_DQ SG_ 872 ACS_FreigSollB 500;
BA_REL_ "GenSigTimeoutTime" BU_SG_REL_ Motor_Diesel SG_ 872 ACS_FreigSollB 500;
BA_REL_ "GenSigTimeoutTime" BU_SG_REL_ Motor_Otto SG_ 872 ACS_FreigSollB 500;
BA_REL_ "GenSigTimeoutTime" BU_SG_REL_ Daempfer SG_ 872 ACS_Sollbeschl 500;
BA_REL_ "GenSigTimeoutTime" BU_SG_REL_ Getriebe_AG6 SG_ 872 ACS_Sollbeschl 500;
BA_REL_ "GenSigTimeoutTime" BU_SG_REL_ Getriebe_DQ SG_ 872 ACS_Sollbeschl 500;
BA_REL_ "GenSigTimeoutTime" BU_SG_REL_ Motor_Diesel SG_ 872 ACS_Sollbeschl 500;
BA_REL_ "GenSigTimeoutTime" BU_SG_REL_ Motor_Otto SG_ 872 ACS_Sollbeschl 500;
BA_REL_ "GenSigTimeoutTime" BU_SG_REL_ Motor_Diesel SG_ 872 ACS_Anhaltewunsch 500;
BA_REL_ "GenSigTimeoutTime" BU_SG_REL_ Motor_Otto SG_ 872 ACS_Anhaltewunsch 500;
BA_REL_ "GenSigTimeoutTime" BU_SG_REL_ Gateway_PQ35 SG_ 872 ACS_Fehler 500;
BA_REL_ "GenSigTimeoutTime" BU_SG_REL_ Motor_Diesel SG_ 872 ACS_zul_Regelabw 500;
BA_REL_ "GenSigTimeoutTime" BU_SG_REL_ Motor_Otto SG_ 872 ACS_zul_Regelabw 500;
BA_REL_ "GenSigTimeoutTime" BU_SG_REL_ Motor_Diesel SG_ 872 ACS_max_AendGrad 500;
BA_REL_ "GenSigTimeoutTime" BU_SG_REL_ Motor_Otto SG_ 872 ACS_max_AendGrad 500;
BA_REL_ "GenSigTimeoutTime" BU_SG_REL_ BMS_Hybrid SG_ 80 AB1_Front 500;
BA_REL_ "GenSigTimeoutTime" BU_SG_REL_ Bremse_TRW_EBC450M SG_ 80 AB1_Front 500;
BA_REL_ "GenSigTimeoutTime" BU_SG_REL_ Bremse_TRW_ESP SG_ 80 AB1_Front 500;
BA_REL_ "GenSigTimeoutTime" BU_SG_REL_ EPB_TRW SG_ 80 AB1_Front 500;
BA_REL_ "GenSigTimeoutTime" BU_SG_REL_ Gateway_PQ35 SG_ 80 AB1_Front 500;
BA_REL_ "GenSigTimeoutTime" BU_SG_REL_ HCA SG_ 80 AB1_Front 500;
BA_REL_ "GenSigTimeoutTime" BU_SG_REL_ LEH_Hybrid SG_ 80 AB1_Front 500;
BA_REL_ "GenSigTimeoutTime" BU_SG_REL_ BMS_Hybrid SG_ 80 AB1_Heck 500;
BA_REL_ "GenSigTimeoutTime" BU_SG_REL_ Bremse_TRW_EBC450M SG_ 80 AB1_Heck 500;
BA_REL_ "GenSigTimeoutTime" BU_SG_REL_ Bremse_TRW_ESP SG_ 80 AB1_Heck 500;
BA_REL_ "GenSigTimeoutTime" BU_SG_REL_ EPB_TRW SG_ 80 AB1_Heck 500;
BA_REL_ "GenSigTimeoutTime" BU_SG_REL_ Gateway_PQ35 SG_ 80 AB1_Heck 500;
BA_REL_ "GenSigTimeoutTime" BU_SG_REL_ HCA SG_ 80 AB1_Heck 500;
BA_REL_ "GenSigTimeoutTime" BU_SG_REL_ LEH_Hybrid SG_ 80 AB1_Heck 500;
BA_REL_ "GenSigTimeoutTime" BU_SG_REL_ BMS_Hybrid SG_ 80 AB1_Fa_Seite 500;
BA_REL_ "GenSigTimeoutTime" BU_SG_REL_ Bremse_TRW_EBC450M SG_ 80 AB1_Fa_Seite 500;
BA_REL_ "GenSigTimeoutTime" BU_SG_REL_ Bremse_TRW_ESP SG_ 80 AB1_Fa_Seite 500;
BA_REL_ "GenSigTimeoutTime" BU_SG_REL_ EPB_TRW SG_ 80 AB1_Fa_Seite 500;
BA_REL_ "GenSigTimeoutTime" BU_SG_REL_ Gateway_PQ35 SG_ 80 AB1_Fa_Seite 500;
BA_REL_ "GenSigTimeoutTime" BU_SG_REL_ HCA SG_ 80 AB1_Fa_Seite 500;
BA_REL_ "GenSigTimeoutTime" BU_SG_REL_ LEH_Hybrid SG_ 80 AB1_Fa_Seite 500;
BA_REL_ "GenSigTimeoutTime" BU_SG_REL_ BMS_Hybrid SG_ 80 AB1_Bf_Seite 500;
BA_REL_ "GenSigTimeoutTime" BU_SG_REL_ Bremse_TRW_EBC450M SG_ 80 AB1_Bf_Seite 500;
BA_REL_ "GenSigTimeoutTime" BU_SG_REL_ Bremse_TRW_ESP SG_ 80 AB1_Bf_Seite 500;
BA_REL_ "GenSigTimeoutTime" BU_SG_REL_ EPB_TRW SG_ 80 AB1_Bf_Seite 500;
BA_REL_ "GenSigTimeoutTime" BU_SG_REL_ Gateway_PQ35 SG_ 80 AB1_Bf_Seite 500;
BA_REL_ "GenSigTimeoutTime" BU_SG_REL_ HCA SG_ 80 AB1_Bf_Seite 500;
BA_REL_ "GenSigTimeoutTime" BU_SG_REL_ LEH_Hybrid SG_ 80 AB1_Bf_Seite 500;
BA_REL_ "GenSigTimeoutTime" BU_SG_REL_ Bremse_MK60EC SG_ 80 AB1_Rollover 500;
BA_REL_ "GenSigTimeoutTime" BU_SG_REL_ Bremse_MK70MABS SG_ 80 AB1_Rollover 500;
BA_REL_ "GenSigTimeoutTime" BU_SG_REL_ Bremse_TRW_EBC450M SG_ 80 AB1_Rollover 500;
BA_REL_ "GenSigTimeoutTime" BU_SG_REL_ Bremse_TRW_ESP SG_ 80 AB1_Rollover 500;
BA_REL_ "GenSigTimeoutTime" BU_SG_REL_ EPB_TRW SG_ 80 AB1_Rollover 500;
BA_REL_ "GenSigTimeoutTime" BU_SG_REL_ Gateway_PQ35 SG_ 80 AB1_Rollover 500;
BA_REL_ "GenSigTimeoutTime" BU_SG_REL_ Bremse_MK60EC SG_ 80 AB1_Intens 500;
BA_REL_ "GenSigTimeoutTime" BU_SG_REL_ Bremse_MK70MABS SG_ 80 AB1_Intens 500;
BA_REL_ "GenSigTimeoutTime" BU_SG_REL_ Gateway_PQ35 SG_ 80 AB1_Intens 500;
BA_REL_ "GenSigTimeoutTime" BU_SG_REL_ LEH_Hybrid SG_ 80 AB1_Intens 500;
BA_REL_ "GenSigTimeoutTime" BU_SG_REL_ Motor_Diesel SG_ 80 AB1_Intens 500;
BA_REL_ "GenSigTimeoutTime" BU_SG_REL_ Motor_Hybrid SG_ 80 AB1_Intens 500;
BA_REL_ "GenSigTimeoutTime" BU_SG_REL_ Motor_Otto SG_ 80 AB1_Intens 500;
BA_REL_ "GenSigTimeoutTime" BU_SG_REL_ BMS_Hybrid SG_ 80 AB1_System 500;
BA_REL_ "GenSigTimeoutTime" BU_SG_REL_ HCA SG_ 80 AB1_System 500;
BA_REL_ "GenSigTimeoutTime" BU_SG_REL_ LEH_Hybrid SG_ 80 AB1_System 500;
BA_REL_ "GenSigTimeoutTime" BU_SG_REL_ Bremse_MK60EC SG_ 80 AB1_Gurt_Fa 500;
BA_REL_ "GenSigTimeoutTime" BU_SG_REL_ Bremse_TRW_EBC450M SG_ 80 AB1_Gurt_Fa 500;
BA_REL_ "GenSigTimeoutTime" BU_SG_REL_ Bremse_TRW_ESP SG_ 80 AB1_Gurt_Fa 500;
BA_REL_ "GenSigTimeoutTime" BU_SG_REL_ EPB_TRW SG_ 80 AB1_Gurt_Fa 500;
BA_REL_ "GenSigTimeoutTime" BU_SG_REL_ EPB_TRW_VW411CS SG_ 80 AB1_Gurt_Fa 500;
BA_REL_ "GenSigTimeoutTime" BU_SG_REL_ Gateway_PQ35 SG_ 80 AB1_Gurt_Fa 500;
BA_REL_ "GenSigTimeoutTime" BU_SG_REL_ Gateway_PQ35 SG_ 80 AB1_Gurt_Fa 500;
BA_REL_ "GenSigTimeoutTime" BU_SG_REL_ Motor_Diesel SG_ 80 AB1_Gurt_Fa 500;
BA_REL_ "GenSigTimeoutTime" BU_SG_REL_ Motor_Hybrid SG_ 80 AB1_Gurt_Fa 500;
BA_REL_ "GenSigTimeoutTime" BU_SG_REL_ Motor_Otto SG_ 80 AB1_Gurt_Fa 500;
BA_REL_ "GenSigTimeoutTime" BU_SG_REL_ EPB_TRW SG_ 80 AB1_Diagnose 500;
BA_REL_ "GenSigTimeoutTime" BU_SG_REL_ BMS_Hybrid SG_ 80 AB1_Stellglied 500;
BA_REL_ "GenSigTimeoutTime" BU_SG_REL_ LEH_Hybrid SG_ 80 AB1_Stellglied 500;
BA_REL_ "GenSigTimeoutTime" BU_SG_REL_ Motor_Diesel SG_ 80 AB1_Stellglied 500;
BA_REL_ "GenSigTimeoutTime" BU_SG_REL_ Motor_Otto SG_ 80 AB1_Stellglied 500;
BA_REL_ "GenSigTimeoutTime" BU_SG_REL_ Gateway_PQ35 SG_ 80 AB1_Fehlereintr 500;
BA_REL_ "GenSigTimeoutTime" BU_SG_REL_ BMS_Hybrid SG_ 80 AB1_Zaehler 500;
BA_REL_ "GenSigTimeoutTime" BU_SG_REL_ Bremse_MK60EC SG_ 80 AB1_Zaehler 500;
BA_REL_ "GenSigTimeoutTime" BU_SG_REL_ Bremse_TRW_EBC450M SG_ 80 AB1_Zaehler 500;
BA_REL_ "GenSigTimeoutTime" BU_SG_REL_ Bremse_TRW_ESP SG_ 80 AB1_Zaehler 500;
BA_REL_ "GenSigTimeoutTime" BU_SG_REL_ EPB_TRW SG_ 80 AB1_Zaehler 500;
BA_REL_ "GenSigTimeoutTime" BU_SG_REL_ EPB_TRW_VW411CS SG_ 80 AB1_Zaehler 500;
BA_REL_ "GenSigTimeoutTime" BU_SG_REL_ HCA SG_ 80 AB1_Zaehler 500;
BA_REL_ "GenSigTimeoutTime" BU_SG_REL_ LEH_Hybrid SG_ 80 AB1_Zaehler 500;
BA_REL_ "GenSigTimeoutTime" BU_SG_REL_ Motor_Diesel SG_ 80 AB1_Zaehler 500;
BA_REL_ "GenSigTimeoutTime" BU_SG_REL_ Motor_Hybrid SG_ 80 AB1_Zaehler 500;
BA_REL_ "GenSigTimeoutTime" BU_SG_REL_ Motor_Otto SG_ 80 AB1_Zaehler 500;
BA_REL_ "GenSigTimeoutTime" BU_SG_REL_ BMS_Hybrid SG_ 80 AB1_Checksumme 500;
BA_REL_ "GenSigTimeoutTime" BU_SG_REL_ Bremse_MK60EC SG_ 80 AB1_Checksumme 500;
BA_REL_ "GenSigTimeoutTime" BU_SG_REL_ Bremse_TRW_EBC450M SG_ 80 AB1_Checksumme 500;
BA_REL_ "GenSigTimeoutTime" BU_SG_REL_ Bremse_TRW_ESP SG_ 80 AB1_Checksumme 500;
BA_REL_ "GenSigTimeoutTime" BU_SG_REL_ EPB_TRW SG_ 80 AB1_Checksumme 500;
BA_REL_ "GenSigTimeoutTime" BU_SG_REL_ EPB_TRW_VW411CS SG_ 80 AB1_Checksumme 500;
BA_REL_ "GenSigTimeoutTime" BU_SG_REL_ HCA SG_ 80 AB1_Checksumme 500;
BA_REL_ "GenSigTimeoutTime" BU_SG_REL_ LEH_Hybrid SG_ 80 AB1_Checksumme 500;
BA_REL_ "GenSigTimeoutTime" BU_SG_REL_ Motor_Diesel SG_ 80 AB1_Checksumme 500;
BA_REL_ "GenSigTimeoutTime" BU_SG_REL_ Motor_Hybrid SG_ 80 AB1_Checksumme 500;
BA_REL_ "GenSigTimeoutTime" BU_SG_REL_ Motor_Otto SG_ 80 AB1_Checksumme 500;
BA_REL_ "GenSigTimeoutTime" BU_SG_REL_ Bremse_MK60EC SG_ 704 AL1_Fehler 500;
BA_REL_ "GenSigTimeoutTime" BU_SG_REL_ Bremse_TRW_EBC450M SG_ 704 AL1_Fehler 500;
BA_REL_ "GenSigTimeoutTime" BU_SG_REL_ Bremse_TRW_ESP SG_ 704 AL1_Fehler 500;
BA_REL_ "GenSigTimeoutTime" BU_SG_REL_ RKA_Plus SG_ 704 AL1_Fehler 500;
BA_REL_ "GenSigTimeoutTime" BU_SG_REL_ Bremse_TRW_EBC450M SG_ 704 AL1_Uebertemp 500;
BA_REL_ "GenSigTimeoutTime" BU_SG_REL_ Bremse_TRW_ESP SG_ 704 AL1_Uebertemp 500;
BA_REL_ "GenSigTimeoutTime" BU_SG_REL_ Bremse_MK60EC SG_ 704 AL1_Sta_Kup 500;
BA_REL_ "GenSigTimeoutTime" BU_SG_REL_ Bremse_TRW_EBC450M SG_ 704 AL1_Sta_Kup 500;
BA_REL_ "GenSigTimeoutTime" BU_SG_REL_ Bremse_TRW_ESP SG_ 704 AL1_Sta_Kup 500;
BA_REL_ "GenSigTimeoutTime" BU_SG_REL_ Bremse_TRW_EBC450M SG_ 704 AL1_Kup_offen 500;
BA_REL_ "GenSigTimeoutTime" BU_SG_REL_ Bremse_TRW_ESP SG_ 704 AL1_Kup_offen 500;
BA_REL_ "GenSigTimeoutTime" BU_SG_REL_ RKA_Plus SG_ 704 AL1_Kup_offen 500;
BA_REL_ "GenSigTimeoutTime" BU_SG_REL_ Bremse_TRW_EBC450M SG_ 704 AL1_Notlauf 500;
BA_REL_ "GenSigTimeoutTime" BU_SG_REL_ Bremse_TRW_ESP SG_ 704 AL1_Notlauf 500;
BA_REL_ "GenSigTimeoutTime" BU_SG_REL_ Bremse_TRW_EBC450M SG_ 704 AL1_Warnlampe 500;
BA_REL_ "GenSigTimeoutTime" BU_SG_REL_ Bremse_TRW_ESP SG_ 704 AL1_Warnlampe 500;
BA_REL_ "GenSigTimeoutTime" BU_SG_REL_ Bremse_MK60EC SG_ 704 AL1_Einheit 500;
BA_REL_ "GenSigTimeoutTime" BU_SG_REL_ Bremse_TRW_EBC450M SG_ 704 AL1_Einheit 500;
BA_REL_ "GenSigTimeoutTime" BU_SG_REL_ Bremse_TRW_ESP SG_ 704 AL1_Einheit 500;
BA_REL_ "GenSigTimeoutTime" BU_SG_REL_ RKA_Plus SG_ 704 AL1_Einheit 500;
BA_REL_ "GenSigTimeoutTime" BU_SG_REL_ Bremse_MK60EC SG_ 704 AL1_Ist_Nm 500;
BA_REL_ "GenSigTimeoutTime" BU_SG_REL_ Bremse_TRW_EBC450M SG_ 704 AL1_Ist_Nm 500;
BA_REL_ "GenSigTimeoutTime" BU_SG_REL_ Bremse_TRW_EBC450M SG_ 704 AL1_Ist_Nm 500;
BA_REL_ "GenSigTimeoutTime" BU_SG_REL_ Bremse_TRW_ESP SG_ 704 AL1_Ist_Nm 500;
BA_REL_ "GenSigTimeoutTime" BU_SG_REL_ Bremse_TRW_ESP SG_ 704 AL1_Ist_Nm 500;
BA_REL_ "GenSigTimeoutTime" BU_SG_REL_ RKA_Plus SG_ 704 AL1_Ist_Nm 500;
BA_REL_ "GenSigTimeoutTime" BU_SG_REL_ Bremse_MK60EC SG_ 704 AL1_Ist_Proz 500;
BA_REL_ "GenSigTimeoutTime" BU_SG_REL_ Bremse_TRW_EBC450M SG_ 704 AL1_Ist_Proz 500;
BA_REL_ "GenSigTimeoutTime" BU_SG_REL_ Bremse_TRW_ESP SG_ 704 AL1_Ist_Proz 500;
BA_REL_ "GenSigTimeoutTime" BU_SG_REL_ RKA_Plus SG_ 704 AL1_Ist_Proz 500;
BA_REL_ "GenSigTimeoutTime" BU_SG_REL_ Bremse_MK60EC SG_ 704 AL1_Sta_PNG 500;
BA_REL_ "GenSigTimeoutTime" BU_SG_REL_ Getriebe_DQ SG_ 704 AL1_Sta_PNG 500;
BA_REL_ "GenSigTimeoutTime" BU_SG_REL_ Getriebe_DQ_Hyb SG_ 704 AL1_Sta_PNG 500;
BA_REL_ "GenSigTimeoutTime" BU_SG_REL_ Getriebe_DQ SG_ 704 AL1_Vorwarnung 500;
BA_REL_ "GenSigTimeoutTime" BU_SG_REL_ Getriebe_DQ_Hyb SG_ 704 AL1_Vorwarnung 500;
BA_REL_ "GenSigTimeoutTime" BU_SG_REL_ Bremse_MK60EC SG_ 704 AL1_Stellung_Getr 500;
BA_REL_ "GenSigTimeoutTime" BU_SG_REL_ Gateway_PQ35 SG_ 704 AL1_Fehlereintr 500;
BA_REL_ "GenSigTimeoutTime" BU_SG_REL_ Bremse_TRW_EBC450M SG_ 704 AL1_Zaehler 500;
BA_REL_ "GenSigTimeoutTime" BU_SG_REL_ Bremse_TRW_ESP SG_ 704 AL1_Zaehler 500;
BA_REL_ "GenSigTimeoutTime" BU_SG_REL_ Bremse_TRW_EBC450M SG_ 870 AWV_Checksumme 500;
BA_REL_ "GenSigTimeoutTime" BU_SG_REL_ Bremse_TRW_ESP SG_ 870 AWV_Checksumme 500;
BA_REL_ "GenSigTimeoutTime" BU_SG_REL_ Daempfer SG_ 870 AWV_Checksumme 500;
BA_REL_ "GenSigTimeoutTime" BU_SG_REL_ HCA SG_ 870 AWV_Checksumme 500;
BA_REL_ "GenSigTimeoutTime" BU_SG_REL_ Bremse_TRW_EBC450M SG_ 870 AWV_Zaehler 500;
BA_REL_ "GenSigTimeoutTime" BU_SG_REL_ Bremse_TRW_ESP SG_ 870 AWV_Zaehler 500;
BA_REL_ "GenSigTimeoutTime" BU_SG_REL_ Daempfer SG_ 870 AWV_Zaehler 500;
BA_REL_ "GenSigTimeoutTime" BU_SG_REL_ HCA SG_ 870 AWV_Zaehler 500;
BA_REL_ "GenSigTimeoutTime" BU_SG_REL_ Bremse_TRW_EBC450M SG_ 870 AWV_1_Freigabe 500;
BA_REL_ "GenSigTimeoutTime" BU_SG_REL_ Bremse_TRW_ESP SG_ 870 AWV_1_Freigabe 500;
BA_REL_ "GenSigTimeoutTime" BU_SG_REL_ Bremse_TRW_EBC450M SG_ 870 AWV_1_Prefill 500;
BA_REL_ "GenSigTimeoutTime" BU_SG_REL_ Bremse_TRW_ESP SG_ 870 AWV_1_Prefill 500;
BA_REL_ "GenSigTimeoutTime" BU_SG_REL_ Bremse_TRW_EBC450M SG_ 870 AWV_1_Parameter 500;
BA_REL_ "GenSigTimeoutTime" BU_SG_REL_ Bremse_TRW_ESP SG_ 870 AWV_1_Parameter 500;
BA_REL_ "GenSigTimeoutTime" BU_SG_REL_ Bremse_TRW_EBC450M SG_ 870 AWV_Halten 500;
BA_REL_ "GenSigTimeoutTime" BU_SG_REL_ Bremse_TRW_EBC450M SG_ 870 ANB_Teilbremsung_Freigabe 500;
BA_REL_ "GenSigTimeoutTime" BU_SG_REL_ Daempfer SG_ 870 ANB_Teilbremsung_Freigabe 500;
BA_REL_ "GenSigTimeoutTime" BU_SG_REL_ Bremse_TRW_EBC450M SG_ 870 AWV_2_Freigabe 500;
BA_REL_ "GenSigTimeoutTime" BU_SG_REL_ Bremse_TRW_ESP SG_ 870 AWV_2_Freigabe 500;
BA_REL_ "GenSigTimeoutTime" BU_SG_REL_ HCA SG_ 870 AWV_2_Freigabe 500;
BA_REL_ "GenSigTimeoutTime" BU_SG_REL_ Bremse_TRW_EBC450M SG_ 870 AWV_2_Ruckprofil 500;
BA_REL_ "GenSigTimeoutTime" BU_SG_REL_ Bremse_TRW_ESP SG_ 870 AWV_2_Ruckprofil 500;
BA_REL_ "GenSigTimeoutTime" BU_SG_REL_ Bremse_TRW_EBC450M SG_ 870 ANB_Zielbremsung_Freigabe 500;
BA_REL_ "GenSigTimeoutTime" BU_SG_REL_ Daempfer SG_ 870 ANB_Zielbremsung_Freigabe 500;
BA_REL_ "GenSigTimeoutTime" BU_SG_REL_ Bremse_TRW_EBC450M SG_ 870 ANB_CM_Anforderung 500;
BA_REL_ "GenSigTimeoutTime" BU_SG_REL_ Bremse_TRW_EBC450M SG_ 870 ANB_Ziel_Teilbrems_Verz_Anf 500;
BA_REL_ "GenSigTimeoutTime" BU_SG_REL_ Daempfer SG_ 870 ANB_Ziel_Teilbrems_Verz_Anf 500;
BA_REL_ "GenSigTimeoutTime" BU_SG_REL_ Gateway_PQ35 SG_ 1404 BY1_KD_Fehler 5000;
BA_REL_ "GenSigTimeoutTime" BU_SG_REL_ Getriebe_DQ SG_ 416 BR1_ASR_Anf 500;
BA_REL_ "GenSigTimeoutTime" BU_SG_REL_ Getriebe_DQ_Hyb SG_ 416 BR1_ASR_Anf 500;
BA_REL_ "GenSigTimeoutTime" BU_SG_REL_ LH_EPS_APA SG_ 416 BR1_ASR_Anf 500;
BA_REL_ "GenSigTimeoutTime" BU_SG_REL_ Motor_Diesel SG_ 416 BR1_ASR_Anf 500;
BA_REL_ "GenSigTimeoutTime" BU_SG_REL_ Motor_Hybrid SG_ 416 BR1_ASR_Anf 500;
BA_REL_ "GenSigTimeoutTime" BU_SG_REL_ Motor_Otto SG_ 416 BR1_ASR_Anf 500;
BA_REL_ "GenSigTimeoutTime" BU_SG_REL_ PDC_PLA SG_ 416 BR1_ASR_Anf 500;
BA_REL_ "GenSigTimeoutTime" BU_SG_REL_ RKA_Plus SG_ 416 BR1_ASR_Anf 500;
BA_REL_ "GenSigTimeoutTime" BU_SG_REL_ Getriebe_DQ SG_ 416 BR1_MSR_Anf 500;
BA_REL_ "GenSigTimeoutTime" BU_SG_REL_ Getriebe_DQ_Hyb SG_ 416 BR1_MSR_Anf 500;
BA_REL_ "GenSigTimeoutTime" BU_SG_REL_ LH_EPS_APA SG_ 416 BR1_MSR_Anf 500;
BA_REL_ "GenSigTimeoutTime" BU_SG_REL_ Motor_Diesel SG_ 416 BR1_MSR_Anf 500;
BA_REL_ "GenSigTimeoutTime" BU_SG_REL_ Motor_Hybrid SG_ 416 BR1_MSR_Anf 500;
BA_REL_ "GenSigTimeoutTime" BU_SG_REL_ Motor_Otto SG_ 416 BR1_MSR_Anf 500;
BA_REL_ "GenSigTimeoutTime" BU_SG_REL_ PDC_PLA SG_ 416 BR1_MSR_Anf 500;
BA_REL_ "GenSigTimeoutTime" BU_SG_REL_ RKA_Plus SG_ 416 BR1_MSR_Anf 500;
BA_REL_ "GenSigTimeoutTime" BU_SG_REL_ Allrad SG_ 416 BR1_ABS_Brems 500;
BA_REL_ "GenSigTimeoutTime" BU_SG_REL_ Daempfer SG_ 416 BR1_ABS_Brems 500;
BA_REL_ "GenSigTimeoutTime" BU_SG_REL_ EPB_TRW SG_ 416 BR1_ABS_Brems 500;
BA_REL_ "GenSigTimeoutTime" BU_SG_REL_ EPB_TRW_VW411CS SG_ 416 BR1_ABS_Brems 500;
BA_REL_ "GenSigTimeoutTime" BU_SG_REL_ Gateway_PQ35 SG_ 416 BR1_ABS_Brems 500;
BA_REL_ "GenSigTimeoutTime" BU_SG_REL_ Getriebe_DQ SG_ 416 BR1_ABS_Brems 500;
BA_REL_ "GenSigTimeoutTime" BU_SG_REL_ Getriebe_DQ_Hyb SG_ 416 BR1_ABS_Brems 500;
BA_REL_ "GenSigTimeoutTime" BU_SG_REL_ HCA SG_ 416 BR1_ABS_Brems 500;
BA_REL_ "GenSigTimeoutTime" BU_SG_REL_ LH_EPS_APA SG_ 416 BR1_ABS_Brems 500;
BA_REL_ "GenSigTimeoutTime" BU_SG_REL_ Magne_Ride SG_ 416 BR1_ABS_Brems 500;
BA_REL_ "GenSigTimeoutTime" BU_SG_REL_ Motor_Diesel SG_ 416 BR1_ABS_Brems 500;
BA_REL_ "GenSigTimeoutTime" BU_SG_REL_ Motor_Hybrid SG_ 416 BR1_ABS_Brems 500;
BA_REL_ "GenSigTimeoutTime" BU_SG_REL_ Motor_Otto SG_ 416 BR1_ABS_Brems 500;
BA_REL_ "GenSigTimeoutTime" BU_SG_REL_ PDC_PLA SG_ 416 BR1_ABS_Brems 500;
BA_REL_ "GenSigTimeoutTime" BU_SG_REL_ RKA_Plus SG_ 416 BR1_ABS_Brems 500;
BA_REL_ "GenSigTimeoutTime" BU_SG_REL_ Daempfer SG_ 416 BR1_EDS_Eingr 500;
BA_REL_ "GenSigTimeoutTime" BU_SG_REL_ Getriebe_DQ SG_ 416 BR1_EDS_Eingr 500;
BA_REL_ "GenSigTimeoutTime" BU_SG_REL_ Getriebe_DQ_Hyb SG_ 416 BR1_EDS_Eingr 500;
BA_REL_ "GenSigTimeoutTime" BU_SG_REL_ LH_EPS_APA SG_ 416 BR1_EDS_Eingr 500;
BA_REL_ "GenSigTimeoutTime" BU_SG_REL_ Motor_Diesel SG_ 416 BR1_EDS_Eingr 500;
BA_REL_ "GenSigTimeoutTime" BU_SG_REL_ Motor_Hybrid SG_ 416 BR1_EDS_Eingr 500;
BA_REL_ "GenSigTimeoutTime" BU_SG_REL_ Motor_Otto SG_ 416 BR1_EDS_Eingr 500;
BA_REL_ "GenSigTimeoutTime" BU_SG_REL_ PDC_PLA SG_ 416 BR1_EDS_Eingr 500;
BA_REL_ "GenSigTimeoutTime" BU_SG_REL_ RKA_Plus SG_ 416 BR1_EDS_Eingr 500;
BA_REL_ "GenSigTimeoutTime" BU_SG_REL_ AFS SG_ 416 BR1_ESP_Eingr 500;
BA_REL_ "GenSigTimeoutTime" BU_SG_REL_ Allrad SG_ 416 BR1_ESP_Eingr 500;
BA_REL_ "GenSigTimeoutTime" BU_SG_REL_ Daempfer SG_ 416 BR1_ESP_Eingr 500;
BA_REL_ "GenSigTimeoutTime" BU_SG_REL_ Gateway_PQ35 SG_ 416 BR1_ESP_Eingr 500;
BA_REL_ "GenSigTimeoutTime" BU_SG_REL_ Gateway_PQ35 SG_ 416 BR1_ESP_Eingr 500;
BA_REL_ "GenSigTimeoutTime" BU_SG_REL_ Getriebe_AG6 SG_ 416 BR1_ESP_Eingr 500;
BA_REL_ "GenSigTimeoutTime" BU_SG_REL_ Getriebe_DQ SG_ 416 BR1_ESP_Eingr 500;
BA_REL_ "GenSigTimeoutTime" BU_SG_REL_ Getriebe_DQ_Hyb SG_ 416 BR1_ESP_Eingr 500;
BA_REL_ "GenSigTimeoutTime" BU_SG_REL_ Getriebe_Sele SG_ 416 BR1_ESP_Eingr 500;
BA_REL_ "GenSigTimeoutTime" BU_SG_REL_ HCA SG_ 416 BR1_ESP_Eingr 500;
BA_REL_ "GenSigTimeoutTime" BU_SG_REL_ LH_EPS_APA SG_ 416 BR1_ESP_Eingr 500;
BA_REL_ "GenSigTimeoutTime" BU_SG_REL_ LH_EPS_ZF_2G SG_ 416 BR1_ESP_Eingr 500;
BA_REL_ "GenSigTimeoutTime" BU_SG_REL_ LH_EPS_ZF_3G SG_ 416 BR1_ESP_Eingr 500;
BA_REL_ "GenSigTimeoutTime" BU_SG_REL_ Motor_Diesel SG_ 416 BR1_ESP_Eingr 500;
BA_REL_ "GenSigTimeoutTime" BU_SG_REL_ Motor_Hybrid SG_ 416 BR1_ESP_Eingr 500;
BA_REL_ "GenSigTimeoutTime" BU_SG_REL_ Motor_Otto SG_ 416 BR1_ESP_Eingr 500;
BA_REL_ "GenSigTimeoutTime" BU_SG_REL_ PDC_PLA SG_ 416 BR1_ESP_Eingr 500;
BA_REL_ "GenSigTimeoutTime" BU_SG_REL_ RKA_Plus SG_ 416 BR1_ESP_Eingr 500;
BA_REL_ "GenSigTimeoutTime" BU_SG_REL_ Getriebe_AG6 SG_ 416 BR1_ASR_Eingr 500;
BA_REL_ "GenSigTimeoutTime" BU_SG_REL_ Getriebe_DQ SG_ 416 BR1_ASR_Eingr 500;
BA_REL_ "GenSigTimeoutTime" BU_SG_REL_ Getriebe_DQ_Hyb SG_ 416 BR1_ASR_Eingr 500;
BA_REL_ "GenSigTimeoutTime" BU_SG_REL_ LH_EPS_APA SG_ 416 BR1_ASR_Eingr 500;
BA_REL_ "GenSigTimeoutTime" BU_SG_REL_ Daempfer SG_ 416 BR1_EBV_Eingr 500;
BA_REL_ "GenSigTimeoutTime" BU_SG_REL_ LH_EPS_APA SG_ 416 BR1_EBV_Eingr 500;
BA_REL_ "GenSigTimeoutTime" BU_SG_REL_ RKA_Plus SG_ 416 BR1_EBV_Eingr 500;
BA_REL_ "GenSigTimeoutTime" BU_SG_REL_ AFS SG_ 416 BR1_Lichtschalt 500;
BA_REL_ "GenSigTimeoutTime" BU_SG_REL_ Gateway_PQ35 SG_ 416 BR1_Lichtschalt 500;
BA_REL_ "GenSigTimeoutTime" BU_SG_REL_ LH_EPS_APA SG_ 416 BR1_Lichtschalt 500;
BA_REL_ "GenSigTimeoutTime" BU_SG_REL_ LH_EPS_ZF_2G SG_ 416 BR1_Lichtschalt 500;
BA_REL_ "GenSigTimeoutTime" BU_SG_REL_ LH_EPS_ZF_3G SG_ 416 BR1_Lichtschalt 500;
BA_REL_ "GenSigTimeoutTime" BU_SG_REL_ LWR SG_ 416 BR1_Lichtschalt 500;
BA_REL_ "GenSigTimeoutTime" BU_SG_REL_ Motor_Diesel SG_ 416 BR1_Lichtschalt 500;
BA_REL_ "GenSigTimeoutTime" BU_SG_REL_ Motor_Hybrid SG_ 416 BR1_Lichtschalt 500;
BA_REL_ "GenSigTimeoutTime" BU_SG_REL_ Motor_Otto SG_ 416 BR1_Lichtschalt 500;
BA_REL_ "GenSigTimeoutTime" BU_SG_REL_ RKA_Plus SG_ 416 BR1_Lichtschalt 500;
BA_REL_ "GenSigTimeoutTime" BU_SG_REL_ Motor_Diesel SG_ 416 BR1_StaDruckschw 500;
BA_REL_ "GenSigTimeoutTime" BU_SG_REL_ Motor_Hybrid SG_ 416 BR1_StaDruckschw 500;
BA_REL_ "GenSigTimeoutTime" BU_SG_REL_ Motor_Otto SG_ 416 BR1_StaDruckschw 500;
BA_REL_ "GenSigTimeoutTime" BU_SG_REL_ Airbag SG_ 416 BR1_Diagnose 500;
BA_REL_ "GenSigTimeoutTime" BU_SG_REL_ Motor_Diesel SG_ 416 BR1_BKV_aktiv 500;
BA_REL_ "GenSigTimeoutTime" BU_SG_REL_ Motor_Hybrid SG_ 416 BR1_BKV_aktiv 500;
BA_REL_ "GenSigTimeoutTime" BU_SG_REL_ Motor_Otto SG_ 416 BR1_BKV_aktiv 500;
BA_REL_ "GenSigTimeoutTime" BU_SG_REL_ Airbag SG_ 416 BR1_Rad_kmh 500;
BA_REL_ "GenSigTimeoutTime" BU_SG_REL_ BMS_Hybrid SG_ 416 BR1_Rad_kmh 500;
BA_REL_ "GenSigTimeoutTime" BU_SG_REL_ Daempfer SG_ 416 BR1_Rad_kmh 500;
BA_REL_ "GenSigTimeoutTime" BU_SG_REL_ FLA SG_ 416 BR1_Rad_kmh 500;
BA_REL_ "GenSigTimeoutTime" BU_SG_REL_ Gateway_PQ35 SG_ 416 BR1_Rad_kmh 500;
BA_REL_ "GenSigTimeoutTime" BU_SG_REL_ Gateway_PQ35 SG_ 416 BR1_Rad_kmh 500;
BA_REL_ "GenSigTimeoutTime" BU_SG_REL_ Gateway_PQ35 SG_ 416 BR1_Rad_kmh 500;
BA_REL_ "GenSigTimeoutTime" BU_SG_REL_ Getriebe_AG6 SG_ 416 BR1_Rad_kmh 500;
BA_REL_ "GenSigTimeoutTime" BU_SG_REL_ Getriebe_DQ SG_ 416 BR1_Rad_kmh 500;
BA_REL_ "GenSigTimeoutTime" BU_SG_REL_ Getriebe_DQ_Hyb SG_ 416 BR1_Rad_kmh 500;
BA_REL_ "GenSigTimeoutTime" BU_SG_REL_ Getriebe_Sele SG_ 416 BR1_Rad_kmh 500;
BA_REL_ "GenSigTimeoutTime" BU_SG_REL_ HCA SG_ 416 BR1_Rad_kmh 500;
BA_REL_ "GenSigTimeoutTime" BU_SG_REL_ LEH_Hybrid SG_ 416 BR1_Rad_kmh 500;
BA_REL_ "GenSigTimeoutTime" BU_SG_REL_ LH_EPS_APA SG_ 416 BR1_Rad_kmh 500;
BA_REL_ "GenSigTimeoutTime" BU_SG_REL_ LH_EPS_ZF_2G SG_ 416 BR1_Rad_kmh 500;
BA_REL_ "GenSigTimeoutTime" BU_SG_REL_ LH_EPS_ZF_3G SG_ 416 BR1_Rad_kmh 500;
BA_REL_ "GenSigTimeoutTime" BU_SG_REL_ Magne_Ride SG_ 416 BR1_Rad_kmh 500;
BA_REL_ "GenSigTimeoutTime" BU_SG_REL_ Motor_Diesel SG_ 416 BR1_Rad_kmh 500;
BA_REL_ "GenSigTimeoutTime" BU_SG_REL_ Motor_Hybrid SG_ 416 BR1_Rad_kmh 500;
BA_REL_ "GenSigTimeoutTime" BU_SG_REL_ Motor_Otto SG_ 416 BR1_Rad_kmh 500;
BA_REL_ "GenSigTimeoutTime" BU_SG_REL_ PDC_PLA SG_ 416 BR1_Rad_kmh 500;
BA_REL_ "GenSigTimeoutTime" BU_SG_REL_ Motor_Hybrid SG_ 416 BR1_ASRMo_sl 500;
BA_REL_ "GenSigTimeoutTime" BU_SG_REL_ Motor_Otto SG_ 416 BR1_ASRMo_sl 500;
BA_REL_ "GenSigTimeoutTime" BU_SG_REL_ Motor_Diesel SG_ 416 BR1_ASRMo_fa 500;
BA_REL_ "GenSigTimeoutTime" BU_SG_REL_ Motor_Hybrid SG_ 416 BR1_ASRMo_fa 500;
BA_REL_ "GenSigTimeoutTime" BU_SG_REL_ Motor_Otto SG_ 416 BR1_ASRMo_fa 500;
BA_REL_ "GenSigTimeoutTime" BU_SG_REL_ Motor_Diesel SG_ 416 BR1_MSR_Mo_inv 500;
BA_REL_ "GenSigTimeoutTime" BU_SG_REL_ Motor_Hybrid SG_ 416 BR1_MSR_Mo_inv 500;
BA_REL_ "GenSigTimeoutTime" BU_SG_REL_ Motor_Otto SG_ 416 BR1_MSR_Mo_inv 500;
BA_REL_ "GenSigTimeoutTime" BU_SG_REL_ Motor_Diesel SG_ 416 BR1_MSR_Mo 500;
BA_REL_ "GenSigTimeoutTime" BU_SG_REL_ Motor_Hybrid SG_ 416 BR1_MSR_Mo 500;
BA_REL_ "GenSigTimeoutTime" BU_SG_REL_ Motor_Otto SG_ 416 BR1_MSR_Mo 500;
BA_REL_ "GenSigTimeoutTime" BU_SG_REL_ Airbag SG_ 416 BR1_Zaehler 500;
BA_REL_ "GenSigTimeoutTime" BU_SG_REL_ Daempfer SG_ 416 BR1_Zaehler 500;
BA_REL_ "GenSigTimeoutTime" BU_SG_REL_ EPB_TRW SG_ 416 BR1_Zaehler 500;
BA_REL_ "GenSigTimeoutTime" BU_SG_REL_ EPB_TRW_VW411CS SG_ 416 BR1_Zaehler 500;
BA_REL_ "GenSigTimeoutTime" BU_SG_REL_ Getriebe_AG6 SG_ 416 BR1_Zaehler 500;
BA_REL_ "GenSigTimeoutTime" BU_SG_REL_ HCA SG_ 416 BR1_Zaehler 500;
BA_REL_ "GenSigTimeoutTime" BU_SG_REL_ LH_EPS_APA SG_ 416 BR1_Zaehler 500;
BA_REL_ "GenSigTimeoutTime" BU_SG_REL_ LH_EPS_ZF_2G SG_ 416 BR1_Zaehler 500;
BA_REL_ "GenSigTimeoutTime" BU_SG_REL_ LH_EPS_ZF_3G SG_ 416 BR1_Zaehler 500;
BA_REL_ "GenSigTimeoutTime" BU_SG_REL_ Magne_Ride SG_ 416 BR1_Zaehler 500;
BA_REL_ "GenSigTimeoutTime" BU_SG_REL_ Motor_Diesel SG_ 416 BR1_Zaehler 500;
BA_REL_ "GenSigTimeoutTime" BU_SG_REL_ Motor_Hybrid SG_ 416 BR1_Zaehler 500;
BA_REL_ "GenSigTimeoutTime" BU_SG_REL_ Motor_Otto SG_ 416 BR1_Zaehler 500;
BA_REL_ "GenSigTimeoutTime" BU_SG_REL_ PDC_PLA SG_ 416 BR1_Zaehler 500;
BA_REL_ "GenSigTimeoutTime" BU_SG_REL_ Gateway_PQ35 SG_ 416 BR1_ESPASR_passiv 500;
BA_REL_ "GenSigTimeoutTime" BU_SG_REL_ Getriebe_DQ SG_ 416 BR1_ESPASR_passiv 500;
BA_REL_ "GenSigTimeoutTime" BU_SG_REL_ Getriebe_DQ_Hyb SG_ 416 BR1_ESPASR_passiv 500;
BA_REL_ "GenSigTimeoutTime" BU_SG_REL_ Getriebe_Sele SG_ 416 BR1_ESPASR_passiv 500;
BA_REL_ "GenSigTimeoutTime" BU_SG_REL_ HCA SG_ 416 BR1_ESPASR_passiv 500;
BA_REL_ "GenSigTimeoutTime" BU_SG_REL_ Magne_Ride SG_ 416 BR1_ESPASR_passiv 500;
BA_REL_ "GenSigTimeoutTime" BU_SG_REL_ Motor_Diesel SG_ 416 BR1_ESPASR_passiv 500;
BA_REL_ "GenSigTimeoutTime" BU_SG_REL_ Motor_Otto SG_ 416 BR1_ESPASR_passiv 500;
BA_REL_ "GenSigTimeoutTime" BU_SG_REL_ PDC_PLA SG_ 416 BR1_ESPASR_passiv 500;
BA_REL_ "GenSigTimeoutTime" BU_SG_REL_ Getriebe_AG6 SG_ 416 BR1_Sta_ESP 500;
BA_REL_ "GenSigTimeoutTime" BU_SG_REL_ Getriebe_DQ SG_ 416 BR1_Sta_ESP 500;
BA_REL_ "GenSigTimeoutTime" BU_SG_REL_ Getriebe_DQ_Hyb SG_ 416 BR1_Sta_ESP 500;
BA_REL_ "GenSigTimeoutTime" BU_SG_REL_ Magne_Ride SG_ 416 BR1_Sta_ESP 500;
BA_REL_ "GenSigTimeoutTime" BU_SG_REL_ Motor_Diesel SG_ 416 BR1_Sta_ESP 500;
BA_REL_ "GenSigTimeoutTime" BU_SG_REL_ Motor_Otto SG_ 416 BR1_Sta_ESP 500;
BA_REL_ "GenSigTimeoutTime" BU_SG_REL_ PDC_PLA SG_ 416 BR1_Sta_ESP 500;
BA_REL_ "GenSigTimeoutTime" BU_SG_REL_ RKA_Plus SG_ 416 BR1_Sta_ESP 500;
BA_REL_ "GenSigTimeoutTime" BU_SG_REL_ Airbag SG_ 416 BR1_Ersatz_Kmh 500;
BA_REL_ "GenSigTimeoutTime" BU_SG_REL_ HCA SG_ 416 BR1_Ersatz_Kmh 500;
BA_REL_ "GenSigTimeoutTime" BU_SG_REL_ LH_EPS_APA SG_ 416 BR1_Ersatz_Kmh 500;
BA_REL_ "GenSigTimeoutTime" BU_SG_REL_ LH_EPS_ZF_2G SG_ 416 BR1_Ersatz_Kmh 500;
BA_REL_ "GenSigTimeoutTime" BU_SG_REL_ LH_EPS_ZF_3G SG_ 416 BR1_Ersatz_Kmh 500;
BA_REL_ "GenSigTimeoutTime" BU_SG_REL_ PDC_PLA SG_ 416 BR1_Ersatz_Kmh 500;
BA_REL_ "GenSigTimeoutTime" BU_SG_REL_ Motor_Diesel SG_ 928 B10_Checksumme 500;
BA_REL_ "GenSigTimeoutTime" BU_SG_REL_ Motor_Otto SG_ 928 B10_Checksumme 500;
BA_REL_ "GenSigTimeoutTime" BU_SG_REL_ PDC_PLA SG_ 928 B10_Checksumme 500;
BA_REL_ "GenSigTimeoutTime" BU_SG_REL_ Motor_Diesel SG_ 928 B10_Zaehler 500;
BA_REL_ "GenSigTimeoutTime" BU_SG_REL_ Motor_Otto SG_ 928 B10_Zaehler 500;
BA_REL_ "GenSigTimeoutTime" BU_SG_REL_ PDC_PLA SG_ 928 B10_Zaehler 500;
BA_REL_ "GenSigTimeoutTime" BU_SG_REL_ Motor_Diesel SG_ 928 B10_QB_Wegimp_VL 500;
BA_REL_ "GenSigTimeoutTime" BU_SG_REL_ Motor_Otto SG_ 928 B10_QB_Wegimp_VL 500;
BA_REL_ "GenSigTimeoutTime" BU_SG_REL_ PDC_PLA SG_ 928 B10_QB_Wegimp_VL 500;
BA_REL_ "GenSigTimeoutTime" BU_SG_REL_ Motor_Diesel SG_ 928 B10_QB_Wegimp_VR 500;
BA_REL_ "GenSigTimeoutTime" BU_SG_REL_ Motor_Otto SG_ 928 B10_QB_Wegimp_VR 500;
BA_REL_ "GenSigTimeoutTime" BU_SG_REL_ PDC_PLA SG_ 928 B10_QB_Wegimp_VR 500;
BA_REL_ "GenSigTimeoutTime" BU_SG_REL_ Motor_Diesel SG_ 928 B10_QB_Wegimp_HL 500;
BA_REL_ "GenSigTimeoutTime" BU_SG_REL_ Motor_Otto SG_ 928 B10_QB_Wegimp_HL 500;
BA_REL_ "GenSigTimeoutTime" BU_SG_REL_ PDC_PLA SG_ 928 B10_QB_Wegimp_HL 500;
BA_REL_ "GenSigTimeoutTime" BU_SG_REL_ Motor_Diesel SG_ 928 B10_QB_Wegimp_HR 500;
BA_REL_ "GenSigTimeoutTime" BU_SG_REL_ Motor_Otto SG_ 928 B10_QB_Wegimp_HR 500;
BA_REL_ "GenSigTimeoutTime" BU_SG_REL_ PDC_PLA SG_ 928 B10_QB_Wegimp_HR 500;
BA_REL_ "GenSigTimeoutTime" BU_SG_REL_ Motor_Diesel SG_ 928 B10_Wegimp_VL 500;
BA_REL_ "GenSigTimeoutTime" BU_SG_REL_ Motor_Otto SG_ 928 B10_Wegimp_VL 500;
BA_REL_ "GenSigTimeoutTime" BU_SG_REL_ PDC_PLA SG_ 928 B10_Wegimp_VL 500;
BA_REL_ "GenSigTimeoutTime" BU_SG_REL_ Motor_Diesel SG_ 928 B10_Wegimp_VR 500;
BA_REL_ "GenSigTimeoutTime" BU_SG_REL_ Motor_Otto SG_ 928 B10_Wegimp_VR 500;
BA_REL_ "GenSigTimeoutTime" BU_SG_REL_ PDC_PLA SG_ 928 B10_Wegimp_VR 500;
BA_REL_ "GenSigTimeoutTime" BU_SG_REL_ Motor_Diesel SG_ 928 B10_Wegimp_HL 500;
BA_REL_ "GenSigTimeoutTime" BU_SG_REL_ Motor_Otto SG_ 928 B10_Wegimp_HL 500;
BA_REL_ "GenSigTimeoutTime" BU_SG_REL_ PDC_PLA SG_ 928 B10_Wegimp_HL 500;
BA_REL_ "GenSigTimeoutTime" BU_SG_REL_ Motor_Diesel SG_ 928 B10_Wegimp_HR 500;
BA_REL_ "GenSigTimeoutTime" BU_SG_REL_ Motor_Otto SG_ 928 B10_Wegimp_HR 500;
BA_REL_ "GenSigTimeoutTime" BU_SG_REL_ PDC_PLA SG_ 928 B10_Wegimp_HR 500;
BA_REL_ "GenSigTimeoutTime" BU_SG_REL_ PDC_PLA SG_ 928 B10_QB_Fahrtr_VL 500;
BA_REL_ "GenSigTimeoutTime" BU_SG_REL_ PDC_PLA SG_ 928 B10_QB_Fahrtr_VR 500;
BA_REL_ "GenSigTimeoutTime" BU_SG_REL_ PDC_PLA SG_ 928 B10_QB_Fahrtr_HL 500;
BA_REL_ "GenSigTimeoutTime" BU_SG_REL_ PDC_PLA SG_ 928 B10_QB_Fahrtr_HR 500;
BA_REL_ "GenSigTimeoutTime" BU_SG_REL_ PDC_PLA SG_ 928 B10_Fahrtr_VL 500;
BA_REL_ "GenSigTimeoutTime" BU_SG_REL_ PDC_PLA SG_ 928 B10_Fahrtr_VR 500;
BA_REL_ "GenSigTimeoutTime" BU_SG_REL_ PDC_PLA SG_ 928 B10_Fahrtr_HL 500;
BA_REL_ "GenSigTimeoutTime" BU_SG_REL_ PDC_PLA SG_ 928 B10_Fahrtr_HR 500;
VAL_ 946 BEM_HYB_DC_uMinLV 254 "Init" 255 "Fehler" ;
VAL_ 901 CHA_Ziel_FahrPr_MO 0 "nicht_belegt" 1 "Programm_1" 2 "Programm_2" 3 "Programm_3" 4 "Programm_4" 5 "Programm_5" 6 "Programm_6" 7 "Programm_7" ;
VAL_ 901 CHA_Ziel_FahrPr_GE 0 "nicht_belegt" 1 "Programm_1" 2 "Programm_2" 3 "Programm_3" 4 "Programm_4" 5 "Programm_5" 6 "Programm_6" 7 "Programm_7" ;
VAL_ 902 CHA_Ziel_FahrPr_KL 0 "nicht_belegt" 1 "Programm_1" 2 "Programm_2" 3 "Programm_3" 4 "Programm_4" 5 "Programm_5" 6 "Programm_6" 7 "Programm_7" ;
VAL_ 902 CHA_Kombi_Texte 0 "keine_Anzeige" 1 "Text_1" 2 "Text_2" 3 "Text_3" 4 "Text_4" 5 "Text_5" 6 "Text_6" 7 "Text_7" 8 "Text_8" 9 "Text_9" 10 "Text_10" 11 "Text_11" 12 "Text_12" 13 "Text_13" 14 "Text_14" 15 "Text_15" ;
VAL_ 945 DC_HYB_iAktLV 1022 "Init" 1023 "Fehler" ;
VAL_ 945 DC_HYB_iAktReserveLV 1022 "Init" 1023 "Fehler" ;
VAL_ 945 DC_HYB_uAktLV 254 "Init" 255 "Fehler" ;
VAL_ 945 DC_HYB_LangsRegelung 0 "normale_Regelung" 1 "langsame_Regelung" ;
VAL_ 945 DC_HYB_Abregelung_Temperatur 0 "keine_Begrenzung" 1 "Abregelung_Temperatur" ;
VAL_ 945 DC_HYB_Fehler_RedLeistung 0 "kein_Fehler" 1 "Fehler_RedLeistung" ;
VAL_ 945 DC_HYB_Fehler_intern 0 "kein_Fehler" 1 "Fehler_intern" ;
VAL_ 945 DC_HYB_Fehler_Spannung 0 "kein_Fehler" 1 "Fehler_Spannung" ;
VAL_ 945 DC_HYB_Auslastungsgrad 255 "Fehler" ;
VAL_ 19 WFS_GSG_Status_Antwort 0 "verwerfen" 1 "bewerten" ;
VAL_ 19 WFS_GSG_Status_Lesespule 0 "Fehler" 1 "kein Fehler" ;
VAL_ 19 WFS_GSG_Status_Schluessel 0 "nicht berechtigt" 1 "berechtigt" ;
VAL_ 19 WFS_GSG_Status_Anfrage 0 "n.i.O." 1 "i.O." ;
VAL_ 19 WFS_GSG_Status_P_Klasse 0 "n.i.O." 1 "i.O." ;
VAL_ 17 WFS_MSG1_Status_Antwort 0 "verwerfen" 1 "bewerten" ;
VAL_ 17 WFS_MSG1_Status_Lesespule 0 "Fehler" 1 "kein Fehler" ;
VAL_ 17 WFS_MSG1_Status_Schluessel 0 "nicht berechtigt" 1 "berechtigt" ;
VAL_ 17 WFS_MSG1_Status_Anfrage 0 "n.i.O." 1 "i.O." ;
VAL_ 17 WFS_MSG1_Status_P_Klasse 0 "n.i.O." 1 "i.O." ;
VAL_ 21 WFS_MSG2_Status_Antwort 0 "verwerfen" 1 "bewerten" ;
VAL_ 21 WFS_MSG2_Status_Lesespule 0 "Fehler" 1 "kein Fehler" ;
VAL_ 21 WFS_MSG2_Status_Schluessel 0 "nicht berechtigt" 1 "berechtigt" ;
VAL_ 21 WFS_MSG2_Status_Anfrage 0 "n.i.O." 1 "i.O." ;
VAL_ 21 WFS_MSG2_Status_P_Klasse 0 "n.i.O." 1 "i.O." ;
VAL_ 23 WFS_MSG3_Status_Antwort 0 "verwerfen" 1 "bewerten" ;
VAL_ 23 WFS_MSG3_Status_Lesespule 0 "Fehler" 1 "kein Fehler" ;
VAL_ 23 WFS_MSG3_Status_Schluessel 0 "nicht berechtigt" 1 "berechtigt" ;
VAL_ 23 WFS_MSG3_Status_Anfrage 0 "n.i.O." 1 "i.O." ;
VAL_ 23 WFS_MSG3_Status_P_Klasse 0 "n.i.O." 1 "i.O." ;
VAL_ 25 WFS_MSG4_Status_Antwort 0 "verwerfen" 1 "bewerten" ;
VAL_ 25 WFS_MSG4_Status_Lesespule 0 "Fehler" 1 "kein Fehler" ;
VAL_ 25 WFS_MSG4_Status_Schluessel 0 "nicht berechtigt" 1 "berechtigt" ;
VAL_ 25 WFS_MSG4_Status_Anfrage 0 "n.i.O." 1 "i.O." ;
VAL_ 25 WFS_MSG4_Status_P_Klasse 0 "n.i.O." 1 "i.O." ;
VAL_ 1386 ACA_StaACC 0 "Hauptschalter_aus" 1 "Reserve" 2 "ACC_passiv" 3 "ACC_aktiv" 4 "ACC_im_Hintergrund" 5 "frei" 6 "ACC_rev_aus" 7 "ACC_irrev_aus" ;
VAL_ 1386 ACA_ID_StaACC 0 "keine_Anzeige" ;
VAL_ 1386 ACA_Fahrerhinw 0 "Aus" 1 "Ein" ;
VAL_ 1386 ACA_AnzDisplay 0 "Anzeige_nicht_erw" 1 "Anzeige_erw" ;
VAL_ 1386 ACA_Zeitluecke 0 "nicht_definiert" 1 "Zeitluecke1" 2 "Zeitluecke2" 3 "Zeitluecke3" 4 "Zeitluecke4" 5 "Zeitluecke5" 6 "Zeitluecke6" 7 "Zeitluecke7" 8 "Zeitluecke8" 9 "Zeitluecke9" 10 "Zeitluecke10" 11 "Zeitluecke11" 12 "Zeitluecke12" 13 "Zeitluecke13" 14 "Zeitluecke14" 15 "Zeitluecke15" ;
VAL_ 1386 ACA_V_Wunsch 255 "kein_Wert_im_Speicher" ;
VAL_ 1386 ACA_kmh_mph 0 "km_h" 1 "mph" ;
VAL_ 1386 ACA_Akustik1 0 "kein_Gong" 1 "Gong" ;
VAL_ 1386 ACA_Akustik2 0 "kein_Summer" 1 "Summer" ;
VAL_ 1386 ACA_PrioDisp 0 "hohe_Prio" 1 "mittlere_Prio" 2 "niedrige_Prio" 3 "keine_Anzeige_Anf" ;
VAL_ 1386 ACA_gemZeitl 0 "Kein_Objekt_erfasst" 1 "Zeitluecke1" 2 "Zeitluecke2" 3 "Zeitluecke3" 4 "Zeitluecke4" 5 "Zeitluecke5" 6 "Zeitluecke6" 7 "Zeitluecke7" 8 "Zeitluecke8" 9 "Zeitluecke9" 10 "Zeitluecke10" 11 "Zeitluecke11" 12 "Zeitluecke12" 13 "Zeitluecke13" 14 "Zeitluecke14" 15 "Zeitluecke15" ;
VAL_ 1386 ACA_ACC_Verz 0 "ACC_verzoegert_nicht" 1 "ACC_verzoegert" ;
VAL_ 1386 ACA_StaGRA 0 "Hauptschalter_aus" 1 "Reserve" 2 "GRA_passiv" 3 "GRA_aktiv" 4 "GRA_uebertreten" 5 "frei" 6 "frei" 7 "GRA_Fehler" ;
VAL_ 1386 ACA_ID_StaGRA 0 "keine_Anzeige" ;
VAL_ 1386 ACA_Codierung 0 "ACC" 1 "GRA" ;
VAL_ 1386 ACA_Tachokranz 0 "nicht_beleuchtet" 1 "beleuchtet" ;
VAL_ 1386 ACA_Aend_Zeitluecke 0 "keine_Anzeige" 1 "Anzeige_angef" ;
VAL_ 872 ACS_Sta_ADR 0 "ADR_nicht_aktiv" 1 "ADR_aktiv" 2 "ADR_passiv" 3 "irrev_Fehler" ;
VAL_ 872 ACS_ADR_Schub 0 "Verz_nicht_begr_auf_Schub" 1 "Verz_begr_auf_Schub" ;
VAL_ 872 ACS_Schubabsch 0 "SA_zulaessig" 1 "SA_nicht_zulaessig" ;
VAL_ 872 ACS_StSt_Info 0 "Motorlauf_nicht_notwendig_(Stoppfreigabe)" 1 "Motoranlauf_nicht_zwingend_notwendig_(Stoppverbot,keine_Startanforderung)" 2 "Motoranlauf_zwingend_notwendig_(Startanforderung)" 3 "Systemfehler" ;
VAL_ 872 ACS_MomEingriff 0 "keine_Beeinfl_MomEingr_Mot" 1 "MomEingr_verhindern" ;
VAL_ 872 ACS_Typ_ACC 0 "Basis_ACC" 1 "ACC_mit_FollowToStop" 2 "frei" 3 "frei" ;
VAL_ 872 ACS_FreigSollB 0 "Sollbeschl_nicht_freigeg" 1 "Sollbeschl_freigeg" ;
VAL_ 872 ACS_Sollbeschl 2046 "ADR_nicht_aktiv" 2047 "Fehler" ;
VAL_ 872 ACS_Anhaltewunsch 0 "kein_Haltewunsch" 1 "Fzg_haelt_an" ;
VAL_ 872 ACS_Fehler 0 "kein_Fehlerspeichereintrag" 1 "Fehlerspeichereintrag" ;
VAL_ 872 ACS_zul_Regelabw 254 "ADR_nicht_aktiv" 255 "Fehler" ;
VAL_ 872 ACS_max_AendGrad 0 "Neutralwert" 254 "Neutralwert" 255 "Fehler" ;
VAL_ 1688 AFZ_ParaSW_L 0 "Parametrisierung_nicht_erfolgt" 1 "Parametrisierung_erfolgt" ;
VAL_ 1688 AFZ_ParaSW_R 0 "Parametrisierung_nicht_erfolgt" 1 "Parametrisierung_erfolgt" ;
VAL_ 1688 AFZ_Modus 0 "AFS_aktiv" 1 "AFS_ausgeschaltet" ;
VAL_ 1688 AFZ_Init 0 "Initlauf_nicht_erfolgt" 1 "Initlauf_erfolgt" ;
VAL_ 1688 AFZ_SafePos 0 "Sicherheitsposition_aus" 1 "Sicherheitsposition_ein" ;
VAL_ 1688 AFZ_IstPosMot_L 254 "Wert_ist_unbekannt" 255 "Fehler" ;
VAL_ 1688 AFZ_IstPosMot_R 254 "Wert_ist_unbekannt" 255 "Fehler" ;
VAL_ 1688 AFZ_Soll_EVG 254 "Wert_ist_unbekannt" 255 "Fehler" ;
VAL_ 1688 AFZ_IstDimAbLi 254 "Wert_ist_unbekannt" 255 "Fehler" ;
VAL_ 1688 AFZ_IstDimAbRe 254 "Wert_ist_unbekannt" 255 "Fehler" ;
VAL_ 1688 AFZ_StaLamp_L 0 "kein_Fehler" 1 "Fehler" ;
VAL_ 1688 AFZ_StaLamp_R 0 "kein_Fehler" 1 "Fehler" ;
VAL_ 80 AB1_Front 0 "kein_Front_Crash" 1 "Front_Crash" ;
VAL_ 80 AB1_Heck 0 "kein_Heck_Crash" 1 "Heck_Crash" ;
VAL_ 80 AB1_Fa_Seite 0 "kein_Seiten_Crash_Fahrer" 1 "Seiten_Crash_Fahrer" ;
VAL_ 80 AB1_Bf_Seite 0 "kein_Seiten_Crash_Beifahrer" 1 "Seiten_Crash_Beifahrer" ;
VAL_ 80 AB1_Rollover 0 "kein_Rollover" 1 "Rollover" ;
VAL_ 80 AB1_Intens 0 "kein_Crash" 1 "Gurtstraffer_Schw_ueberschritten" 2 "US_Schw_ueberschritten" 3 "US_Schw_ueberschritten" 4 "RDW_Schw_ueberschritten" 5 "RDW_Schw_ueberschritten" 6 "RDW_Schw_ueberschritten" 7 "RDW_Schw_ueberschritten" ;
VAL_ 80 AB1_Lampe 0 "Lampe_aus" 1 "Lampe_ein" ;
VAL_ 80 AB1_Status 0 "aktiv" 1 "deaktiviert" ;
VAL_ 80 AB1_Beifahrer 0 "aktiv" 1 "deaktiviert" ;
VAL_ 80 AB1_System 0 "kein_Fehler" 1 "Systemfehler" ;
VAL_ 80 AB1_Gurt_Fa 0 "nicht_verfuegbar" 1 "Fehler" 2 "Gurt_nicht_gesteckt" 3 "Gurt_gesteckt" ;
VAL_ 80 AB1_Gurt_Bf 0 "nicht_verfuegbar" 1 "Fehler" 2 "Gurt_nicht_gesteckt" 3 "Gurt_gesteckt" ;
VAL_ 80 AB1_Diagnose 0 "nicht_in_Diagnose" 1 "in_Diagnose" ;
VAL_ 80 AB1_Stellglied 0 "nicht_im_Stellgliedtest" 1 "im_Stellgliedtest" ;
VAL_ 80 AB1_BF_Warnung 0 "keine_Warnung" 1 "Gurtwarnung_ausloesen" ;
VAL_ 80 AB1_Fehlereintr 0 "kein_Fehlerspeichereintrag" 1 "Fehlerspeichereintrag" ;
VAL_ 1360 AB2_Beleg_HF 0 "hinten_Fahrer_nicht_verfuegbar" 1 "hinten_Fahrer_Fehler" 2 "hinten_Fahrer_nicht_belegt" 3 "hinten_Fahrer_belegt" ;
VAL_ 1360 AB2_Beleg_HBF 0 "hinten_Beif_nicht_verfuegbar" 1 "hinten_Beifahrer_Fehler" 2 "hinten_Beifahrer_nicht_belegt" 3 "hinten_Beifahrer_belegt" ;
VAL_ 1360 AB2_Beleg_HM 0 "hinten_Mitte_nicht_verfuegbar" 1 "hinten_Mitte_Fehler" 2 "hinten_Mitte_nicht_belegt" 3 "hinten_Mitte_belegt" ;
VAL_ 1360 AB2_Beleg_BF 0 "nicht_verfuegbar" 1 "Fehler" 2 "Beifahrersitz_nicht_belegt" 3 "Beifahrersitz_belegt" ;
VAL_ 1360 AB2_OOP_Fa 0 "nicht_verfuegbar" 1 "Fehler" 4 "Fahrer_in_Position" 5 "Fahrer_out_of_pos_70" 6 "Fahrer_out_of_pos_30" 7 "nicht_benutzt" ;
VAL_ 1360 AB2_OOP_BF 0 "nicht_verfuegbar" 1 "Fehler" 4 "Fahrer_in_Position" 5 "Fahrer_out_of_pos_70" 6 "Fahrer_out_of_pos_30" 7 "nicht_benutzt" ;
VAL_ 1360 AB2_Sta_BF 0 "keine_Anzeige" 1 "BF_Airbag_deaktiviert" 2 "BF_Airbag_aktiviert" 3 "nicht_benutzt" ;
VAL_ 1360 AB2_Gurt_2FaS 0 "nicht_verfuegbar" 1 "Fehler" 2 "Gurt_nicht_gesteckt" 3 "Gurt_gesteckt" ;
VAL_ 1360 AB2_Gurt_2BfS 0 "nicht_verfuegbar" 1 "Fehler" 2 "Gurt_nicht_gesteckt" 3 "Gurt_gesteckt" ;
VAL_ 1360 AB2_Gurt_2Mi 0 "nicht_verfuegbar" 1 "Fehler" 2 "Gurt_nicht_gesteckt" 3 "Gurt_gesteckt" ;
VAL_ 1360 AB2_Gurt_3FaS 0 "nicht_verfuegbar" 1 "Fehler" 2 "Gurt_nicht_gesteckt" 3 "Gurt_gesteckt" ;
VAL_ 1360 AB2_Gurt_3BfS 0 "nicht_verfuegbar" 1 "Fehler" 2 "Gurt_nicht_gesteckt" 3 "Gurt_gesteckt" ;
VAL_ 1360 AB2_Gurt_3Mi 0 "nicht_verfuegbar" 1 "Fehler" 2 "Gurt_nicht_gesteckt" 3 "Gurt_gesteckt" ;
VAL_ 704 AL1_Fehler 0 "kein_Fehler" 1 "Fehler" ;
VAL_ 704 AL1_Uebertemp 0 "keine_Uebertemperatur" 1 "Uebertemperatur" ;
VAL_ 704 AL1_Sta_Kup 0 "erfuellbar" 1 "dynamisch_nicht_erfuellbar" ;
VAL_ 704 AL1_Kup_offen 0 "Kupplung_nicht_komplett_offen" 1 "Kupplung_komplett_offen" ;
VAL_ 704 AL1_Notlauf 0 "alles_i_O" 1 "Notlaufbetrieb" ;
VAL_ 704 AL1_Warnlampe 0 "Lampe_aus" 1 "Lampe_ein" ;
VAL_ 704 AL1_Limiter 0 "keine_Begrenzung" 1 "Geschwindigkeitsbegrenzung" ;
VAL_ 704 AL1_Einheit 0 "Nm" 1 "Prozente" ;
VAL_ 704 AL1_Ist_Nm 127 "Kupplung_schnell_offen" 254 "Kupplung_ganz_geschl" 255 "Fehler" ;
VAL_ 704 AL1_Ist_Proz 127 "Kupplung_schnell_offen" 128 "Kupplung_offen_0_Prozent" 254 "Kupplung_geschl_100_Prozent" 255 "Fehler" ;
VAL_ 704 AL1_Sta_PNG 0 "Init" 1 "High_Unlock_Normal" 2 "Low_Unlock_PNG_in_LOW_Stellung" 3 "frei" 4 "Neutral" 5 "High_Lock" 6 "Low_Lock" 7 "PNG_Fehlersignal" ;
VAL_ 704 AL1_Anz_blinken 0 "kein_Blinken_der_PNG_Anzeige" 1 "Blinken_der_PNG_Anzeige" ;
VAL_ 704 AL1_Sta_Laengssp 0 "Sperre_im_Regelmodus" 1 "Sperre_vom_Fahrer_aktiviert" 2 "Fehler_Sperre" 3 "Fehler_Verteilergetriebe" ;
VAL_ 704 AL1_Sta_Quersp 0 "Sperre_im_Regelmodus" 1 "Sperre_vom_Fahrer_aktiviert" 2 "Fehler_Sperre" 3 "Fehler_Verteilergetriebe" ;
VAL_ 704 AL1_Schalten 0 "keine_Schaltung" 1 "Schaltung_laeuft" ;
VAL_ 704 AL1_Vorwarnung 0 "keine_Schaltung" 1 "Schaltung_wird_durchgefuehrt" ;
VAL_ 704 AL1_Stellung_Getr 0 "Schaltgetrieb_nicht_in_Neutrstlg" 1 "Schaltgetriebe_in_Neutralstlg" ;
VAL_ 704 AL1_AnfVerteiler 0 "keine_Anforderung" 1 "Verteiler_Anforderung" ;
VAL_ 704 AL1_Sta_VA 0 "Sperre_im_Regelmodus" 1 "Sperre_vom_Fahrer_aktiviert" 2 "Fehler_Sperre" 3 "Notlauf_VA_Sperre" ;
VAL_ 704 AL1_KupSteifig_F 0 "Kupplungssteifigkeit_unbekannt" 1 "Kupplungssteifigkeit_0_Prozent" ;
VAL_ 704 AL1_Fehlereintr 0 "kein_Fehlerspeichereintrag" 1 "Fehlerspeichereintrag" ;
VAL_ 704 AL1_KupplTemp 254 "INIT" 255 "Fehler" ;
VAL_ 704 AL1_FaWu_Laengs 0 "Kein_Fahrerwunsch" 1 "Lockwunsch_Fahrer" 3 "Fehler_Fahrwerksschalter" ;
VAL_ 704 AL1_FaWu_HA 0 "Kein_Fahrerwunsch" 1 "Lockwunsch_Fahrer" 3 "Fehler_Fahrwerksschalter" ;
VAL_ 704 AL1_FaWu_VA 0 "Kein_Fahrerwunsch" 1 "Lockwunsch_Fahrer" 3 "Fehler_Fahrwerksschalter" ;
VAL_ 704 AL1_Quersp_Sta 0 "Fehler" 1 "Diffsperre_geschl" 2 "Diffsperre_offen" 3 "Diffsperre_verfaehrt" ;
VAL_ 704 AL1_Limit_maxkmh 255 "Fehler" ;
VAL_ 704 AL1_Diff_Verbau 0 "Diffsperre_nicht_verbaut" 1 "Diffsperre_verbaut" ;
VAL_ 704 AL1_Diff_Lampe 0 "Lampe_aus" 1 "Lampe_ein" ;
VAL_ 704 AL1_Diff_Gong 0 "Gong_aus" 1 "Gong_ein" ;
VAL_ 704 AL1_Warnton 0 "kein_Warnton" 1 "Warnton" ;
VAL_ 870 AWV_Text 0 "kein_Text" 1 "FrontAssist_aus" 2 "FrontAssist_startet" 3 "FrontAssist_Warnung" 4 "FrontAssist_Sens_reinig" 5 "FrontAssist_Fehler" 6 "FrontAssist_Demo" 7 "Vorhalt" ;
VAL_ 870 AWV_1_Freigabe 0 "nicht_freigegeben" 1 "freigegeben" ;
VAL_ 870 AWV_1_Prefill 0 "keine_Prefill_Anf" 1 "Prefill_Anf" ;
VAL_ 870 AWV_1_Parameter 0 "Defaultparametersatz" 1 "Par_leicht_erh_Empf" 2 "Par_erh_Empf" 3 "Par_hoechster_Empf" ;
VAL_ 870 AWV_Halten 0 "keine_Anforderung" 1 "Anforderung_das_Fzg_im_Stillstand_zu_halten" ;
VAL_ 870 ANB_Teilbremsung_Freigabe 0 "Teilbremsung_nicht_freigegeben" 1 "Teilbremsung_freigegeben" ;
VAL_ 870 AWV_2_Status 0 "Lampe_aus" 1 "Lampe_ein" ;
VAL_ 870 AWV_2_Fehler 0 "Lampe_aus" 1 "Lampe_ein" ;
VAL_ 870 AWV_2_SU_Warnzeit 0 "frueh" 1 "normal" 2 "spaet" 3 "adaptiv" ;
VAL_ 870 AWV_2_SU_Bremsruck 0 "Bremsruck_deaktiviert" 1 "Bremsruck_aktiviert" ;
VAL_ 870 AWV_2_SU_Gong 0 "Gong_deaktiviert" 1 "Gong_aktiviert" ;
VAL_ 870 AWV_2_SU_Lampe 0 "Lampe_deaktiviert" 1 "Lampe_aktiviert" ;
VAL_ 870 AWV_2_Umfeldwarn 0 "keine_Warnung" 1 "Warnung" ;
VAL_ 870 AWV_2_Freigabe 0 "keine_Ruckfreigabe" 1 "Ruckfreigabe" ;
VAL_ 870 AWV_2_Ruckprofil 0 "kein_Ruck" ;
VAL_ 870 AWV_2_Warnton 0 "Aus" 1 "Ein" ;
VAL_ 870 AWV_2_Warnsymbol 0 "Aus" 1 "Ein" ;
VAL_ 870 AWV_Infoton 0 "Aus" 1 "Ein" ;
VAL_ 870 AWV_2_Gurtstraffer 0 "Gurt_nicht_straffen" 1 "Gurt_straffen" ;
VAL_ 870 ANB_Zielbremsung_Freigabe 0 "Zielbremsung_nicht_freigegeben" 1 "Zielbremsung_freigegeben" ;
VAL_ 870 ANB_CM_Anforderung 0 "keine_Anforderung" 1 "Anforderung_aktiv" ;
VAL_ 1404 BY1_KD_Fehler 0 "kein_Fehlerspeichereintrag" 1 "Fehlerspeichereintrag" ;
VAL_ 416 BR1_ASR_Anf 0 "keine_Anforderung" 1 "ASR_Anforderung" ;
VAL_ 416 BR1_MSR_Anf 0 "keine_Anforderung" 1 "MSR_Anforderung" ;
VAL_ 416 BR1_ABS_Brems 0 "keine_ABS_Regelung" 1 "ABS_Regelung" ;
VAL_ 416 BR1_EDS_Eingr 0 "kein_EDS_Eingriff" 1 "EDS_Eingriff" ;
VAL_ 416 BR1_ESP_Eingr 0 "kein_ESP_Eingriff" 1 "ESP_Eingriff" ;
VAL_ 416 BR1_ASR_Eingr 0 "keine_Anforderung" 1 "ASR_Schaltkennfeld" 2 "Rueckschaltung" 3 "Schaltverbot" ;
VAL_ 416 BR1_EBV_Eingr 0 "kein_EBV_Eingriff" 1 "EBV_Eingriff" ;
VAL_ 416 BR1_Lampe_ABS 0 "Lampe_aus" 1 "Lampe_ein" ;
VAL_ 416 BR1_Lampe_ASR 0 "Lampe_aus" 1 "Lampe_ein" ;
VAL_ 416 BR1_Lampe_BK 0 "Lampe_aus" 1 "Lampe_ein" ;
VAL_ 416 BR1_Lichtschalt 0 "kein_Bremsen_Schw_unterschr" 1 "Bremse_betaetigt_Schw_ueberschr" ;
VAL_ 416 BR1_StaDruckschw 0 "Sta_guel__BKV_n_angest__k_Br" 1 "Sta_n_verf__BKV_angest__Br" ;
VAL_ 416 BR1_MAD 0 "keine_Ausblendung" 1 "Ausblendung" ;
VAL_ 416 BR1_Sta_MAD 0 "gueltig" 1 "ungueltig" ;
VAL_ 416 BR1_Diagnose 0 "nein" 1 "in_Diagnose" ;
VAL_ 416 BR1_BKV_aktiv 0 "BKV_nicht_verbaut_oder_Fehler" 1 "BKV_verbaut_und_kein_Fehler" ;
VAL_ 416 BR1_Rad_kmh 32708 "Init_PQ25_35_46" 32725 "Unterspannung" 32742 "Sensorfehler" ;
VAL_ 416 BR1_ASRMo_sl 255 "Fehler" ;
VAL_ 416 BR1_ASRMo_fa 255 "Fehler" ;
VAL_ 416 BR1_MSR_Mo 255 "Fehler" ;
VAL_ 416 BR1_ASR_ESP 0 "ABS_ABS_EDS" 1 "ASR_ESP_MABS" ;
VAL_ 416 BR1_ESPASR_passiv 0 "ESP_ASR_aktiviert" 1 "ESP_oder_ASR_passiv_get_oder_Fktumsch_oder_Rollenmodus" ;
VAL_ 416 BR1_Sta_ESP 0 "ok" 1 "Fehler" ;
VAL_ 416 BR1_Ersatz_Kmh 0 "i_O" 1 "Ersatzwert" ;
VAL_ 928 B10_QB_Wegimp_VL 0 "gueltiger_Wert" 1 "Ersatz_Init_oder_Fehlerwert" ;
VAL_ 928 B10_QB_Wegimp_VR 0 "gueltiger_Wert" 1 "Ersatz_Init_oder_Fehlerwert" ;
VAL_ 928 B10_QB_Wegimp_HL 0 "gueltiger_Wert" 1 "Ersatz_Init_oder_Fehlerwert" ;
VAL_ 928 B10_QB_Wegimp_HR 0 "gueltiger_Wert" 1 "Ersatz_Init_oder_Fehlerwert" ;
VAL_ 928 B10_Wegimp_VL 1021 "Initwert" 1022 "Unterspannung" 1023 "Sensorfehler" ;
VAL_ 928 B10_Wegimp_VR 1021 "Initwert" 1022 "Unterspannung" 1023 "Sensorfehler" ;
VAL_ 928 B10_Wegimp_HL 1021 "Initwert" 1022 "Unterspannung" 1023 "Sensorfehler" ;
VAL_ 928 B10_Wegimp_HR 1021 "Initwert" 1022 "Unterspannung" 1023 "Sensorfehler" ;
VAL_ 928 B10_QB_Fahrtr_VL 0 "gueltiger_Wert" 1 "Ersatz_Init_oder_Fehlerwert" ;
VAL_ 928 B10_QB_Fahrtr_VR 0 "gueltiger_Wert" 1 "Ersatz_Init_oder_Fehlerwert" ;
VAL_ 928 B10_QB_Fahrtr_HL 0 "gueltiger_Wert" 1 "Ersatz_Init_oder_Fehlerwert" ;
VAL_ 928 B10_QB_Fahrtr_HR 0 "gueltiger_Wert" 1 "Ersatz_Init_oder_Fehlerwert" ;
VAL_ 928 B10_Fahrtr_VL 0 "Vorwaerts" 1 "Rueckwaerts" ;
VAL_ 928 B10_Fahrtr_VR 0 "Vorwaerts" 1 "Rueckwaerts" ;
VAL_ 928 B10_Fahrtr_HL 0 "Vorwaerts" 1 "Rueckwaerts" ;
VAL_ 928 B10_Fahrtr_HR 0 "Vorwaerts" 1 "Rueckwaerts" ;
